VERSION "dbc-export 1 2026.26.6.5"

NS_ :

BS_:

BU_: ADSP APB APP APS APSB BB BMS CC CMP CMPD CP DAS DI DIF DIR DPB EPAS3P EPAS3S EPASTP EPASTS EPBL EPBR ESP EVSE FC GTW HCML HCMR HVP IBST ICR IDB LS OCS1P PARK PCS PCS2 PM PMF PMR PNCD PTC RADC RCM RCM2 RCM3 RCU SCCM SCM SCS SDCR TAS TCU TCU2 TPMS TRCM UI UIS UMC USM V2G VC VCBATT VCBATT0 VCBATT1 VCBATT2 VCCC VCFRONT VCFRONT1 VCFRONT2 VCLEFT VCRIGHT VCSEAT2L VCSEAT2R VCSEC VEH

BO_ 659 UI_chassisControl: 8 UI
 SG_ UI_steeringTuneRequest : 0|2@1+ (1,0) [0|3] "" Vector__XXX
 SG_ UI_tractionControlMode : 2|3@1+ (1,0) [0|7] "" Vector__XXX
 SG_ UI_parkBrakeRequest : 5|2@1+ (1,0) [0|3] "" Vector__XXX
 SG_ UI_narrowGarages : 7|1@1+ (1,0) [0|1] "" Vector__XXX
 SG_ UI_winchModeRequest : 8|2@1+ (1,0) [0|3] "" Vector__XXX
 SG_ UI_zeroSpeedConfirmed : 10|2@1+ (1,0) [0|3] "" Vector__XXX
 SG_ UI_trailerMode : 12|1@1+ (1,0) [0|1] "" Vector__XXX
 SG_ UI_distanceUnits : 13|1@1+ (1,0) [0|1] "" Vector__XXX
 SG_ UI_dasDebugEnable : 14|1@1+ (1,0) [0|1] "" Vector__XXX
 SG_ UI_accOvertakeEnable : 16|2@1+ (1,0) [0|3] "" Vector__XXX
 SG_ UI_aebEnable : 18|2@1+ (1,0) [0|3] "" Vector__XXX
 SG_ UI_aesEnable : 20|2@1+ (1,0) [0|3] "" Vector__XXX
 SG_ UI_ahlbEnable : 22|2@1+ (1,0) [0|3] "" Vector__XXX
 SG_ UI_autoLaneChangeEnable : 24|2@1+ (1,0) [0|3] "" Vector__XXX
 SG_ UI_winchProxUserOverride : 26|1@1+ (1,0) [0|1] "" Vector__XXX
 SG_ UI_rebootAutopilot : 27|1@1+ (1,0) [0|1] "" Vector__XXX
 SG_ UI_autoParkRequest : 28|4@1+ (1,0) [0|15] "" Vector__XXX
 SG_ UI_bsdEnable : 32|2@1+ (1,0) [0|3] "" Vector__XXX
 SG_ UI_fcwEnable : 34|2@1+ (1,0) [0|3] "" Vector__XXX
 SG_ UI_fcwSensitivity : 36|2@1+ (1,0) [0|3] "" Vector__XXX
 SG_ UI_latControlEnable : 38|2@1+ (1,0) [0|3] "" Vector__XXX
 SG_ UI_ldwEnable : 40|2@1+ (1,0) [0|3] "" Vector__XXX
 SG_ UI_pedalSafetyEnable : 42|2@1+ (1,0) [0|3] "" Vector__XXX
 SG_ UI_pedalMap_epas : 44|2@1+ (1,0) [0|3] "" Vector__XXX
 SG_ UI_redLightStopSignEnable : 46|2@1+ (1,0) [0|3] "" Vector__XXX
 SG_ UI_selfParkTune : 48|4@1+ (1,0) [0|15] "" Vector__XXX
 SG_ UI_chassisControlCounter : 52|4@1+ (1,0) [0|15] "" Vector__XXX
 SG_ UI_chassisControlChecksum : 56|8@1+ (1,0) [0|255] "" Vector__XXX

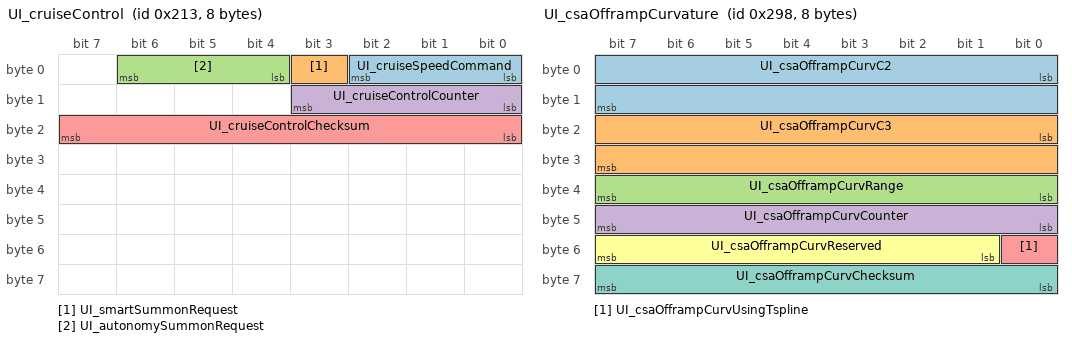
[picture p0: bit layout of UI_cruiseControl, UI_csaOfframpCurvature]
BO_ 531 UI_cruiseControl: 8 UI
 SG_ UI_cruiseSpeedCommand : 0|3@1+ (1,0) [0|7] "" Vector__XXX
 SG_ UI_smartSummonRequest : 3|1@1+ (1,0) [0|1] "" Vector__XXX
 SG_ UI_autonomySummonRequest : 4|3@1+ (1,0) [0|7] "" Vector__XXX
 SG_ UI_cruiseControlCounter : 8|4@1+ (1,0) [0|15] "" Vector__XXX
 SG_ UI_cruiseControlChecksum : 16|8@1+ (1,0) [0|255] "" Vector__XXX

BO_ 664 UI_csaOfframpCurvature: 8 UI
 SG_ UI_csaOfframpCurvC2 : 0|16@1- (1.0e-06,0) [-0.032768|0.032767] "" Vector__XXX
 SG_ UI_csaOfframpCurvC3 : 16|16@1- (4.0e-09,0) [-0.000131072|0.000131068] "" Vector__XXX
 SG_ UI_csaOfframpCurvRange : 32|8@1+ (2,0) [0|510] "" Vector__XXX
 SG_ UI_csaOfframpCurvCounter : 40|8@1+ (1,0) [0|255] "" Vector__XXX
 SG_ UI_csaOfframpCurvUsingTspline : 48|1@1+ (1,0) [0|1] "" Vector__XXX
 SG_ UI_csaOfframpCurvReserved : 49|7@1+ (1,0) [0|127] "" Vector__XXX
 SG_ UI_csaOfframpCurvChecksum : 56|8@1+ (1,0) [0|255] "" Vector__XXX

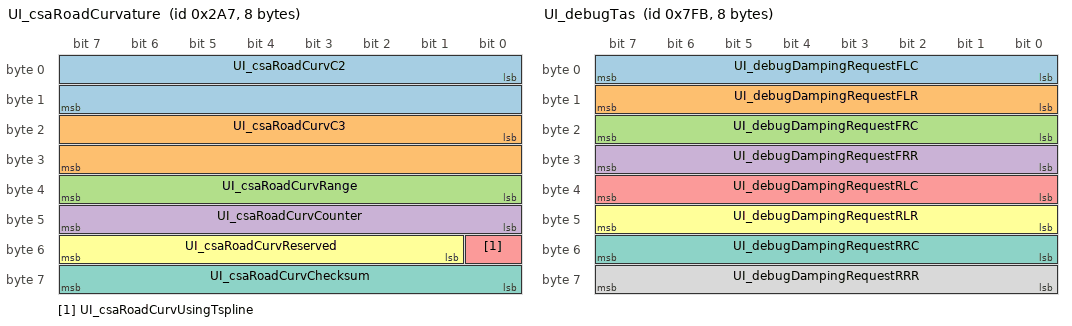
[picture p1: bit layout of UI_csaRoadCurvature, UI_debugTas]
BO_ 679 UI_csaRoadCurvature: 8 UI
 SG_ UI_csaRoadCurvC2 : 0|16@1- (1.0e-06,0) [-0.032768|0.032767] "" Vector__XXX
 SG_ UI_csaRoadCurvC3 : 16|16@1- (4.0e-09,0) [-0.000131072|0.000131068] "" Vector__XXX
 SG_ UI_csaRoadCurvRange : 32|8@1+ (2,0) [0|510] "" Vector__XXX
 SG_ UI_csaRoadCurvCounter : 40|8@1+ (1,0) [0|255] "" Vector__XXX
 SG_ UI_csaRoadCurvUsingTspline : 48|1@1+ (1,0) [0|1] "" Vector__XXX
 SG_ UI_csaRoadCurvReserved : 49|7@1+ (1,0) [0|127] "" Vector__XXX
 SG_ UI_csaRoadCurvChecksum : 56|8@1+ (1,0) [0|255] "" Vector__XXX

BO_ 1280 UI_debugECU: 8 UI
 SG_ UI_debugEcuTarget M : 0|5@1+ (1,0) [0|31] "" Vector__XXX
 SG_ UI_DI_debugEnable m1 : 8|1@1+ (1,0) [0|1] "" Vector__XXX
 SG_ UI_DIS_debugEnable m2 : 8|1@1+ (1,0) [0|1] "" Vector__XXX
 SG_ UI_PM_debugEnable m3 : 8|1@1+ (1,0) [0|1] "" Vector__XXX
 SG_ UI_PM_debugAt100Hz m3 : 9|1@1+ (1,0) [0|1] "" Vector__XXX
 SG_ UI_PMS_debugEnable m4 : 8|1@1+ (1,0) [0|1] "" Vector__XXX
 SG_ UI_PMS_debugAt100Hz m4 : 9|1@1+ (1,0) [0|1] "" Vector__XXX
 SG_ UI_BMS_debugAllEnable m5 : 8|1@1+ (1,0) [0|1] "" Vector__XXX
 SG_ UI_BMS_debugDisable m5 : 9|1@1+ (1,0) [0|1] "" Vector__XXX
 SG_ UI_VCRIGHT_debugEnable m6 : 8|1@1+ (1,0) [0|1] "" Vector__XXX
 SG_ UI_VCFRONT_debugEnable m7 : 5|1@1+ (1,0) [0|1] "" Vector__XXX
 SG_ UI_DIF_debugEnable m8 : 8|1@1+ (1,0) [0|1] "" Vector__XXX
 SG_ UI_DIR_debugEnable m9 : 8|1@1+ (1,0) [0|1] "" Vector__XXX
 SG_ UI_PMF_debugEnable m10 : 8|1@1+ (1,0) [0|1] "" Vector__XXX
 SG_ UI_PMR_debugEnable m11 : 8|1@1+ (1,0) [0|1] "" Vector__XXX

BO_ 2043 UI_debugTas: 8 UI
 SG_ UI_debugDampingRequestFLC : 0|8@1+ (0.01,0) [0|2.55] "" Vector__XXX
 SG_ UI_debugDampingRequestFLR : 8|8@1+ (0.01,0) [0|2.55] "" Vector__XXX
 SG_ UI_debugDampingRequestFRC : 16|8@1+ (0.01,0) [0|2.55] "" Vector__XXX
 SG_ UI_debugDampingRequestFRR : 24|8@1+ (0.01,0) [0|2.55] "" Vector__XXX
 SG_ UI_debugDampingRequestRLC : 32|8@1+ (0.01,0) [0|2.55] "" Vector__XXX
 SG_ UI_debugDampingRequestRLR : 40|8@1+ (0.01,0) [0|2.55] "" Vector__XXX
 SG_ UI_debugDampingRequestRRC : 48|8@1+ (0.01,0) [0|2.55] "" Vector__XXX
 SG_ UI_debugDampingRequestRRR : 56|8@1+ (0.01,0) [0|2.55] "" Vector__XXX

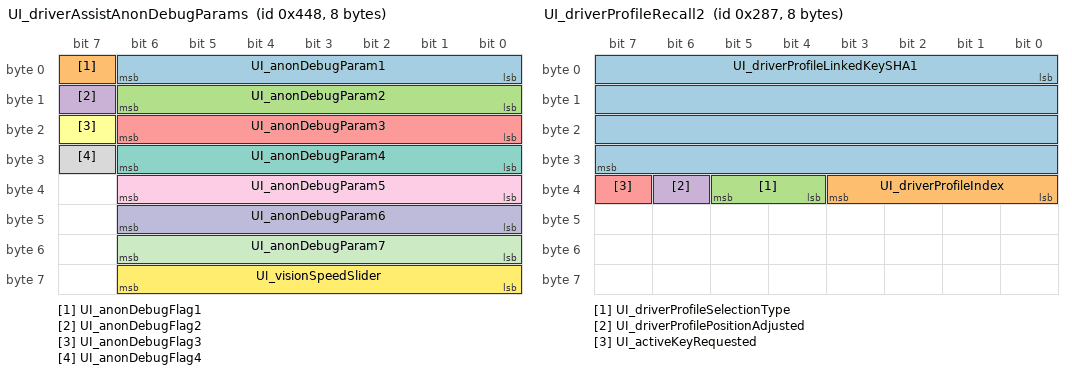
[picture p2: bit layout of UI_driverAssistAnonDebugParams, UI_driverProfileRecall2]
BO_ 1096 UI_driverAssistAnonDebugParams: 8 UI
 SG_ UI_anonDebugParam1 : 0|7@1+ (1,0) [0|127] "" Vector__XXX
 SG_ UI_anonDebugFlag1 : 7|1@1+ (1,0) [0|1] "" Vector__XXX
 SG_ UI_anonDebugParam2 : 8|7@1+ (1,0) [0|127] "" Vector__XXX
 SG_ UI_anonDebugFlag2 : 15|1@1+ (1,0) [0|1] "" Vector__XXX
 SG_ UI_anonDebugParam3 : 16|7@1+ (1,0) [0|127] "" Vector__XXX
 SG_ UI_anonDebugFlag3 : 23|1@1+ (1,0) [0|1] "" Vector__XXX
 SG_ UI_anonDebugParam4 : 24|7@1+ (1,0) [0|127] "" Vector__XXX
 SG_ UI_anonDebugFlag4 : 31|1@1+ (1,0) [0|1] "" Vector__XXX
 SG_ UI_anonDebugParam5 : 32|7@1+ (1,0) [0|127] "" Vector__XXX
 SG_ UI_anonDebugParam6 : 40|7@1+ (1,0) [0|127] "" Vector__XXX
 SG_ UI_anonDebugParam7 : 48|7@1+ (1,0) [0|127] "" Vector__XXX
 SG_ UI_visionSpeedSlider : 56|7@1+ (1,0) [0|127] "" Vector__XXX

BO_ 1016 UI_driverAssistControl: 8 UI
 SG_ UI_autopilotControlRequest : 0|1@1+ (1,0) [0|1] "" Vector__XXX
 SG_ UI_ulcStalkConfirm : 1|1@1+ (1,0) [0|1] "" Vector__XXX
 SG_ UI_summonHeartbeat : 2|2@1+ (1,0) [0|3] "" Vector__XXX
 SG_ UI_curvSpeedAdaptDisable : 4|1@1+ (1,0) [0|1] "" Vector__XXX
 SG_ UI_dasDeveloper : 5|1@1+ (1,0) [0|1] "" Vector__XXX
 SG_ UI_enableVinAssociation : 6|1@1+ (1,0) [0|1] "" Vector__XXX
 SG_ UI_lssLkaEnabled : 7|1@1+ (1,0) [0|1] "" Vector__XXX
 SG_ UI_lssLdwEnabled : 8|1@1+ (1,0) [0|1] "" Vector__XXX
 SG_ UI_coastToCoast : 9|1@1+ (1,0) [0|1] "" Vector__XXX
 SG_ UI_autoSummonEnable : 10|1@1+ (1,0) [0|1] "" Vector__XXX
 SG_ UI_exceptionListEnable : 11|1@1+ (1,0) [0|1] "" Vector__XXX
 SG_ UI_roadCheckDisable : 12|1@1+ (1,0) [0|1] "" Vector__XXX
 SG_ UI_driveOnMapsEnable : 13|1@1+ (1,0) [0|1] "" Vector__XXX
 SG_ UI_handsOnRequirementDisable : 14|1@1+ (1,0) [0|1] "" Vector__XXX
 SG_ UI_ulcOffHighway : 15|1@1+ (1,0) [0|1] "" Vector__XXX
 SG_ UI_fuseLanesDisable : 16|1@1+ (1,0) [0|1] "" Vector__XXX
 SG_ UI_fuseHPPDisable : 17|1@1+ (1,0) [0|1] "" Vector__XXX
 SG_ UI_fuseVehiclesDisable : 18|1@1+ (1,0) [0|1] "" Vector__XXX
 SG_ UI_enableClipParkedTelemetry : 19|1@1+ (1,0) [0|1] "" Vector__XXX
 SG_ UI_visionSpeedType : 20|2@1+ (1,0) [0|3] "" Vector__XXX
 SG_ UI_curvatureDatabaseOnly : 22|1@1+ (1,0) [0|1] "" Vector__XXX
 SG_ UI_lssElkEnabled : 23|1@1+ (1,0) [0|1] "" Vector__XXX
 SG_ UI_summonExitType : 24|2@1+ (1,0) [0|3] "" Vector__XXX
 SG_ UI_summonEntryType : 26|2@1+ (1,0) [0|3] "" Vector__XXX
 SG_ UI_selfParkRequest : 28|4@1+ (1,0) [0|15] "" Vector__XXX
 SG_ UI_summonReverseDist : 32|6@1+ (1,0) [0|63] "" Vector__XXX
 SG_ UI_undertakeAssistEnable : 38|1@1+ (1,0) [0|1] "" Vector__XXX
 SG_ UI_adaptiveSetSpeedEnable : 39|1@1+ (1,0) [0|1] "" Vector__XXX
 SG_ UI_drivingSide : 40|2@1+ (1,0) [0|3] "" Vector__XXX
 SG_ UI_enableClipTelemetry : 42|1@1+ (1,0) [0|1] "" Vector__XXX
 SG_ UI_enableTripTelemetry : 43|1@1+ (1,0) [0|1] "" Vector__XXX
 SG_ UI_enableRoadSegmentTelemetry : 44|1@1+ (1,0) [0|1] "" Vector__XXX
 SG_ UI_accFollowDistanceSetting : 45|3@1+ (1,0) [0|7] "" Vector__XXX
 SG_ UI_hasDriveOnNav : 48|1@1+ (1,0) [0|1] "" Vector__XXX
 SG_ UI_followNavRouteEnable : 49|1@1+ (1,0) [0|1] "" Vector__XXX
 SG_ UI_ulcSpeedConfig : 50|2@1+ (1,0) [0|3] "" Vector__XXX
 SG_ UI_ulcBlindSpotConfig : 52|2@1+ (1,0) [0|3] "" Vector__XXX
 SG_ UI_suppressExitPassingLane : 54|1@1+ (1,0) [0|1] "" Vector__XXX
 SG_ UI_enableClipStartStopTelemetry : 55|1@1+ (1,0) [0|1] "" Vector__XXX
 SG_ UI_alcOffHighwayEnable : 56|1@1+ (1,0) [0|1] "" Vector__XXX
 SG_ UI_validationLoop : 57|1@1+ (1,0) [0|1] "" Vector__XXX
 SG_ UI_smartSummonType : 58|2@1+ (1,0) [0|3] "" Vector__XXX
 SG_ UI_enableVisionOnlyStops : 60|1@1+ (1,0) [0|1] "" Vector__XXX
 SG_ UI_source3D : 61|2@1+ (1,0) [0|3] "" Vector__XXX
 SG_ UI_isaSpeedingChimeMuted : 63|1@1+ (1,0) [0|1] "" Vector__XXX

BO_ 568 UI_driverAssistMapData: 8 UI
 SG_ UI_mapSpeedLimitDependency : 0|3@1+ (1,0) [0|7] "" Vector__XXX
 SG_ UI_roadClass : 3|3@1+ (1,0) [0|7] "" Vector__XXX
 SG_ UI_inSuperchargerGeofence : 6|1@1+ (1,0) [0|1] "" Vector__XXX
 SG_ UI_mapSpeedUnits : 7|1@1+ (1,0) [0|1] "" Vector__XXX
 SG_ UI_mapSpeedLimit : 8|5@1+ (1,0) [0|31] "" Vector__XXX
 SG_ UI_mapSpeedLimitType : 13|3@1+ (1,0) [0|7] "" Vector__XXX
 SG_ UI_countryCode : 16|10@1+ (1,0) [0|1023] "" Vector__XXX
 SG_ UI_streetCount : 26|2@1+ (1,0) [0|3] "" Vector__XXX
 SG_ UI_gpsRoadMatch : 28|1@1+ (1,0) [0|1] "" Vector__XXX
 SG_ UI_navRouteActive : 29|1@1+ (1,0) [0|1] "" Vector__XXX
 SG_ UI_parallelAutoparkEnabled : 30|1@1+ (1,0) [0|1] "" Vector__XXX
 SG_ UI_perpendicularAutoparkEnabled : 31|1@1+ (1,0) [0|1] "" Vector__XXX
 SG_ UI_nextBranchDist : 32|5@1+ (10,0) [0|310] "" Vector__XXX
 SG_ UI_controlledAccess : 37|1@1+ (1,0) [0|1] "" Vector__XXX
 SG_ UI_nextBranchLeftOffRamp : 38|1@1+ (1,0) [0|1] "" Vector__XXX
 SG_ UI_nextBranchRightOffRamp : 39|1@1+ (1,0) [0|1] "" Vector__XXX
 SG_ UI_rejectLeftLane : 40|1@1+ (1,0) [0|1] "" Vector__XXX
 SG_ UI_rejectRightLane : 41|1@1+ (1,0) [0|1] "" Vector__XXX
 SG_ UI_rejectHPP : 42|1@1+ (1,0) [0|1] "" Vector__XXX
 SG_ UI_rejectNav : 43|1@1+ (1,0) [0|1] "" Vector__XXX
 SG_ UI_rejectLeftFreeSpace : 44|1@1+ (1,0) [0|1] "" Vector__XXX
 SG_ UI_rejectRightFreeSpace : 45|1@1+ (1,0) [0|1] "" Vector__XXX
 SG_ UI_rejectAutosteer : 46|1@1+ (1,0) [0|1] "" Vector__XXX
 SG_ UI_rejectHandsOn : 47|1@1+ (1,0) [0|1] "" Vector__XXX
 SG_ UI_acceptBottsDots : 48|1@1+ (1,0) [0|1] "" Vector__XXX
 SG_ UI_autosteerRestricted : 49|1@1+ (1,0) [0|1] "" Vector__XXX
 SG_ UI_pmmEnabled : 50|1@1+ (1,0) [0|1] "" Vector__XXX
 SG_ UI_scaEnabled : 51|1@1+ (1,0) [0|1] "" Vector__XXX
 SG_ UI_mapDataCounter : 52|4@1+ (1,0) [0|15] "" Vector__XXX
 SG_ UI_mapDataChecksum : 56|8@1+ (1,0) [0|255] "" Vector__XXX

BO_ 536 UI_driverAssistRoadSign: 8 UI
 SG_ UI_roadSign M : 0|8@1+ (1,0) [0|255] "" Vector__XXX
 SG_ UI_splineLocConfidence : 40|7@1+ (1,0) [0|127] "" Vector__XXX
 SG_ UI_splineID : 48|4@1+ (1,0) [0|15] "" Vector__XXX
 SG_ UI_roadSignCounter : 52|4@1+ (1,0) [0|15] "" Vector__XXX
 SG_ UI_roadSignChecksum : 56|8@1+ (1,0) [0|255] "" Vector__XXX
 SG_ UI_dummyData m0 : 8|1@1+ (1,0) [0|1] "" Vector__XXX
 SG_ UI_stopSignStopLineDist m1 : 8|10@1+ (0.25,-8) [-8|247.75] "" Vector__XXX
 SG_ UI_stopSignStopLineConf m1 : 18|7@1+ (1,0) [0|127] "" Vector__XXX
 SG_ UI_trafficLightStopLineDist m2 : 8|10@1+ (0.25,-8) [-8|247.75] "" Vector__XXX
 SG_ UI_trafficLightStopLineConf m2 : 18|7@1+ (1,0) [0|127] "" Vector__XXX
 SG_ UI_baseMapSpeedLimitMPS m3 : 8|8@1+ (0.25,0) [0|63.75] "" Vector__XXX
 SG_ UI_bottomQrtlFleetSpeedMPS m3 : 16|8@1+ (0.25,0) [0|63.75] "" Vector__XXX
 SG_ UI_topQrtlFleetSpeedMPS m3 : 24|8@1+ (0.25,0) [0|63.75] "" Vector__XXX
 SG_ UI_meanFleetSplineSpeedMPS m4 : 8|8@1+ (0.25,0) [0|63.75] "" Vector__XXX
 SG_ UI_medianFleetSpeedMPS m4 : 16|8@1+ (0.25,0) [0|63.75] "" Vector__XXX
 SG_ UI_meanFleetSplineAccelMPS2 m4 : 24|8@1+ (0.05,-6.35) [-6.35|6.4] "" Vector__XXX
 SG_ UI_rampType m4 : 32|3@1+ (1,0) [0|7] "" Vector__XXX
 SG_ UI_valhallaRamp m4 : 35|2@1+ (1,0) [0|3] "" Vector__XXX
 SG_ UI_overrideACMFleetSpeed m4 : 38|1@1+ (1,0) [0|1] "" Vector__XXX
 SG_ UI_currSplineIdFull m5 : 8|32@1+ (1,0) [0|4294967295] "" Vector__XXX

BO_ 645 UI_driverProfileRecall: 8 UI
 SG_ UI_driverProfileRecallIndex M : 0|3@1+ (1,0) [0|7] "" Vector__XXX
 SG_ UI_driverProfileRecallStop : 3|1@1+ (1,0) [0|1] "" Vector__XXX
 SG_ UI_frontSeatRecallActive m1 : 4|1@1+ (1,0) [0|1] "" Vector__XXX
 SG_ UI_frontSeatTrackPos m1 : 5|10@1- (4,0) [-2048|2044] "" Vector__XXX
 SG_ UI_frontSeatBackPos m1 : 16|12@1- (0.1,0) [-204.8|204.7] "" Vector__XXX
 SG_ UI_frontSeatLiftPos m1 : 32|10@1- (4,0) [-2048|2044] "" Vector__XXX
 SG_ UI_frontSeatTiltPos m1 : 48|12@1- (0.1,0) [-204.8|204.7] "" Vector__XXX
 SG_ UI_columnAndLumbarRecallActive m2 : 4|1@1+ (1,0) [0|1] "" Vector__XXX
 SG_ UI_steeringColumnUpDownPos m2 : 8|8@1- (1,103) [-25|230] "" Vector__XXX
 SG_ UI_lumbarAPressurePercentage m2 : 16|7@1+ (1,0) [0|127] "" Vector__XXX
 SG_ UI_lumbarBPressurePercentage m2 : 32|7@1+ (1,0) [0|127] "" Vector__XXX
 SG_ UI_steeringColumnInOutPos m2 : 48|8@1- (1,103) [-25|230] "" Vector__XXX
 SG_ UI_leftMirrorTiltXPosition m3 : 8|8@1+ (0.02,0) [0|5] "V" Vector__XXX
 SG_ UI_leftMirrorTiltYPosition m3 : 16|8@1+ (0.02,0) [0|5] "V" Vector__XXX
 SG_ UI_rightMirrorTiltXPosition m3 : 24|8@1+ (0.02,0) [0|5.1] "" Vector__XXX
 SG_ UI_rightMirrorTiltYPosition m3 : 32|8@1+ (0.02,0) [0|5.1] "" Vector__XXX
 SG_ UI_frontSeatThighSupportPos m3 : 40|8@1- (1,0) [-128|127] "" Vector__XXX
 SG_ UI_mirrorRecallActive m4 : 4|1@1+ (1,0) [0|1] "" Vector__XXX
 SG_ UI_customMirrorDipPositionsSet m4 : 5|1@1+ (1,0) [0|1] "" Vector__XXX
 SG_ UI_leftMirrorDipXPosition m4 : 8|8@1+ (0.02,0) [0|5] "V" Vector__XXX
 SG_ UI_leftMirrorDipYPosition m4 : 16|8@1+ (0.02,0) [0|5] "V" Vector__XXX
 SG_ UI_rightMirrorDipXPosition m4 : 24|8@1+ (0.02,0) [0|5.1] "" Vector__XXX
 SG_ UI_rightMirrorDipYPosition m4 : 32|8@1+ (0.02,0) [0|5.1] "" Vector__XXX
 SG_ UI_modifyMirrorDipRequest m4 : 40|2@1+ (1,0) [0|3] "" Vector__XXX

BO_ 647 UI_driverProfileRecall2: 8 UI
 SG_ UI_driverProfileLinkedKeySHA1 : 0|32@1+ (1,0) [0|4294967295] "" Vector__XXX
 SG_ UI_driverProfileIndex : 32|4@1+ (1,0) [0|15] "" Vector__XXX
 SG_ UI_driverProfileSelectionType : 36|2@1+ (1,0) [0|3] "" Vector__XXX
 SG_ UI_driverProfilePositionAdjusted : 38|1@1+ (1,0) [0|1] "" Vector__XXX
 SG_ UI_activeKeyRequested : 39|1@1+ (1,0) [0|1] "" Vector__XXX

BO_ 1971 UI_dynamicTriggersCampaignFired: 8 UI
 SG_ UI_campaignFired : 0|64@1+ (1,0) [0|1.84467440737e+19] "" Vector__XXX

BO_ 984 UI_elevationStatus: 8 UI
 SG_ UI_elevation : 0|14@1- (1,0) [-8192|8191] "" Vector__XXX
 SG_ UI_navElevation : 16|14@1- (1,0) [-8192|8191] "" Vector__XXX

BO_ 1279 UI_energyConsumptionInfo: 8 UI
 SG_ UI_energyConsumptionInfoIndex M : 0|5@1+ (1,0) [0|31] "" Vector__XXX
 SG_ UI_energyLossTotal_epa m0 : 16|16@1- (1,0) [-32768|32767] "Wh" Vector__XXX
 SG_ UI_energyLossDriving_epa m0 : 32|16@1- (1,0) [-32768|32767] "Wh" Vector__XXX
 SG_ UI_energyLossClimate_epa m0 : 48|16@1- (1,0) [-32768|32767] "Wh" Vector__XXX
 SG_ UI_energyLossBattCond_epa m1 : 16|16@1- (1,0) [-32768|32767] "Wh" Vector__XXX
 SG_ UI_energyLossElevation_epa m1 : 32|16@1- (1,0) [-32768|32767] "Wh" Vector__XXX
 SG_ UI_energyLossAcc_epa m1 : 48|16@1- (1,0) [-32768|32767] "Wh" Vector__XXX
 SG_ UI_energyLossTotalSinceCharge_ep m2 : 16|16@1- (1,0) [-32768|32767] "Wh" Vector__XXX
 SG_ UI_energyLossDrivingSinceCharge_ m2 : 32|16@1- (1,0) [-32768|32767] "Wh" Vector__XXX
 SG_ UI_energyLossClimateSinceCharge_ m2 : 48|16@1- (1,0) [-32768|32767] "Wh" Vector__XXX
 SG_ UI_energyLossBattCondSinceCharge m3 : 16|16@1- (1,0) [-32768|32767] "Wh" Vector__XXX
 SG_ UI_energyLossElevationSinceCharg m3 : 32|16@1- (1,0) [-32768|32767] "Wh" Vector__XXX
 SG_ UI_energyLossAccSinceCharge_epa m3 : 48|16@1- (1,0) [-32768|32767] "Wh" Vector__XXX
 SG_ UI_energyLossTotalSinceTripStart m4 : 16|16@1- (1,0) [-32768|32767] "Wh" Vector__XXX
 SG_ UI_energyLossDrivingSinceTripSta m4 : 32|16@1- (1,0) [-32768|32767] "Wh" Vector__XXX
 SG_ UI_energyLossClimateSinceTripSta m4 : 48|16@1- (1,0) [-32768|32767] "Wh" Vector__XXX
 SG_ UI_energyLossBattCondSinceTripSt m5 : 16|16@1- (1,0) [-32768|32767] "Wh" Vector__XXX
 SG_ UI_energyLossElevationSinceTripS m5 : 32|16@1- (1,0) [-32768|32767] "Wh" Vector__XXX
 SG_ UI_energyLossAccSinceTripStart m5 : 48|16@1- (1,0) [-32768|32767] "Wh" Vector__XXX
 SG_ UI_energyDeltaTotal_epa m6 : 16|16@1- (1,0) [-32768|32767] "Wh" Vector__XXX
 SG_ UI_energyDeltaDriving_epa m6 : 32|16@1- (1,0) [-32768|32767] "Wh" Vector__XXX
 SG_ UI_energyDeltaClimate_epa m6 : 48|16@1- (1,0) [-32768|32767] "Wh" Vector__XXX
 SG_ UI_energyDeltaBattCond_epa m7 : 16|16@1- (1,0) [-32768|32767] "Wh" Vector__XXX
 SG_ UI_energyDeltaElevation_epa m7 : 32|16@1- (1,0) [-32768|32767] "Wh" Vector__XXX
 SG_ UI_energyDeltaAcc_epa m7 : 48|16@1- (1,0) [-32768|32767] "Wh" Vector__XXX
 SG_ UI_uiDeltaOffsetTotal_epa m8 : 16|16@1- (1,0) [-32768|32767] "Wh" Vector__XXX
 SG_ UI_uiDeltaOffsetDriving_epa m8 : 32|16@1- (1,0) [-32768|32767] "Wh" Vector__XXX
 SG_ UI_uiDeltaOffsetClimate_epa m8 : 48|16@1- (1,0) [-32768|32767] "Wh" Vector__XXX
 SG_ UI_uiDeltaOffsetBattCond_epa m9 : 16|16@1- (1,0) [-32768|32767] "Wh" Vector__XXX
 SG_ UI_uiDeltaOffsetElevation_epa m9 : 32|16@1- (1,0) [-32768|32767] "Wh" Vector__XXX
 SG_ UI_uiDeltaOffsetAcc_epa m9 : 48|16@1- (1,0) [-32768|32767] "Wh" Vector__XXX
 SG_ UI_rawToUiEnergyRatio_epa m10 : 8|8@1+ (0.01,0) [0|2.55] "-" Vector__XXX
 SG_ UI_driveDistance_epa m10 : 16|16@1+ (0.01,0) [0|655.35] "miles" Vector__XXX
 SG_ UI_energyDeltaTotalSinceCharge_e m11 : 16|16@1- (1,0) [-32768|32767] "Wh" Vector__XXX
 SG_ UI_energyDeltaDrivingSinceCharge m11 : 32|16@1- (1,0) [-32768|32767] "Wh" Vector__XXX
 SG_ UI_energyDeltaClimateSinceCharge m11 : 48|16@1- (1,0) [-32768|32767] "Wh" Vector__XXX
 SG_ UI_energyDeltaBattCondSinceCharg m12 : 16|16@1- (1,0) [-32768|32767] "Wh" Vector__XXX
 SG_ UI_energyDeltaElevationSinceChar m12 : 32|16@1- (1,0) [-32768|32767] "Wh" Vector__XXX
 SG_ UI_energyDeltaAccSinceCharge_epa m12 : 48|16@1- (1,0) [-32768|32767] "Wh" Vector__XXX
 SG_ UI_uiDeltaOffsetTotalSinceCharge m13 : 16|16@1- (1,0) [-32768|32767] "Wh" Vector__XXX
 SG_ UI_uiDeltaOffsetDrivingSinceChar m13 : 32|16@1- (1,0) [-32768|32767] "Wh" Vector__XXX
 SG_ UI_uiDeltaOffsetClimateSinceChar m13 : 48|16@1- (1,0) [-32768|32767] "Wh" Vector__XXX
 SG_ UI_uiDeltaOffsetBattCondSinceCha m14 : 16|16@1- (1,0) [-32768|32767] "Wh" Vector__XXX
 SG_ UI_uiDeltaOffsetElevationSinceCh m14 : 32|16@1- (1,0) [-32768|32767] "Wh" Vector__XXX
 SG_ UI_uiDeltaOffsetAccSinceCharge_e m14 : 48|16@1- (1,0) [-32768|32767] "Wh" Vector__XXX
 SG_ UI_rawToUiEnergyRatioSinceCharge m15 : 8|8@1+ (0.01,0) [0|2.55] "-" Vector__XXX
 SG_ UI_driveDistanceSinceCharge_epa m15 : 16|16@1+ (0.01,0) [0|655.35] "miles" Vector__XXX
 SG_ UI_energyDeltaTotalSinceTripStar m16 : 16|16@1- (1,0) [-32768|32767] "Wh" Vector__XXX
 SG_ UI_energyDeltaDrivingSinceTripSt m16 : 32|16@1- (1,0) [-32768|32767] "Wh" Vector__XXX
 SG_ UI_energyDeltaClimateSinceTripSt m16 : 48|16@1- (1,0) [-32768|32767] "Wh" Vector__XXX
 SG_ UI_energyDeltaBattCondSinceTripS m17 : 16|16@1- (1,0) [-32768|32767] "Wh" Vector__XXX
 SG_ UI_energyDeltaElevationSinceTrip m17 : 32|16@1- (1,0) [-32768|32767] "Wh" Vector__XXX
 SG_ UI_energyDeltaAccSinceTripStart m17 : 48|16@1- (1,0) [-32768|32767] "Wh" Vector__XXX
 SG_ UI_uiDeltaOffsetTotalSinceTripSt m18 : 16|16@1- (1,0) [-32768|32767] "Wh" Vector__XXX
 SG_ UI_uiDeltaOffsetDrivingSinceTrip m18 : 32|16@1- (1,0) [-32768|32767] "Wh" Vector__XXX
 SG_ UI_uiDeltaOffsetClimateSinceTrip m18 : 48|16@1- (1,0) [-32768|32767] "Wh" Vector__XXX
 SG_ UI_uiDeltaOffsetBattCondSinceTri m19 : 16|16@1- (1,0) [-32768|32767] "Wh" Vector__XXX
 SG_ UI_uiDeltaOffsetElevationSinceTr m19 : 32|16@1- (1,0) [-32768|32767] "Wh" Vector__XXX
 SG_ UI_uiDeltaOffsetAccSinceTripStar m19 : 48|16@1- (1,0) [-32768|32767] "Wh" Vector__XXX
 SG_ UI_rawToUiEnergyRatioSinceTripSt m20 : 8|8@1+ (0.01,0) [0|2.55] "-" Vector__XXX
 SG_ UI_driveDistanceSinceTripStart m20 : 16|16@1+ (0.01,0) [0|655.35] "miles" Vector__XXX
 SG_ UI_voyagerEnabled m21 : 5|1@1+ (1,0) [0|1] "" Vector__XXX
 SG_ UI_trailerMass m21 : 16|16@1+ (1,0) [0|65535] "kg" Vector__XXX

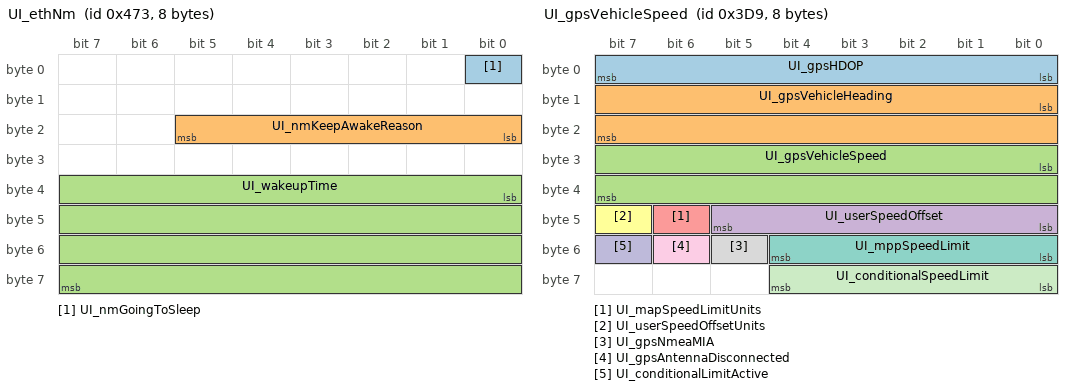
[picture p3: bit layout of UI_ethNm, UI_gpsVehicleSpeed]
BO_ 1139 UI_ethNm: 8 UI
 SG_ UI_nmGoingToSleep : 0|1@1+ (1,0) [0|1] "" Vector__XXX
 SG_ UI_nmKeepAwakeReason : 16|6@1+ (1,0) [0|63] "" Vector__XXX
 SG_ UI_wakeupTime : 32|32@1+ (1,0) [0|4294967295] "" Vector__XXX

BO_ 1267 UI_frontSeatRequests: 8 UI
 SG_ UI_frontRightSeatTrackForward : 0|1@1+ (1,0) [0|1] "" Vector__XXX
 SG_ UI_frontRightSeatTrackBack : 1|1@1+ (1,0) [0|1] "" Vector__XXX
 SG_ UI_frontLeftSeatTrackForward : 2|1@1+ (1,0) [0|1] "" Vector__XXX
 SG_ UI_frontLeftSeatTrackBack : 3|1@1+ (1,0) [0|1] "" Vector__XXX
 SG_ UI_frontRightSeatBackrestBack : 4|1@1+ (1,0) [0|1] "" Vector__XXX
 SG_ UI_frontRightSeatBackrestForward : 5|1@1+ (1,0) [0|1] "" Vector__XXX
 SG_ UI_frontLeftSeatBackrestBack : 6|1@1+ (1,0) [0|1] "" Vector__XXX
 SG_ UI_frontLeftSeatBackrestForward : 7|1@1+ (1,0) [0|1] "" Vector__XXX
 SG_ UI_frontRightSeatTiltUp : 8|1@1+ (1,0) [0|1] "" Vector__XXX
 SG_ UI_frontRightSeatTiltDown : 9|1@1+ (1,0) [0|1] "" Vector__XXX
 SG_ UI_frontLeftSeatTiltUp : 10|1@1+ (1,0) [0|1] "" Vector__XXX
 SG_ UI_frontLeftSeatTiltDown : 11|1@1+ (1,0) [0|1] "" Vector__XXX
 SG_ UI_frontRightSeatLiftUp : 12|1@1+ (1,0) [0|1] "" Vector__XXX
 SG_ UI_frontRightSeatLiftDown : 13|1@1+ (1,0) [0|1] "" Vector__XXX
 SG_ UI_frontLeftSeatLiftUp : 14|1@1+ (1,0) [0|1] "" Vector__XXX
 SG_ UI_frontLeftSeatLiftDown : 15|1@1+ (1,0) [0|1] "" Vector__XXX
 SG_ UI_frontLeftSeatLumbarUp : 16|1@1+ (1,0) [0|1] "" Vector__XXX
 SG_ UI_frontLeftSeatLumbarDown : 17|1@1+ (1,0) [0|1] "" Vector__XXX
 SG_ UI_frontRightSeatLumbarUp : 18|1@1+ (1,0) [0|1] "" Vector__XXX
 SG_ UI_frontRightSeatLumbarDown : 19|1@1+ (1,0) [0|1] "" Vector__XXX
 SG_ UI_frontLeftSeatLumbarIn : 20|1@1+ (1,0) [0|1] "" Vector__XXX
 SG_ UI_frontLeftSeatLumbarOut : 21|1@1+ (1,0) [0|1] "" Vector__XXX
 SG_ UI_frontRightSeatLumbarIn : 22|1@1+ (1,0) [0|1] "" Vector__XXX
 SG_ UI_frontRightSeatLumbarOut : 23|1@1+ (1,0) [0|1] "" Vector__XXX
 SG_ UI_seatAdjustmentSource : 24|3@1+ (1,0) [0|7] "" Vector__XXX

BO_ 993 UI_gearSliderInfo: 8 UI
 SG_ UI_gearSliderInfoIndex M : 0|2@1+ (1,0) [0|3] "" Vector__XXX
 SG_ UI_gearSliderW m0 : 2|14@1+ (1,0) [0|16383] "" Vector__XXX
 SG_ UI_gearSliderH m0 : 16|16@1+ (1,0) [0|65535] "" Vector__XXX
 SG_ UI_gearSliderX m0 : 32|16@1+ (1,0) [0|65535] "" Vector__XXX
 SG_ UI_gearSliderY m0 : 48|16@1+ (1,0) [0|65535] "" Vector__XXX
 SG_ UI_gearParkW m1 : 2|14@1+ (1,0) [0|16383] "" Vector__XXX
 SG_ UI_gearParkH m1 : 16|16@1+ (1,0) [0|65535] "" Vector__XXX
 SG_ UI_gearParkX m1 : 32|16@1+ (1,0) [0|65535] "" Vector__XXX
 SG_ UI_gearParkY m1 : 48|16@1+ (1,0) [0|65535] "" Vector__XXX
 SG_ UI_gearNeutralW m2 : 2|14@1+ (1,0) [0|16383] "" Vector__XXX
 SG_ UI_gearNeutralH m2 : 16|16@1+ (1,0) [0|65535] "" Vector__XXX
 SG_ UI_gearNeutralX m2 : 32|16@1+ (1,0) [0|65535] "" Vector__XXX
 SG_ UI_gearNeutralY m2 : 48|16@1+ (1,0) [0|65535] "" Vector__XXX

BO_ 804 UI_gpsTime: 8 UI
 SG_ UI_gpsTime : 0|64@1+ (1,0) [0|1.84467440737e+19] "" Vector__XXX

BO_ 985 UI_gpsVehicleSpeed: 8 UI
 SG_ UI_gpsHDOP : 0|8@1+ (0.1,0) [0|25.5] "" Vector__XXX
 SG_ UI_gpsVehicleHeading : 8|16@1+ (0.0078125,0) [0|511.9921875] "" Vector__XXX
 SG_ UI_gpsVehicleSpeed : 24|16@1+ (0.00390625,0) [0|255.99609375] "" Vector__XXX
 SG_ UI_userSpeedOffset : 40|6@1+ (1,-30) [-30|33] "" Vector__XXX
 SG_ UI_mapSpeedLimitUnits : 46|1@1+ (1,0) [0|1] "" Vector__XXX
 SG_ UI_userSpeedOffsetUnits : 47|1@1+ (1,0) [0|1] "" Vector__XXX
 SG_ UI_mppSpeedLimit : 48|5@1+ (5,0) [0|155] "kph/mph" Vector__XXX
 SG_ UI_gpsNmeaMIA : 53|1@1+ (1,0) [0|1] "" Vector__XXX
 SG_ UI_gpsAntennaDisconnected : 54|1@1+ (1,0) [0|1] "" Vector__XXX
 SG_ UI_conditionalLimitActive : 55|1@1+ (1,0) [0|1] "" Vector__XXX
 SG_ UI_conditionalSpeedLimit : 56|5@1+ (5,0) [0|155] "kph/mph" Vector__XXX

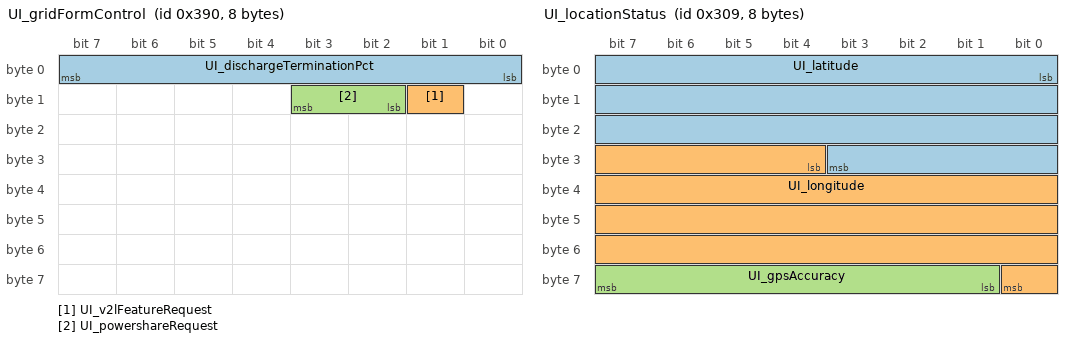
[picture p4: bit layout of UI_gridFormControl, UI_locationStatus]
BO_ 912 UI_gridFormControl: 8 UI
 SG_ UI_dischargeTerminationPct : 0|8@1+ (1,0) [0|255] "%" Vector__XXX
 SG_ UI_v2lFeatureRequest : 9|1@1+ (1,0) [0|1] "" Vector__XXX
 SG_ UI_powershareRequest : 10|2@1+ (1,0) [0|3] "" Vector__XXX

BO_ 755 UI_hvacRequest: 8 UI
 SG_ UI_hvacReqTempSetpointLeft : 0|5@1+ (0.5,15) [15|28] "degC" Vector__XXX
 SG_ UI_hvacReqAutoBlowerLevel : 5|3@1+ (1,0) [0|7] "" Vector__XXX
 SG_ UI_hvacReqTempSetpointRight : 8|5@1+ (0.5,15) [15|28] "degC" Vector__XXX
 SG_ UI_hvacReqAirDistributionMode : 13|3@1+ (1,0) [0|7] "" Vector__XXX
 SG_ UI_hvacReqBlowerSegment : 16|4@1+ (1,0) [0|15] "" Vector__XXX
 SG_ UI_hvacReqRecirc : 20|2@1+ (1,0) [0|3] "" Vector__XXX
 SG_ UI_hvacReqACDisable : 22|2@1+ (1,0) [0|3] "" Vector__XXX
 SG_ UI_hvacDefogState : 24|2@1+ (1,0) [0|3] "" Vector__XXX
 SG_ UI_hvacReqUserPowerState : 26|3@1+ (1,0) [0|7] "" Vector__XXX
 SG_ UI_hvacReqSecondRowState : 29|3@1+ (1,0) [0|7] "" Vector__XXX
 SG_ UI_hvacUseModeledDuctTemp : 32|1@1+ (1,0) [0|1] "" Vector__XXX
 SG_ UI_hvacReqKeepClimateOn : 33|2@1+ (1,0) [0|3] "" Vector__XXX
 SG_ UI_hvacReqBioWeaponDefMode : 35|1@1+ (1,0) [0|1] "" Vector__XXX
 SG_ UI_hvacLatchPassengerPresent : 39|1@1+ (1,0) [0|1] "" Vector__XXX
 SG_ UI_enableHvacControlsFeatures1 : 44|1@1+ (1,0) [0|1] "" Vector__XXX
 SG_ UI_enableHvacNotifications : 45|1@1+ (1,0) [0|1] "" Vector__XXX
 SG_ UI_hvacPhoneCallAirFlowAdjustEna : 46|1@1+ (1,0) [0|1] "" Vector__XXX
 SG_ UI_enableHvacVOCPurgeRoutine : 47|1@1+ (1,0) [0|1] "" Vector__XXX
 SG_ UI_enableCustomerTHSAlerts : 53|1@1+ (1,0) [0|1] "" Vector__XXX
 SG_ UI_evapDryingSelectiveEnable : 54|1@1+ (1,0) [0|1] "" Vector__XXX
 SG_ UI_enableHvacWeatherDataBasedHum : 55|1@1+ (1,0) [0|1] "" Vector__XXX
 SG_ UI_hvacReqTempSetpointCOP : 56|2@1+ (1,0) [0|3] "" Vector__XXX
 SG_ UI_hvacClimateNudgeStatus : 58|3@1+ (1,0) [0|7] "" Vector__XXX
 SG_ UI_enableHvacControlsFeatures2 : 61|1@1+ (1,0) [0|1] "" Vector__XXX
 SG_ UI_enableHvacAPFoggingMonitor : 62|1@1+ (1,0) [0|1] "" Vector__XXX
 SG_ UI_enableHvacLimpMode : 63|1@1+ (1,0) [0|1] "" Vector__XXX

BO_ 989 UI_locationOffset: 8 UI
 SG_ UI_latitudeOffset : 0|28@1- (1.0e-06,0) [-134.217728|134.217727] "" Vector__XXX
 SG_ UI_longitudeOffset : 28|29@1- (1.0e-06,0) [-268.435456|268.435455] "" Vector__XXX

BO_ 777 UI_locationStatus: 8 UI
 SG_ UI_latitude : 0|28@1- (1.0e-06,0) [-134.217728|134.217727] "" Vector__XXX
 SG_ UI_longitude : 28|29@1- (1.0e-06,0) [-268.435456|268.435455] "" Vector__XXX
 SG_ UI_gpsAccuracy : 57|7@1+ (0.2,0) [0|25.4] "" Vector__XXX

BO_ 1011 UI_odo: 8 UI
 SG_ UI_odometer : 0|24@1+ (0.1,0) [0|1677721.5] "km" Vector__XXX

BO_ 948 UI_peripheralPowerRequests: 8 UI
 SG_ UI_usbFrontHubPowerStateRequest : 0|2@1+ (1,0) [0|3] "" Vector__XXX

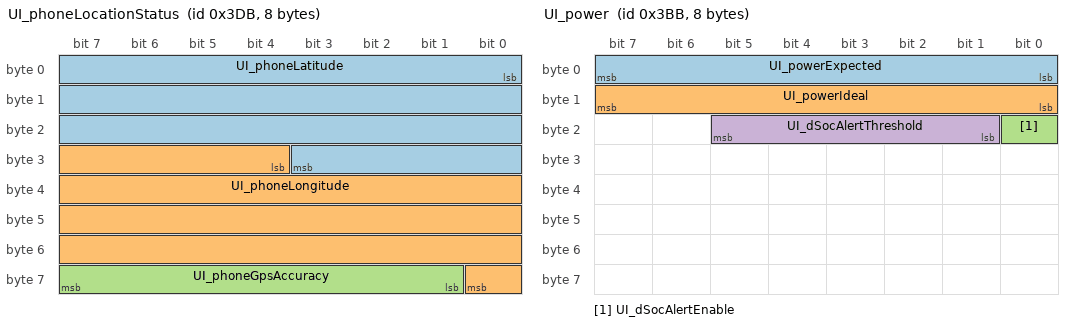
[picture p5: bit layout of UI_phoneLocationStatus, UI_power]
BO_ 987 UI_phoneLocationStatus: 8 UI
 SG_ UI_phoneLatitude : 0|28@1- (1.0e-06,0) [-134.217728|134.217727] "" Vector__XXX
 SG_ UI_phoneLongitude : 28|29@1- (1.0e-06,0) [-268.435456|268.435455] "" Vector__XXX
 SG_ UI_phoneGpsAccuracy : 57|7@1+ (0.5,0) [0|63.5] "" Vector__XXX

BO_ 955 UI_power: 8 UI
 SG_ UI_powerExpected : 0|8@1+ (1,0) [0|255] "" Vector__XXX
 SG_ UI_powerIdeal : 8|8@1+ (1,0) [0|255] "" Vector__XXX
 SG_ UI_dSocAlertEnable : 16|1@1+ (1,0) [0|1] "" Vector__XXX
 SG_ UI_dSocAlertThreshold : 17|5@1+ (0.1,-3) [-3|0.1] "" Vector__XXX

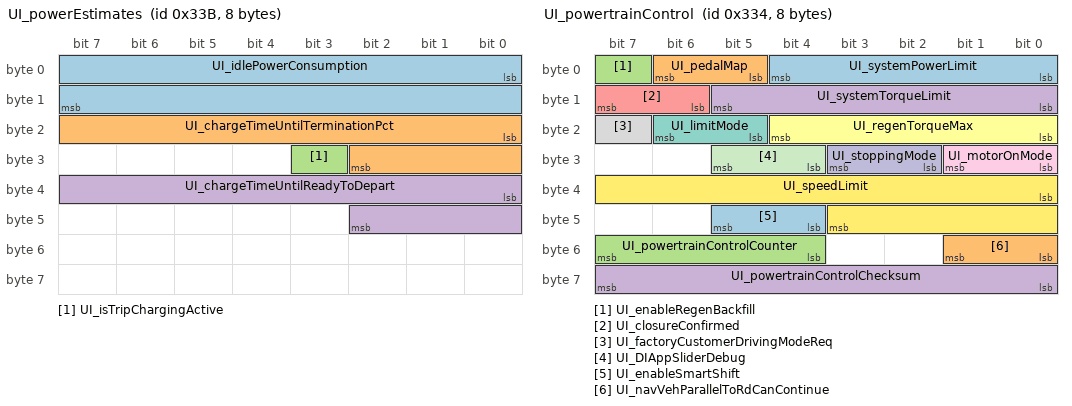
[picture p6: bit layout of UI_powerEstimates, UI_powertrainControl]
BO_ 827 UI_powerEstimates: 8 UI
 SG_ UI_idlePowerConsumption : 0|16@1+ (0.001,0) [0|50] "kW" Vector__XXX
 SG_ UI_chargeTimeUntilTerminationPct : 16|11@1+ (1,0) [0|2046] "min" Vector__XXX
 SG_ UI_isTripChargingActive : 27|1@1+ (1,0) [0|1] "" Vector__XXX
 SG_ UI_chargeTimeUntilReadyToDepart : 32|11@1+ (1,0) [0|2046] "min" Vector__XXX

BO_ 629 UI_powerRationalityConfig: 8 UI
 SG_ UI_powerRationalityConfigIndex M : 56|8@1+ (1,0) [0|255] "" Vector__XXX
 SG_ UI_vcleftCfgRationalityThreshold m0 : 0|4@1+ (1,0) [0|15] "" Vector__XXX
 SG_ UI_vcleftCfgRationalityTime0 m0 : 4|4@1+ (1,0) [0|15] "" Vector__XXX
 SG_ UI_vcleftCfgRationalityThre_0001 m0 : 8|4@1+ (1,0) [0|15] "" Vector__XXX
 SG_ UI_vcleftCfgRationalityTime1 m0 : 12|4@1+ (1,0) [0|15] "" Vector__XXX
 SG_ UI_vcleftCfgRationalityStaticA m1 : 0|16@1+ (50,0) [0|3276750] "" Vector__XXX
 SG_ UI_vcleftCfgRationalityStaticB m1 : 16|16@1- (1,0) [-32768|32767] "" Vector__XXX
 SG_ UI_vcleftCfgRationalityStaticC m1 : 32|16@1- (50,0) [-1638400|1638350] "" Vector__XXX
 SG_ UI_vcleftCfgRationalityDynamicA m2 : 0|16@1+ (50,0) [0|3276750] "" Vector__XXX
 SG_ UI_vcleftCfgRationalityDynamicB m2 : 16|16@1- (1,0) [-32768|32767] "" Vector__XXX
 SG_ UI_vcleftCfgRationalityDynamicC m2 : 32|16@1- (50,0) [-1638400|1638350] "" Vector__XXX
 SG_ UI_vcrightCfgRationalityThreshol m3 : 0|4@1+ (1,0) [0|15] "" Vector__XXX
 SG_ UI_vcrightCfgRationalityTime0 m3 : 4|4@1+ (1,0) [0|15] "" Vector__XXX
 SG_ UI_vcrightCfgRationalityThr_0001 m3 : 8|4@1+ (1,0) [0|15] "" Vector__XXX
 SG_ UI_vcrightCfgRationalityTime1 m3 : 12|4@1+ (1,0) [0|15] "" Vector__XXX
 SG_ UI_vcrightCfgRationalityStaticA m4 : 0|16@1+ (50,0) [0|3276750] "" Vector__XXX
 SG_ UI_vcrightCfgRationalityStaticB m4 : 16|16@1- (1,0) [-32768|32767] "" Vector__XXX
 SG_ UI_vcrightCfgRationalityStaticC m4 : 32|16@1- (50,0) [-1638400|1638350] "" Vector__XXX
 SG_ UI_vcrightCfgRationalityDynamicA m5 : 0|16@1+ (50,0) [0|3276750] "" Vector__XXX
 SG_ UI_vcrightCfgRationalityDynamicB m5 : 16|16@1- (1,0) [-32768|32767] "" Vector__XXX
 SG_ UI_vcrightCfgRationalityDynamicC m5 : 32|16@1- (50,0) [-1638400|1638350] "" Vector__XXX
 SG_ UI_vcleftCfgCutoffThreshold0 m6 : 0|4@1+ (1,0) [0|15] "" Vector__XXX
 SG_ UI_vcleftCfgCutoffTime0 m6 : 4|4@1+ (1,0) [0|15] "" Vector__XXX
 SG_ UI_vcleftCfgCutoffThreshold1 m6 : 8|4@1+ (1,0) [0|15] "" Vector__XXX
 SG_ UI_vcleftCfgCutoffTime1 m6 : 12|4@1+ (1,0) [0|15] "" Vector__XXX
 SG_ UI_vcleftCfgCutoffStaticA m7 : 0|16@1+ (50,0) [0|3276750] "" Vector__XXX
 SG_ UI_vcleftCfgCutoffStaticB m7 : 16|16@1- (1,0) [-32768|32767] "" Vector__XXX
 SG_ UI_vcleftCfgCutoffStaticC m7 : 32|16@1- (50,0) [-1638400|1638350] "" Vector__XXX
 SG_ UI_vcleftCfgCutoffDynamicA m8 : 0|16@1+ (50,0) [0|3276750] "" Vector__XXX
 SG_ UI_vcleftCfgCutoffDynamicB m8 : 16|16@1- (1,0) [-32768|32767] "" Vector__XXX
 SG_ UI_vcleftCfgCutoffDynamicC m8 : 32|16@1- (50,0) [-1638400|1638350] "" Vector__XXX
 SG_ UI_vcrightCfgCutoffThreshold0 m9 : 0|4@1+ (1,0) [0|15] "" Vector__XXX
 SG_ UI_vcrightCfgCutoffTime0 m9 : 4|4@1+ (1,0) [0|15] "" Vector__XXX
 SG_ UI_vcrightCfgCutoffThreshold1 m9 : 8|4@1+ (1,0) [0|15] "" Vector__XXX
 SG_ UI_vcrightCfgCutoffTime1 m9 : 12|4@1+ (1,0) [0|15] "" Vector__XXX
 SG_ UI_vcrightCfgCutoffStaticA m10 : 0|16@1+ (50,0) [0|3276750] "" Vector__XXX
 SG_ UI_vcrightCfgCutoffStaticB m10 : 16|16@1- (1,0) [-32768|32767] "" Vector__XXX
 SG_ UI_vcrightCfgCutoffStaticC m10 : 32|16@1- (50,0) [-1638400|1638350] "" Vector__XXX
 SG_ UI_vcrightCfgCutoffDynamicA m11 : 0|16@1+ (50,0) [0|3276750] "" Vector__XXX
 SG_ UI_vcrightCfgCutoffDynamicB m11 : 16|16@1- (1,0) [-32768|32767] "" Vector__XXX
 SG_ UI_vcrightCfgCutoffDynamicC m11 : 32|16@1- (50,0) [-1638400|1638350] "" Vector__XXX

BO_ 820 UI_powertrainControl: 8 UI
 SG_ UI_systemPowerLimit : 0|5@1+ (20,20) [20|640] "" Vector__XXX
 SG_ UI_pedalMap : 5|2@1+ (1,0) [0|3] "" Vector__XXX
 SG_ UI_enableRegenBackfill : 7|1@1+ (1,0) [0|1] "" Vector__XXX
 SG_ UI_systemTorqueLimit : 8|6@1+ (150,1000) [1000|10450] "" Vector__XXX
 SG_ UI_closureConfirmed : 14|2@1+ (1,0) [0|3] "" Vector__XXX
 SG_ UI_regenTorqueMax : 16|5@1+ (5,0) [0|100] "%" Vector__XXX
 SG_ UI_limitMode : 21|2@1+ (1,0) [0|3] "" Vector__XXX
 SG_ UI_factoryCustomerDrivingModeReq : 23|1@1+ (1,0) [0|1] "" Vector__XXX
 SG_ UI_motorOnMode : 24|2@1+ (1,0) [0|3] "" Vector__XXX
 SG_ UI_stoppingMode : 26|2@1+ (1,0) [0|3] "" Vector__XXX
 SG_ UI_DIAppSliderDebug : 28|2@1+ (1,0) [0|3] "" Vector__XXX
 SG_ UI_speedLimit : 32|12@1+ (0.1,0) [0|335] "kph" Vector__XXX
 SG_ UI_enableSmartShift : 44|2@1+ (1,0) [0|3] "" Vector__XXX
 SG_ UI_navVehParallelToRdCanContinue : 48|2@1+ (1,0) [0|3] "" Vector__XXX
 SG_ UI_powertrainControlCounter : 52|4@1+ (1,0) [0|15] "" Vector__XXX
 SG_ UI_powertrainControlChecksum : 56|8@1+ (1,0) [0|255] "" Vector__XXX

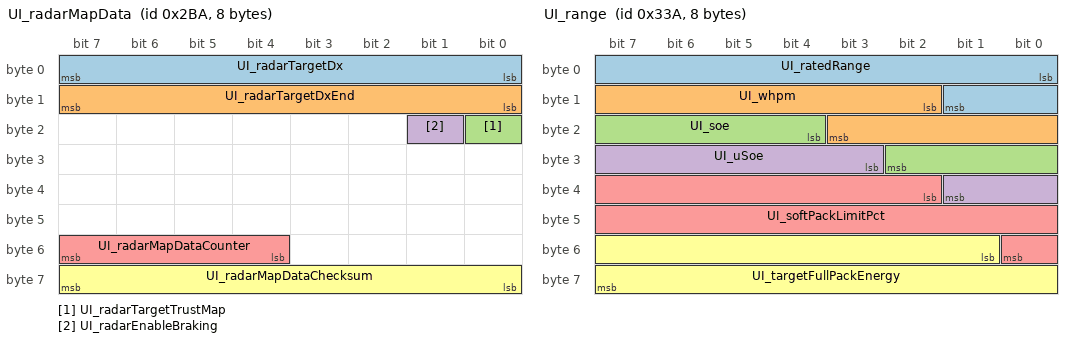
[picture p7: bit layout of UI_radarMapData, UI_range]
BO_ 698 UI_radarMapData: 8 UI
 SG_ UI_radarTargetDx : 0|8@1+ (1,-95) [-95|160] "" Vector__XXX
 SG_ UI_radarTargetDxEnd : 8|8@1+ (1,0) [0|255] "" Vector__XXX
 SG_ UI_radarTargetTrustMap : 16|1@1+ (1,0) [0|1] "" Vector__XXX
 SG_ UI_radarEnableBraking : 17|1@1+ (1,0) [0|1] "" Vector__XXX
 SG_ UI_radarMapDataCounter : 52|4@1+ (1,0) [0|15] "" Vector__XXX
 SG_ UI_radarMapDataChecksum : 56|8@1+ (1,0) [0|255] "" Vector__XXX

BO_ 826 UI_range: 8 UI
 SG_ UI_ratedRange : 0|10@1+ (1,0) [0|1023] "mi" Vector__XXX
 SG_ UI_whpm : 10|10@1+ (1,0) [0|1023] "" Vector__XXX
 SG_ UI_soe : 20|7@1+ (1,0) [0|127] "%" Vector__XXX
 SG_ UI_uSoe : 27|7@1+ (1,0) [0|127] "%" Vector__XXX
 SG_ UI_softPackLimitPct : 34|15@1+ (0.003051851,0) [0|100.000001717] "" Vector__XXX
 SG_ UI_targetFullPackEnergy : 49|15@1+ (0.006103702,0) [0|200.000003434] "" Vector__XXX

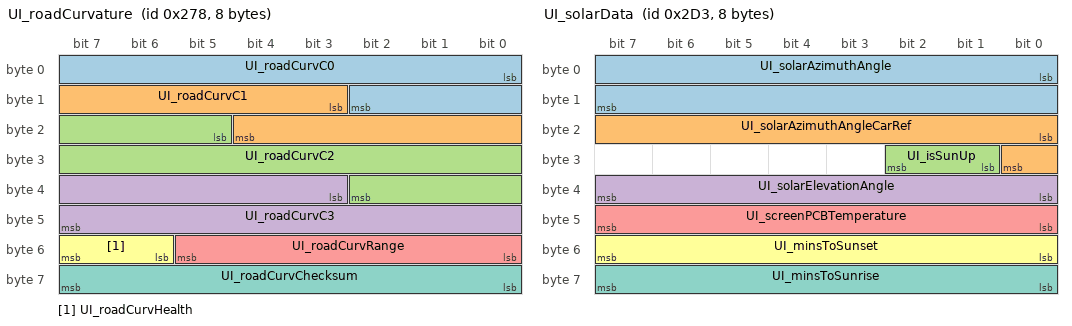
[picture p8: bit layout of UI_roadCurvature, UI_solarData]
BO_ 632 UI_roadCurvature: 8 UI
 SG_ UI_roadCurvC0 : 0|11@1- (0.02,0) [-20.48|20.46] "" Vector__XXX
 SG_ UI_roadCurvC1 : 11|10@1- (0.00075,0) [-0.384|0.38325] "" Vector__XXX
 SG_ UI_roadCurvC2 : 21|14@1- (7.5e-06,0) [-0.06144|0.0614325] "" Vector__XXX
 SG_ UI_roadCurvC3 : 35|13@1- (3.0e-08,0) [-0.00012288|0.00012285] "" Vector__XXX
 SG_ UI_roadCurvRange : 48|6@1+ (4,0) [0|252] "" Vector__XXX
 SG_ UI_roadCurvHealth : 54|2@1+ (1,0) [0|3] "" Vector__XXX
 SG_ UI_roadCurvChecksum : 56|8@1+ (1,0) [0|255] "" Vector__XXX

BO_ 666 UI_seatControl: 8 UI
 SG_ UI_seatControlIndex M : 0|2@1+ (1,0) [0|3] "" Vector__XXX
 SG_ UI_3RSeatChildLock m0 : 2|2@1+ (1,0) [0|3] "" Vector__XXX
 SG_ UI_2RowLeftSeatTrackBack m0 : 4|1@1+ (1,0) [0|1] "" Vector__XXX
 SG_ UI_2RowLeftSeatTrackForward m0 : 5|1@1+ (1,0) [0|1] "" Vector__XXX
 SG_ UI_2RowRightSeatTrackBack m0 : 6|1@1+ (1,0) [0|1] "" Vector__XXX
 SG_ UI_2RowRightSeatTrackForward m0 : 7|1@1+ (1,0) [0|1] "" Vector__XXX
 SG_ UI_left3RowSeatAdjustmentRequest m0 : 8|3@1+ (1,0) [0|7] "" Vector__XXX
 SG_ UI_right3RowSeatAdjustmentReques m0 : 11|3@1+ (1,0) [0|7] "" Vector__XXX
 SG_ UI_2RLeftSeatFanReq m0 : 14|2@1+ (1,0) [0|3] "" Vector__XXX
 SG_ UI_2RRightSeatFanReq m0 : 16|2@1+ (1,0) [0|3] "" Vector__XXX
 SG_ UI_leftThirdRowSeatRequestFromRe m0 : 18|1@1+ (1,0) [0|1] "" Vector__XXX
 SG_ UI_rightThirdRowSeatRequestFromR m0 : 19|1@1+ (1,0) [0|1] "" Vector__XXX
 SG_ UI_seatChoreographyStopRequest m0 : 20|1@1+ (1,0) [0|1] "" Vector__XXX

BO_ 723 UI_solarData: 8 UI
 SG_ UI_solarAzimuthAngle : 0|16@1- (1,0) [-32768|32767] "" Vector__XXX
 SG_ UI_solarAzimuthAngleCarRef : 16|9@1- (1,0) [-256|255] "" Vector__XXX
 SG_ UI_isSunUp : 25|2@1+ (1,0) [0|3] "" Vector__XXX
 SG_ UI_solarElevationAngle : 32|8@1- (1,0) [-128|126] "degrees" Vector__XXX
 SG_ UI_screenPCBTemperature : 40|8@1- (0.5,40) [-20|100] "degC" Vector__XXX
 SG_ UI_minsToSunset : 48|8@1+ (10,0) [0|2550] "min" Vector__XXX
 SG_ UI_minsToSunrise : 56|8@1+ (10,0) [0|2550] "min" Vector__XXX

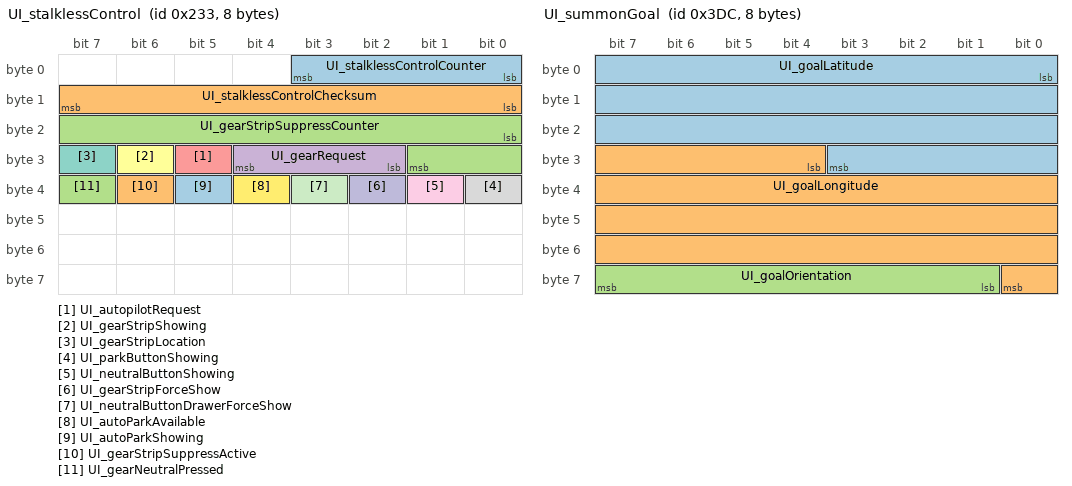
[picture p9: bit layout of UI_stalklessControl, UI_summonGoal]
BO_ 563 UI_stalklessControl: 8 UI
 SG_ UI_stalklessControlCounter : 0|4@1+ (1,0) [0|15] "" Vector__XXX
 SG_ UI_stalklessControlChecksum : 8|8@1+ (1,0) [0|255] "" Vector__XXX
 SG_ UI_gearStripSuppressCounter : 16|10@1+ (1,0) [0|1023] "" Vector__XXX
 SG_ UI_gearRequest : 26|3@1+ (1,0) [0|7] "" Vector__XXX
 SG_ UI_autopilotRequest : 29|1@1+ (1,0) [0|1] "" Vector__XXX
 SG_ UI_gearStripShowing : 30|1@1+ (1,0) [0|1] "" Vector__XXX
 SG_ UI_gearStripLocation : 31|1@1+ (1,0) [0|1] "" Vector__XXX
 SG_ UI_parkButtonShowing : 32|1@1+ (1,0) [0|1] "" Vector__XXX
 SG_ UI_neutralButtonShowing : 33|1@1+ (1,0) [0|1] "" Vector__XXX
 SG_ UI_gearStripForceShow : 34|1@1+ (1,0) [0|1] "" Vector__XXX
 SG_ UI_neutralButtonDrawerForceShow : 35|1@1+ (1,0) [0|1] "" Vector__XXX
 SG_ UI_autoParkAvailable : 36|1@1+ (1,0) [0|1] "" Vector__XXX
 SG_ UI_autoParkShowing : 37|1@1+ (1,0) [0|1] "" Vector__XXX
 SG_ UI_gearStripSuppressActive : 38|1@1+ (1,0) [0|1] "" Vector__XXX
 SG_ UI_gearNeutralPressed : 39|1@1+ (1,0) [0|1] "" Vector__XXX

BO_ 851 UI_status: 8 UI
 SG_ UI_touchActive : 0|1@1+ (1,0) [0|1] "" Vector__XXX
 SG_ UI_audioActive : 1|1@1+ (1,0) [0|1] "" Vector__XXX
 SG_ UI_bluetoothActive : 2|1@1+ (1,0) [0|1] "" Vector__XXX
 SG_ UI_cellActive : 3|1@1+ (1,0) [0|1] "" Vector__XXX
 SG_ UI_displayReady : 4|1@1+ (1,0) [0|1] "" Vector__XXX
 SG_ UI_displayOn : 5|1@1+ (1,0) [0|1] "" Vector__XXX
 SG_ UI_wifiActive : 6|1@1+ (1,0) [0|1] "" Vector__XXX
 SG_ UI_wifiConnected : 7|1@1+ (1,0) [0|1] "" Vector__XXX
 SG_ UI_systemActive : 8|1@1+ (1,0) [0|1] "" Vector__XXX
 SG_ UI_readyForDrive : 9|1@1+ (1,0) [0|1] "" Vector__XXX
 SG_ UI_cellConnected : 10|1@1+ (1,0) [0|1] "" Vector__XXX
 SG_ UI_vpnActive : 11|1@1+ (1,0) [0|1] "" Vector__XXX
 SG_ UI_autopilotTrial : 12|2@1+ (1,0) [0|3] "" Vector__XXX
 SG_ UI_factoryReset : 14|2@1+ (1,0) [0|3] "" Vector__XXX
 SG_ UI_gpsActive : 16|1@1+ (1,0) [0|1] "" Vector__XXX
 SG_ UI_screenshotActive : 17|1@1+ (1,0) [0|1] "" Vector__XXX
 SG_ UI_radioActive : 18|1@1+ (1,0) [0|1] "" Vector__XXX
 SG_ UI_cellNetworkTechnology : 19|4@1+ (1,0) [0|15] "" Vector__XXX
 SG_ UI_cellReceiverPower : 24|8@1+ (1,-128) [-128|127] "" Vector__XXX
 SG_ UI_falseTouchCounter : 32|8@1+ (1,0) [0|255] "1" Vector__XXX
 SG_ UI_developmentCar : 40|1@1+ (1,0) [0|1] "" Vector__XXX
 SG_ UI_cameraActive : 41|1@1+ (1,0) [0|1] "" Vector__XXX
 SG_ UI_cellSignalBars : 42|3@1+ (1,0) [0|7] "" Vector__XXX
 SG_ UI_trailerModeTelltale : 45|2@1+ (1,0) [0|3] "" Vector__XXX
 SG_ UI_pcbTemperature : 48|8@1- (1,40) [-20|100] "degC" Vector__XXX
 SG_ UI_cpuTemperature : 56|8@1- (1,40) [-20|100] "degC" Vector__XXX

BO_ 991 UI_status2: 8 UI
 SG_ UI_mobileAppStepCount : 0|16@1+ (1,0) [0|65535] "" Vector__XXX
 SG_ UI_userRequestSnapshot : 16|1@1+ (1,0) [0|1] "" Vector__XXX
 SG_ UI_touchDetected : 17|1@1+ (1,0) [0|1] "" Vector__XXX
 SG_ UI_validDeviceForEUSummon : 18|1@1+ (1,0) [0|1] "" Vector__XXX
 SG_ UI_locatedAtHome : 19|1@1+ (1,0) [0|1] "" Vector__XXX
 SG_ UI_locatedAtWork : 20|1@1+ (1,0) [0|1] "" Vector__XXX
 SG_ UI_locatedAtFavorite : 21|1@1+ (1,0) [0|1] "" Vector__XXX
 SG_ UI_displayInDarkMode : 22|1@1+ (1,0) [0|1] "" Vector__XXX
 SG_ UI_userActivity : 23|1@1+ (1,0) [0|1] "" Vector__XXX
 SG_ UI_activeTouchPoints : 24|8@1+ (1,0) [0|255] "1" Vector__XXX
 SG_ UI_linkState : 32|2@1+ (1,0) [0|3] "" Vector__XXX
 SG_ UI_sentryModeState : 34|3@1+ (1,0) [0|7] "" Vector__XXX
 SG_ UI_autopilotSentryRequest : 37|1@1+ (1,0) [0|1] "" Vector__XXX
 SG_ UI_mobileAppConnected : 38|1@1+ (1,0) [0|1] "" Vector__XXX
 SG_ UI_phoneLeftInCabin : 39|1@1+ (1,0) [0|1] "" Vector__XXX
 SG_ UI_autoshiftDRState : 40|3@1+ (1,0) [0|7] "" Vector__XXX
 SG_ UI_wifiBtModuleType : 43|3@1+ (1,0) [0|7] "" Vector__XXX
 SG_ UI_sohHealthStatus : 46|2@1+ (1,0) [0|3] "" Vector__XXX
 SG_ UI_selfParkState : 48|8@1+ (1,0) [0|255] "" Vector__XXX
 SG_ UI_summonDeviceIndex : 56|2@1+ (1,0) [0|3] "" Vector__XXX
 SG_ UI_fullScreenMode : 58|1@1+ (1,0) [0|1] "" Vector__XXX
 SG_ UI_sentryModeCameraDetection : 59|1@1+ (1,0) [0|1] "" Vector__XXX
 SG_ UI_wakeOnIPActive : 60|1@1+ (1,0) [0|1] "" Vector__XXX
 SG_ UI_sapActive : 61|1@1+ (1,0) [0|1] "" Vector__XXX
 SG_ UI_sapClients : 62|1@1+ (1,0) [0|1] "" Vector__XXX
 SG_ UI_connectivityStandbyActive : 63|1@1+ (1,0) [0|1] "" Vector__XXX

BO_ 986 UI_status3: 8 UI
 SG_ UI_wifiRegDomain : 0|7@1+ (1,0) [0|127] "" Vector__XXX
 SG_ UI_wifiTethered : 7|1@1+ (1,0) [0|1] "" Vector__XXX

BO_ 988 UI_summonGoal: 8 UI
 SG_ UI_goalLatitude : 0|28@1- (1.0e-06,0) [-134.217728|134.217727] "" Vector__XXX
 SG_ UI_goalLongitude : 28|29@1- (1.0e-06,0) [-268.435456|268.435455] "" Vector__XXX
 SG_ UI_goalOrientation : 57|7@1+ (2.8125,0) [0|357.1875] "" Vector__XXX

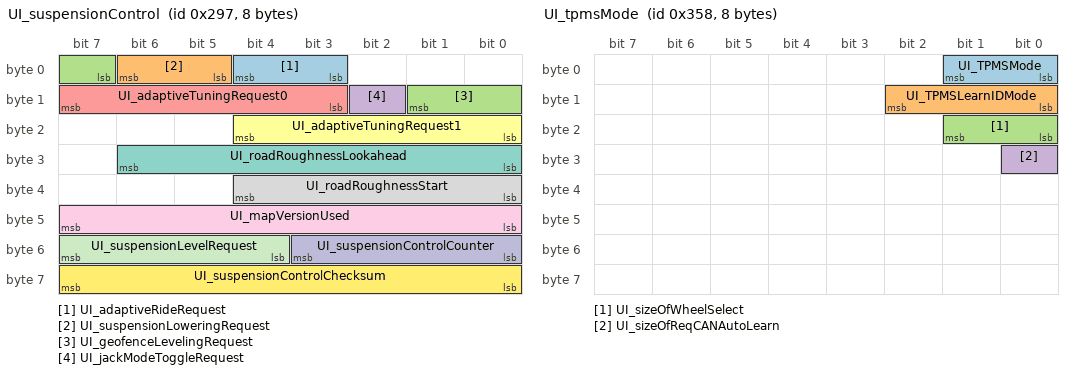
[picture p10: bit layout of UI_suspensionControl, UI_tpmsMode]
BO_ 663 UI_suspensionControl: 8 UI
 SG_ UI_adaptiveRideRequest : 3|2@1+ (1,0) [0|3] "" Vector__XXX
 SG_ UI_suspensionLoweringRequest : 5|2@1+ (1,0) [0|3] "" Vector__XXX
 SG_ UI_geofenceLevelingRequest : 7|3@1+ (1,0) [0|7] "" Vector__XXX
 SG_ UI_jackModeToggleRequest : 10|1@1+ (1,0) [0|1] "" Vector__XXX
 SG_ UI_adaptiveTuningRequest0 : 11|5@1- (0.1,0) [-1.6|1.5] "" Vector__XXX
 SG_ UI_adaptiveTuningRequest1 : 16|5@1- (0.1,0) [-1.6|1.5] "" Vector__XXX
 SG_ UI_roadRoughnessLookahead : 24|7@1+ (0.01,0) [0|1.27] "" Vector__XXX
 SG_ UI_roadRoughnessStart : 32|5@1+ (10,0) [0|310] "" Vector__XXX
 SG_ UI_mapVersionUsed : 40|8@1+ (1,0) [0|255] "" Vector__XXX
 SG_ UI_suspensionControlCounter : 48|4@1+ (1,0) [0|15] "" Vector__XXX
 SG_ UI_suspensionLevelRequest : 52|4@1+ (1,0) [0|15] "" Vector__XXX
 SG_ UI_suspensionControlChecksum : 56|8@1+ (1,0) [0|255] "" Vector__XXX

BO_ 661 UI_systemMonitor: 8 UI
 SG_ UI_systemMonitorIndex M : 0|1@1+ (1,0) [0|1] "" Vector__XXX
 SG_ UI_SystemMemUsage m0 : 8|16@1+ (1,0) [0|65535] "MB" Vector__XXX
 SG_ UI_QtCarMemUsage m0 : 24|16@1+ (1,0) [0|65535] "MB" Vector__XXX
 SG_ UI_QtCarCPUUsage m0 : 40|7@1+ (1,0) [0|127] "%" Vector__XXX
 SG_ UI_emmcStatus m0 : 47|1@1+ (1,0) [0|1] "" Vector__XXX
 SG_ UI_SystemCPUUsage m0 : 48|7@1+ (1,0) [0|127] "%" Vector__XXX
 SG_ UI_HomeHealth m0 : 55|1@1+ (1,0) [0|1] "" Vector__XXX
 SG_ UI_VarHealth m0 : 56|1@1+ (1,0) [0|1] "" Vector__XXX
 SG_ UI_LogHealth m0 : 57|1@1+ (1,0) [0|1] "" Vector__XXX
 SG_ UI_TmpfsHealth m0 : 58|1@1+ (1,0) [0|1] "" Vector__XXX
 SG_ UI_emmcDataWritten m1 : 8|24@1+ (1,0) [0|16777215] "" Vector__XXX
 SG_ UI_emmcTotalErases m1 : 32|16@1+ (1,0) [0|65535] "" Vector__XXX

BO_ 1064 UI_telemetryControl: 8 UI
 SG_ UI_TCR_enable : 0|1@1+ (1,0) [0|1] "" Vector__XXX
 SG_ UI_TCR_moveStateStanding : 1|1@1+ (1,0) [0|1] "" Vector__XXX
 SG_ UI_TCR_moveStateStopped : 2|1@1+ (1,0) [0|1] "" Vector__XXX
 SG_ UI_TCR_moveStateMoving : 3|1@1+ (1,0) [0|1] "" Vector__XXX
 SG_ UI_TCR_moveStateIndeterm : 4|1@1+ (1,0) [0|1] "" Vector__XXX
 SG_ UI_TCR_classConstElem : 5|1@1+ (1,0) [0|1] "" Vector__XXX
 SG_ UI_TCR_classMovingPed : 6|1@1+ (1,0) [0|1] "" Vector__XXX
 SG_ UI_TCR_classMovingTwoWheel : 7|1@1+ (1,0) [0|1] "" Vector__XXX
 SG_ UI_TCR_classMovingFourWheel : 8|1@1+ (1,0) [0|1] "" Vector__XXX
 SG_ UI_TCR_classUnknown : 9|1@1+ (1,0) [0|1] "" Vector__XXX
 SG_ UI_TCR_downSampleFactor : 10|4@1+ (1,0) [0|15] "" Vector__XXX
 SG_ UI_TCR_wExist : 24|5@1+ (1,0) [0|31] "" Vector__XXX
 SG_ UI_TCR_vehSpeed : 32|8@1+ (1,0) [0|255] "" Vector__XXX
 SG_ UI_TCR_minRCS : 40|8@1+ (0.25,-14) [-14|49.75] "" Vector__XXX
 SG_ UI_TCR_maxDy : 48|5@1+ (0.5,0) [0|15.5] "" Vector__XXX
 SG_ UI_TCR_maxObjects : 56|5@1+ (1,0) [0|31] "" Vector__XXX
 SG_ UI_TCR_maxRoadClass : 61|3@1+ (1,0) [0|7] "" Vector__XXX

BO_ 856 UI_tpmsMode: 8 UI
 SG_ UI_TPMSMode : 0|2@1+ (1,0) [0|3] "" Vector__XXX
 SG_ UI_TPMSLearnIDMode : 8|3@1+ (1,0) [0|7] "" Vector__XXX
 SG_ UI_sizeOfWheelSelect : 16|2@1+ (1,0) [0|3] "" Vector__XXX
 SG_ UI_sizeOfReqCANAutoLearn : 24|1@1+ (1,0) [0|1] "" Vector__XXX

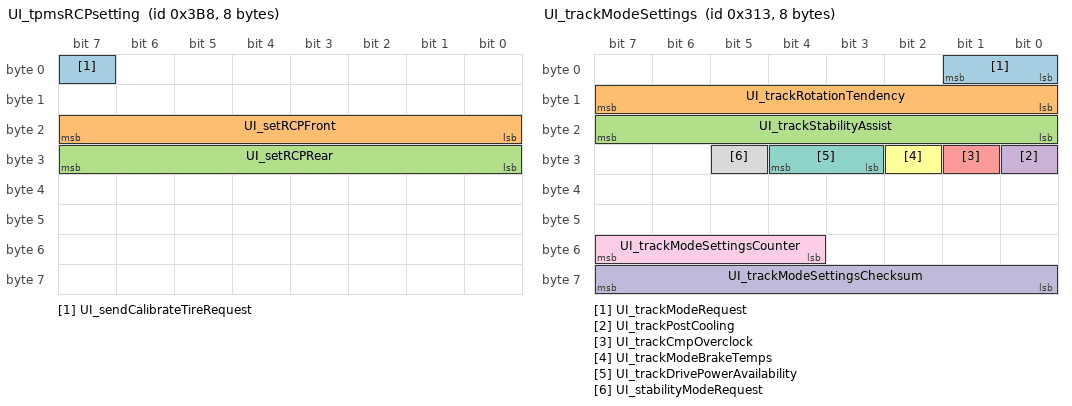
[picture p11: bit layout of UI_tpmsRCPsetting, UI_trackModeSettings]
BO_ 952 UI_tpmsRCPsetting: 8 UI
 SG_ UI_sendCalibrateTireRequest : 7|1@1+ (1,0) [0|1] "" Vector__XXX
 SG_ UI_setRCPFront : 16|8@1+ (0.025,0) [0|6.375] "" Vector__XXX
 SG_ UI_setRCPRear : 24|8@1+ (0.025,0) [0|6.375] "" Vector__XXX

BO_ 787 UI_trackModeSettings: 8 UI
 SG_ UI_trackModeRequest : 0|2@1+ (1,0) [0|3] "" Vector__XXX
 SG_ UI_trackRotationTendency : 8|8@1+ (0.5,0) [0|127.5] "" Vector__XXX
 SG_ UI_trackStabilityAssist : 16|8@1+ (0.5,0) [0|127.5] "" Vector__XXX
 SG_ UI_trackPostCooling : 24|1@1+ (1,0) [0|1] "" Vector__XXX
 SG_ UI_trackCmpOverclock : 25|1@1+ (1,0) [0|1] "" Vector__XXX
 SG_ UI_trackModeBrakeTemps : 26|1@1+ (1,0) [0|1] "" Vector__XXX
 SG_ UI_trackDrivePowerAvailability : 27|2@1+ (1,0) [0|3] "" Vector__XXX
 SG_ UI_stabilityModeRequest : 29|1@1+ (1,0) [0|1] "" Vector__XXX
 SG_ UI_trackModeSettingsCounter : 52|4@1+ (1,0) [0|15] "" Vector__XXX
 SG_ UI_trackModeSettingsChecksum : 56|8@1+ (1,0) [0|255] "" Vector__XXX

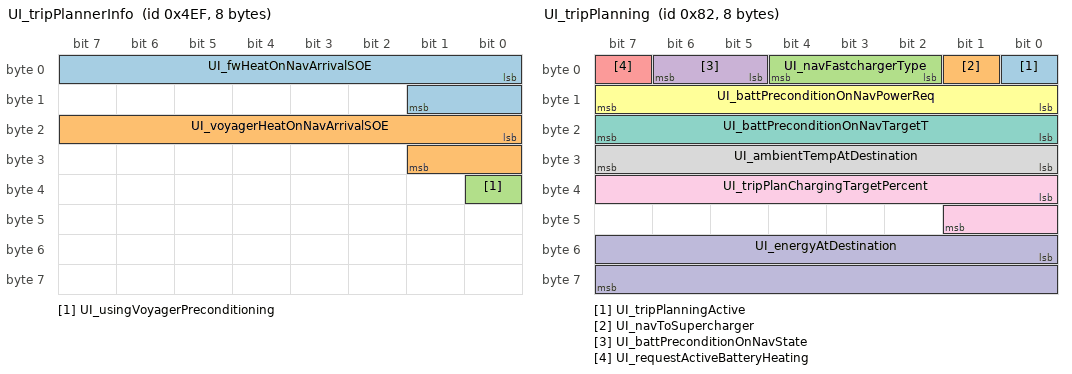
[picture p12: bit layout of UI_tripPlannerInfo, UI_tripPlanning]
BO_ 1263 UI_tripPlannerInfo: 8 UI
 SG_ UI_fwHeatOnNavArrivalSOE : 0|10@1+ (0.1,0) [0|100] "%" Vector__XXX
 SG_ UI_voyagerHeatOnNavArrivalSOE : 16|10@1+ (0.1,0) [0|100] "%" Vector__XXX
 SG_ UI_usingVoyagerPreconditioning : 32|1@1+ (1,0) [0|1] "" Vector__XXX

BO_ 130 UI_tripPlanning: 8 UI
 SG_ UI_tripPlanningActive : 0|1@1+ (1,0) [0|1] "" Vector__XXX
 SG_ UI_navToSupercharger : 1|1@1+ (1,0) [0|1] "" Vector__XXX
 SG_ UI_navFastchargerType : 2|3@1+ (1,0) [0|7] "" Vector__XXX
 SG_ UI_battPreconditionOnNavState : 5|2@1+ (1,0) [0|3] "" Vector__XXX
 SG_ UI_requestActiveBatteryHeating : 7|1@1+ (1,0) [0|1] "" Vector__XXX
 SG_ UI_battPreconditionOnNavPowerReq : 8|8@1- (125,0) [-16000|15750] "W" Vector__XXX
 SG_ UI_battPreconditionOnNavTargetT : 16|8@1+ (0.25,0) [0|63.5] "degC" Vector__XXX
 SG_ UI_ambientTempAtDestination : 24|8@1- (0.5,0) [-64|63.5] "" Vector__XXX
 SG_ UI_tripPlanChargingTargetPercent : 32|10@1+ (0.1,0) [0|102.3] "" Vector__XXX
 SG_ UI_energyAtDestination : 48|16@1- (0.01,0) [-327.67|327.67] "kWh" Vector__XXX

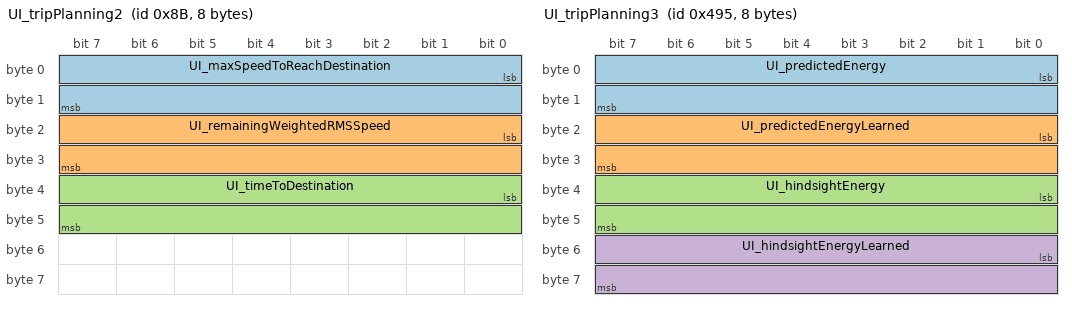
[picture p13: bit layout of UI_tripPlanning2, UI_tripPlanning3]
BO_ 139 UI_tripPlanning2: 8 UI
 SG_ UI_maxSpeedToReachDestination : 0|16@1+ (0.01,0) [0|655.34] "m/s" Vector__XXX
 SG_ UI_remainingWeightedRMSSpeed : 16|16@1+ (0.01,0) [0|655.35] "" Vector__XXX
 SG_ UI_timeToDestination : 32|16@1+ (1,0) [0|65534] "s" Vector__XXX

BO_ 1173 UI_tripPlanning3: 8 UI
 SG_ UI_predictedEnergy : 0|16@1- (0.01,0) [-327.67|327.67] "kWh" Vector__XXX
 SG_ UI_predictedEnergyLearned : 16|16@1- (0.01,0) [-327.68|327.67] "" Vector__XXX
 SG_ UI_hindsightEnergy : 32|16@1- (0.01,0) [-327.67|327.67] "kWh" Vector__XXX
 SG_ UI_hindsightEnergyLearned : 48|16@1- (0.01,0) [-327.68|327.67] "" Vector__XXX

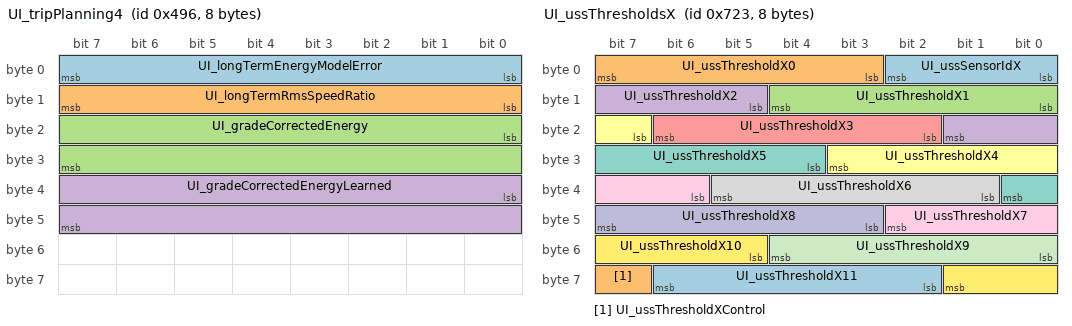
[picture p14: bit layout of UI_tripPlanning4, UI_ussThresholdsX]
BO_ 1174 UI_tripPlanning4: 8 UI
 SG_ UI_longTermEnergyModelError : 0|8@1- (0.5,0) [-64|63.5] "" Vector__XXX
 SG_ UI_longTermRmsSpeedRatio : 8|8@1+ (0.01,0) [0|2.55] "" Vector__XXX
 SG_ UI_gradeCorrectedEnergy : 16|16@1- (0.01,0) [-327.68|327.67] "" Vector__XXX
 SG_ UI_gradeCorrectedEnergyLearned : 32|16@1- (0.01,0) [-327.68|327.67] "" Vector__XXX

BO_ 1175 UI_tripPlanning5: 8 UI
 SG_ UI_battPreconditionOnNavTime : 0|16@1+ (1,0) [0|65535] "" Vector__XXX
 SG_ UI_maxBattPreconditionOnNavTime : 16|16@1+ (1,0) [0|65535] "" Vector__XXX

BO_ 850 UI_uiHealthStatus: 8 UI
 SG_ UI_centerDisplayRunning : 0|1@1+ (1,0) [0|1] "" Vector__XXX
 SG_ UI_centerDisplaySM : 1|3@1+ (1,0) [0|7] "" Vector__XXX
 SG_ UI_centerDisplayPowerOn : 4|1@1+ (1,0) [0|1] "" Vector__XXX
 SG_ UI_centerDisplayCrtcOk : 5|1@1+ (1,0) [0|1] "" Vector__XXX
 SG_ UI_centerDisplayHardwareOk : 6|1@1+ (1,0) [0|1] "" Vector__XXX
 SG_ UI_centerDisplayWindowManagerOk : 7|1@1+ (1,0) [0|1] "" Vector__XXX
 SG_ UI_centerDisplayCompositorOk : 8|1@1+ (1,0) [0|1] "" Vector__XXX
 SG_ UI_apVisualizationOk : 9|1@1+ (1,0) [0|1] "" Vector__XXX
 SG_ UI_autonomyCenterDispStatus : 10|2@1+ (1,0) [0|3] "" Vector__XXX
 SG_ UI_autonomyRearDispStatus : 12|2@1+ (1,0) [0|3] "" Vector__XXX
 SG_ UI_autonomyConnectivityStatus : 14|2@1+ (1,0) [0|3] "" Vector__XXX
 SG_ UI_autonomyConnectivtyHWOk : 16|1@1+ (1,0) [0|1] "" Vector__XXX
 SG_ UI_autonomyQtCarStatus : 17|2@1+ (1,0) [0|3] "" Vector__XXX
 SG_ UI_autonomyQtCarRearStatus : 19|2@1+ (1,0) [0|3] "" Vector__XXX
 SG_ UI_autonomyDASServerStatus : 21|2@1+ (1,0) [0|3] "" Vector__XXX
 SG_ UI_rearDisplayRunning : 23|1@1+ (1,0) [0|1] "" Vector__XXX
 SG_ UI_rearDisplayPowerOn : 24|1@1+ (1,0) [0|1] "" Vector__XXX
 SG_ UI_rearDisplaySM : 25|3@1+ (1,0) [0|7] "" Vector__XXX
 SG_ UI_rearDisplayCrtcOk : 28|1@1+ (1,0) [0|1] "" Vector__XXX
 SG_ UI_rearDisplayHardwareOk : 29|1@1+ (1,0) [0|1] "" Vector__XXX
 SG_ UI_rearDisplayWindowManagerOk : 30|1@1+ (1,0) [0|1] "" Vector__XXX
 SG_ UI_rearDisplayCompositorOk : 31|1@1+ (1,0) [0|1] "" Vector__XXX

BO_ 1827 UI_ussThresholdsX: 8 UI
 SG_ UI_ussSensorIdX : 0|3@1+ (1,0) [0|7] "" Vector__XXX
 SG_ UI_ussThresholdX0 : 3|5@1+ (1,0) [0|31] "" Vector__XXX
 SG_ UI_ussThresholdX1 : 8|5@1+ (1,0) [0|31] "" Vector__XXX
 SG_ UI_ussThresholdX2 : 13|5@1+ (1,0) [0|31] "" Vector__XXX
 SG_ UI_ussThresholdX3 : 18|5@1+ (1,0) [0|31] "" Vector__XXX
 SG_ UI_ussThresholdX4 : 23|5@1+ (1,0) [0|31] "" Vector__XXX
 SG_ UI_ussThresholdX5 : 28|5@1+ (1,0) [0|31] "" Vector__XXX
 SG_ UI_ussThresholdX6 : 33|5@1+ (1,0) [0|31] "" Vector__XXX
 SG_ UI_ussThresholdX7 : 38|5@1+ (1,0) [0|31] "" Vector__XXX
 SG_ UI_ussThresholdX8 : 43|5@1+ (1,0) [0|31] "" Vector__XXX
 SG_ UI_ussThresholdX9 : 48|5@1+ (1,0) [0|31] "" Vector__XXX
 SG_ UI_ussThresholdX10 : 53|5@1+ (1,0) [0|31] "" Vector__XXX
 SG_ UI_ussThresholdX11 : 58|5@1+ (1,0) [0|31] "" Vector__XXX
 SG_ UI_ussThresholdXControl : 63|1@1+ (1,0) [0|1] "" Vector__XXX

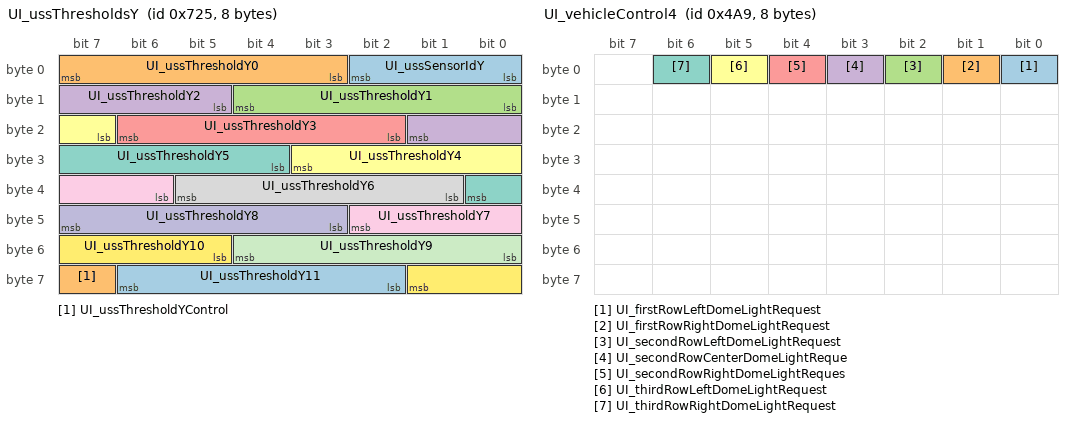
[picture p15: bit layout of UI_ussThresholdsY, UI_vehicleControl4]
BO_ 1829 UI_ussThresholdsY: 8 UI
 SG_ UI_ussSensorIdY : 0|3@1+ (1,0) [0|7] "" Vector__XXX
 SG_ UI_ussThresholdY0 : 3|5@1+ (1,0) [0|31] "" Vector__XXX
 SG_ UI_ussThresholdY1 : 8|5@1+ (1,0) [0|31] "" Vector__XXX
 SG_ UI_ussThresholdY2 : 13|5@1+ (1,0) [0|31] "" Vector__XXX
 SG_ UI_ussThresholdY3 : 18|5@1+ (1,0) [0|31] "" Vector__XXX
 SG_ UI_ussThresholdY4 : 23|5@1+ (1,0) [0|31] "" Vector__XXX
 SG_ UI_ussThresholdY5 : 28|5@1+ (1,0) [0|31] "" Vector__XXX
 SG_ UI_ussThresholdY6 : 33|5@1+ (1,0) [0|31] "" Vector__XXX
 SG_ UI_ussThresholdY7 : 38|5@1+ (1,0) [0|31] "" Vector__XXX
 SG_ UI_ussThresholdY8 : 43|5@1+ (1,0) [0|31] "" Vector__XXX
 SG_ UI_ussThresholdY9 : 48|5@1+ (1,0) [0|31] "" Vector__XXX
 SG_ UI_ussThresholdY10 : 53|5@1+ (1,0) [0|31] "" Vector__XXX
 SG_ UI_ussThresholdY11 : 58|5@1+ (1,0) [0|31] "" Vector__XXX
 SG_ UI_ussThresholdYControl : 63|1@1+ (1,0) [0|1] "" Vector__XXX

BO_ 627 UI_vehicleControl: 8 UI
 SG_ UI_powerStateRequest : 0|2@1+ (1,0) [0|3] "" Vector__XXX
 SG_ UI_childDoorLockOnRight : 2|1@1+ (1,0) [0|1] "" Vector__XXX
 SG_ UI_frontFogSwitch : 3|1@1+ (1,0) [0|1] "" Vector__XXX
 SG_ UI_summonActive : 4|1@1+ (1,0) [0|1] "" Vector__XXX
 SG_ UI_frunkRequest : 5|1@1+ (1,0) [0|1] "" Vector__XXX
 SG_ UI_wiperMode : 6|2@1+ (1,0) [0|3] "" Vector__XXX
 SG_ UI_steeringBacklightEnabled : 8|1@1+ (1,0) [0|1] "" Vector__XXX
 SG_ UI_steeringButtonMode : 9|3@1+ (1,0) [0|7] "" Vector__XXX
 SG_ UI_walkUpUnlock : 12|1@1+ (1,0) [0|1] "" Vector__XXX
 SG_ UI_walkAwayLock : 13|1@1+ (1,0) [0|1] "" Vector__XXX
 SG_ UI_unlockOnPark : 14|1@1+ (1,0) [0|1] "" Vector__XXX
 SG_ UI_globalUnlockOn : 15|1@1+ (1,0) [0|1] "" Vector__XXX
 SG_ UI_childDoorLockOnLeft : 16|1@1+ (1,0) [0|1] "" Vector__XXX
 SG_ UI_lockRequest : 17|3@1+ (1,0) [0|7] "" Vector__XXX
 SG_ UI_alarmEnabled : 20|1@1+ (1,0) [0|1] "" Vector__XXX
 SG_ UI_intrusionSensorOn : 21|1@1+ (1,0) [0|1] "" Vector__XXX
 SG_ UI_stop12vSupport : 22|1@1+ (1,0) [0|1] "" Vector__XXX
 SG_ UI_rearFogSwitch : 23|1@1+ (1,0) [0|1] "" Vector__XXX
 SG_ UI_mirrorFoldRequest : 24|2@1+ (1,0) [0|3] "" Vector__XXX
 SG_ UI_mirrorHeatRequest : 26|1@1+ (1,0) [0|1] "" Vector__XXX
 SG_ UI_remoteStartRequest : 27|3@1+ (1,0) [0|7] "" Vector__XXX
 SG_ UI_seeYouHomeLightingOn : 30|1@1+ (1,0) [0|1] "" Vector__XXX
 SG_ UI_powerOff : 31|1@1+ (1,0) [0|1] "" Vector__XXX
 SG_ UI_displayBrightnessLevel : 32|8@1+ (0.5,0) [0|127] "%" Vector__XXX
 SG_ UI_ambientLightingEnabled : 40|1@1+ (1,0) [0|1] "" Vector__XXX
 SG_ UI_autoHighBeamEnabled : 41|1@1+ (1,0) [0|1] "" Vector__XXX
 SG_ UI_frontLeftSeatHeatReq : 42|2@1+ (1,0) [0|3] "" Vector__XXX
 SG_ UI_frontRightSeatHeatReq : 44|2@1+ (1,0) [0|3] "" Vector__XXX
 SG_ UI_rearLeftSeatHeatReq : 46|2@1+ (1,0) [0|3] "" Vector__XXX
 SG_ UI_rearCenterSeatHeatReq : 48|2@1+ (1,0) [0|3] "" Vector__XXX
 SG_ UI_rearRightSeatHeatReq : 50|2@1+ (1,0) [0|3] "" Vector__XXX
 SG_ UI_autoFoldMirrorsOn : 52|1@1+ (1,0) [0|1] "" Vector__XXX
 SG_ UI_mirrorDipOnReverse : 53|1@1+ (1,0) [0|1] "" Vector__XXX
 SG_ UI_remoteClosureRequest : 54|2@1+ (1,0) [0|3] "" Vector__XXX
 SG_ UI_wiperRequest : 56|3@1+ (1,0) [0|7] "" Vector__XXX
 SG_ UI_domeLightSwitch : 59|2@1+ (1,0) [0|3] "" Vector__XXX
 SG_ UI_honkHorn : 61|1@1+ (1,0) [0|1] "" Vector__XXX
 SG_ UI_driveStateRequest : 62|1@1+ (1,0) [0|1] "" Vector__XXX
 SG_ UI_rearWindowLockout : 63|1@1+ (1,0) [0|1] "" Vector__XXX

BO_ 947 UI_vehicleControl2: 8 UI
 SG_ UI_gloveboxRequest : 0|1@1+ (1,0) [0|1] "" Vector__XXX
 SG_ UI_trunkRequest : 1|1@1+ (1,0) [0|1] "" Vector__XXX
 SG_ UI_UMCUpdateInhibit : 2|1@1+ (1,0) [0|1] "" Vector__XXX
 SG_ UI_WCUpdateInhibit : 3|1@1+ (1,0) [0|1] "" Vector__XXX
 SG_ UI_soundHornOnLock : 4|1@1+ (1,0) [0|1] "" Vector__XXX
 SG_ UI_locksPanelActive : 5|1@1+ (1,0) [0|1] "" Vector__XXX
 SG_ UI_PINToDriveEnabled : 6|1@1+ (1,0) [0|1] "" Vector__XXX
 SG_ UI_PINToDrivePassed : 7|1@1+ (1,0) [0|1] "" Vector__XXX
 SG_ UI_disableMirrorAutoDim : 8|1@1+ (1,0) [0|1] "" Vector__XXX
 SG_ UI_lightSwitch : 9|3@1+ (1,0) [0|7] "" Vector__XXX
 SG_ UI_readyToAddKey : 12|1@1+ (1,0) [0|1] "" Vector__XXX
 SG_ UI_alarmTriggerRequest : 13|1@1+ (1,0) [0|1] "" Vector__XXX
 SG_ UI_VCSECFeature1 : 14|1@1+ (1,0) [0|1] "" Vector__XXX
 SG_ UI_VCLEFTFeature1 : 15|1@1+ (1,0) [0|1] "" Vector__XXX
 SG_ UI_summonState : 16|2@1+ (1,0) [0|3] "" Vector__XXX
 SG_ UI_displayOnForUser : 18|1@1+ (1,0) [0|1] "" Vector__XXX
 SG_ UI_freeRollModeRequest : 19|1@1+ (1,0) [0|1] "" Vector__XXX
 SG_ UI_BLEPushNotificationRequest : 20|1@1+ (1,0) [0|1] "" Vector__XXX
 SG_ UI_pairKeyQRCodeDisplaying : 21|1@1+ (1,0) [0|1] "" Vector__XXX
 SG_ UI_keepAutopilotAwake : 22|1@1+ (1,0) [0|1] "" Vector__XXX
 SG_ UI_batteryPreconditioningRequest : 23|1@1+ (1,0) [0|1] "" Vector__XXX
 SG_ UI_coastDownMode : 24|1@1+ (1,0) [0|1] "" Vector__XXX
 SG_ UI_autopilotPowerStateRequest : 25|2@1+ (1,0) [0|3] "" Vector__XXX
 SG_ UI_shorted12VCellTestMode : 27|2@1+ (1,0) [0|3] "" Vector__XXX
 SG_ UI_autoRollWindowsOnLockEnable : 29|1@1+ (1,0) [0|1] "" Vector__XXX
 SG_ UI_virtualPitchSensorOverrideOKF : 30|1@1+ (1,0) [0|1] "" Vector__XXX
 SG_ UI_conditionalLoggingEnabledVCSE : 31|1@1+ (1,0) [0|1] "" Vector__XXX
 SG_ UI_WC3UpdateInhibit : 32|1@1+ (1,0) [0|1] "" Vector__XXX
 SG_ UI_steeringWheelHeatReq : 33|1@1+ (1,0) [0|1] "" Vector__XXX
 SG_ UI_disableHorn : 34|1@1+ (1,0) [0|1] "" Vector__XXX
 SG_ UI_frontLeftSeatFanReq : 37|2@1+ (1,0) [0|3] "" Vector__XXX
 SG_ UI_frontRightSeatAutoClimateReq : 39|1@1+ (1,0) [0|1] "" Vector__XXX
 SG_ UI_frontRightSeatFanReq : 40|2@1+ (1,0) [0|3] "" Vector__XXX
 SG_ UI_3RLeftSeatHeatReq : 44|2@1+ (1,0) [0|3] "" Vector__XXX
 SG_ UI_3RRightSeatHeatReq : 46|2@1+ (1,0) [0|3] "" Vector__XXX
 SG_ UI_sleepFeature1 : 51|1@1+ (1,0) [0|1] "" Vector__XXX
 SG_ UI_dcr12VThreshold : 52|4@1+ (1,0) [0|15] "" Vector__XXX
 SG_ UI_frontLeftSeatAutoClimateReq : 56|1@1+ (1,0) [0|1] "" Vector__XXX
 SG_ UI_wiperHeaterReq : 57|1@1+ (1,0) [0|1] "" Vector__XXX
 SG_ UI_tireSeason : 59|1@1+ (1,0) [0|1] "" Vector__XXX
 SG_ UI_saveTireConfigReq : 60|1@1+ (1,0) [0|1] "" Vector__XXX
 SG_ UI_silentAlarm : 61|1@1+ (1,0) [0|1] "" Vector__XXX
 SG_ UI_sleepFeature2 : 63|1@1+ (1,0) [0|1] "" Vector__XXX

BO_ 628 UI_vehicleControl3: 8 UI
 SG_ UI_lightFlashRequest : 0|2@1+ (1,0) [0|3] "" Vector__XXX
 SG_ UI_keylessDrivingEnabled : 2|1@1+ (1,0) [0|1] "" Vector__XXX
 SG_ UI_phoneCallActive : 3|1@1+ (1,0) [0|1] "" Vector__XXX
 SG_ UI_drivingSideVEH : 4|2@1+ (1,0) [0|3] "" Vector__XXX
 SG_ UI_keyPairResponse : 6|2@1+ (1,0) [0|3] "" Vector__XXX
 SG_ UI_lightShowClosuresEnabled : 8|1@1+ (1,0) [0|1] "" Vector__XXX
 SG_ UI_steeringWheelHeatAutoReq : 9|1@1+ (1,0) [0|1] "" Vector__XXX
 SG_ UI_steeringWheelHeatLevelReq : 10|2@1+ (1,0) [0|3] "" Vector__XXX
 SG_ UI_headlightPulseRequest : 12|1@1+ (1,0) [0|1] "" Vector__XXX
 SG_ UI_VCSECFeature2 : 13|1@1+ (1,0) [0|1] "" Vector__XXX
 SG_ UI_VCSECFeature3 : 14|1@1+ (1,0) [0|1] "" Vector__XXX
 SG_ UI_VCSECFeature4 : 15|1@1+ (1,0) [0|1] "" Vector__XXX
 SG_ UI_VCSECFeature5 : 16|1@1+ (1,0) [0|1] "" Vector__XXX
 SG_ UI_shortHornRequest : 17|1@1+ (1,0) [0|1] "" Vector__XXX
 SG_ UI_packTempLoggingRequest : 18|1@1+ (1,0) [0|1] "" Vector__XXX
 SG_ UI_UMC3UpdateInhibit : 22|1@1+ (1,0) [0|1] "" Vector__XXX
 SG_ UI_handsFreeTrunk : 23|1@1+ (1,0) [0|1] "" Vector__XXX
 SG_ UI_displayRedShiftActive : 24|1@1+ (1,0) [0|1] "" Vector__XXX
 SG_ UI_handsFreeFrunk : 25|1@1+ (1,0) [0|1] "" Vector__XXX
 SG_ UI_fasciaCameraWashRequest : 26|1@1+ (1,0) [0|1] "" Vector__XXX
 SG_ UI_autoClosuresExcludeHome : 27|1@1+ (1,0) [0|1] "" Vector__XXX
 SG_ UI_leftRearSeatAdjustmentRequest : 28|3@1+ (1,0) [0|7] "" Vector__XXX
 SG_ UI_rightRearSeatAdjustmentReques : 32|3@1+ (1,0) [0|7] "" Vector__XXX
 SG_ UI_blindSpotIndicatorLightReques : 35|1@1+ (1,0) [0|1] "" Vector__XXX
 SG_ UI_etcBluetoothControl : 36|2@1+ (1,0) [0|3] "" Vector__XXX
 SG_ UI_keepOnAccessoryPortsReq : 38|1@1+ (1,0) [0|1] "" Vector__XXX
 SG_ UI_fasciaCameraShown : 39|1@1+ (1,0) [0|1] "" Vector__XXX
 SG_ UI_rearSeatChildLock : 40|2@1+ (1,0) [0|3] "" Vector__XXX
 SG_ UI_windowPercentageRequest : 42|6@1- (5,0) [-100|100] "%" Vector__XXX
 SG_ UI_windowRequestedFL : 48|1@1+ (1,0) [0|1] "" Vector__XXX
 SG_ UI_windowRequestedFR : 49|1@1+ (1,0) [0|1] "" Vector__XXX
 SG_ UI_windowRequestedRL : 50|1@1+ (1,0) [0|1] "" Vector__XXX
 SG_ UI_windowRequestedRR : 51|1@1+ (1,0) [0|1] "" Vector__XXX
 SG_ UI_windowRequest : 52|3@1+ (1,0) [0|7] "" Vector__XXX
 SG_ UI_closeTrunkRequest : 55|1@1+ (1,0) [0|1] "" Vector__XXX
 SG_ UI_childPresenceDetectionDisable : 56|1@1+ (1,0) [0|1] "" Vector__XXX
 SG_ UI_V2LAUpdateInhibit : 57|1@1+ (1,0) [0|1] "" Vector__XXX
 SG_ UI_userPresenceDetectionEnabled : 58|1@1+ (1,0) [0|1] "" Vector__XXX
 SG_ UI_derivedLoadshedFeature : 59|1@1+ (1,0) [0|1] "" Vector__XXX
 SG_ UI_rearSeatFoldConfirmed : 60|1@1+ (1,0) [0|1] "" Vector__XXX
 SG_ UI_leftRearSeatRequestFromRearDi : 61|1@1+ (1,0) [0|1] "" Vector__XXX
 SG_ UI_selfParkStandingBy : 62|1@1+ (1,0) [0|1] "" Vector__XXX
 SG_ UI_rightRearSeatRequestFromRearD : 63|1@1+ (1,0) [0|1] "" Vector__XXX

BO_ 1193 UI_vehicleControl4: 8 UI
 SG_ UI_firstRowLeftDomeLightRequest : 0|1@1+ (1,0) [0|1] "" Vector__XXX
 SG_ UI_firstRowRightDomeLightRequest : 1|1@1+ (1,0) [0|1] "" Vector__XXX
 SG_ UI_secondRowLeftDomeLightRequest : 2|1@1+ (1,0) [0|1] "" Vector__XXX
 SG_ UI_secondRowCenterDomeLightReque : 3|1@1+ (1,0) [0|1] "" Vector__XXX
 SG_ UI_secondRowRightDomeLightReques : 4|1@1+ (1,0) [0|1] "" Vector__XXX
 SG_ UI_thirdRowLeftDomeLightRequest : 5|1@1+ (1,0) [0|1] "" Vector__XXX
 SG_ UI_thirdRowRightDomeLightRequest : 6|1@1+ (1,0) [0|1] "" Vector__XXX

BO_ 853 UI_vehicleControlThermal: 8 UI
 SG_ UI_coolantFlowRequest : 0|5@1+ (1,0) [0|25] "LPM" Vector__XXX
 SG_ UI_inletActiveCoolTarget : 5|7@1+ (1,0) [0|127] "degC" Vector__XXX
 SG_ UI_disableHVPTThermalLoads : 12|1@1+ (1,0) [0|1] "" Vector__XXX
 SG_ UI_enableCompLiquidPumpOut : 13|1@1+ (1,0) [0|1] "" Vector__XXX
 SG_ UI_enableCOP1HighSHOperation : 14|1@1+ (1,0) [0|1] "" Vector__XXX
 SG_ UI_enableIncreasedEvapRampRate : 15|1@1+ (1,0) [0|1] "" Vector__XXX
 SG_ UI_enableCOP1BatteryHeating : 16|1@1+ (1,0) [0|1] "" Vector__XXX
 SG_ UI_enableCOP1CabinHeatingBattery : 17|1@1+ (1,0) [0|1] "" Vector__XXX
 SG_ UI_enableLouverAutoDetection : 18|1@1+ (1,0) [0|1] "" Vector__XXX
 SG_ UI_enableUserFacingLowFlowDelive : 19|1@1+ (1,0) [0|1] "" Vector__XXX
 SG_ UI_disableHvacCameraOnlyDefog : 20|1@1+ (1,0) [0|1] "" Vector__XXX
 SG_ UI_enableEXVFastCalibration : 21|1@1+ (1,0) [0|1] "" Vector__XXX
 SG_ UI_enableThermalDriverlessSelfTe : 22|1@1+ (1,0) [0|1] "" Vector__XXX
 SG_ UI_enableCoolantDasTarget : 23|1@1+ (1,0) [0|1] "" Vector__XXX
 SG_ UI_geofencedLiftgateHeight : 24|8@1+ (1,0) [0|255] "" Vector__XXX
 SG_ UI_convenienceFeatureLimit : 32|7@1+ (1,0) [0|127] "%" Vector__XXX
 SG_ UI_allowConvenienceFeatures : 39|1@1+ (1,0) [0|1] "" Vector__XXX
 SG_ UI_enableConservativeBatteryHeat : 40|1@1+ (1,0) [0|1] "" Vector__XXX
 SG_ UI_enableDefaultApTempTarget : 41|1@1+ (1,0) [0|1] "" Vector__XXX
 SG_ UI_enableHVACCompressorWasteHeat : 42|1@1+ (1,0) [0|1] "" Vector__XXX
 SG_ UI_disablePhoneChargingPads : 43|1@1+ (1,0) [0|1] "" Vector__XXX
 SG_ UI_isAtTeslaFacility : 45|1@1+ (1,0) [0|1] "" Vector__XXX
 SG_ UI_enableThermalPowerBudget : 46|1@1+ (1,0) [0|1] "" Vector__XXX
 SG_ UI_enableHVACAPFanHeaterControl : 48|1@1+ (1,0) [0|1] "" Vector__XXX
 SG_ UI_enableAutopilotAirPurge : 49|1@1+ (1,0) [0|1] "" Vector__XXX
 SG_ UI_enableForcedAirCameraHeater : 50|1@1+ (1,0) [0|1] "" Vector__XXX
 SG_ UI_enableHvacCOPOnUndeliveredVeh : 51|1@1+ (1,0) [0|1] "" Vector__XXX

BO_ 644 UI_vehicleModes: 8 UI
 SG_ UI_factoryMode : 0|1@1+ (1,0) [0|1] "" Vector__XXX
 SG_ UI_transportMode : 1|1@1+ (1,0) [0|1] "" Vector__XXX
 SG_ UI_showroomMode : 2|1@1+ (1,0) [0|1] "" Vector__XXX
 SG_ UI_serviceMode : 3|1@1+ (1,0) [0|1] "" Vector__XXX
 SG_ UI_isDelivered : 4|1@1+ (1,0) [0|1] "" Vector__XXX
 SG_ UI_hasEverBeenDelivered : 5|1@1+ (1,0) [0|1] "" Vector__XXX
 SG_ UI_homelinkV2Command0 : 8|8@1+ (1,0) [0|255] "" Vector__XXX
 SG_ UI_homelinkV2Command1 : 16|8@1+ (1,0) [0|255] "" Vector__XXX
 SG_ UI_homelinkV2Command2 : 24|8@1+ (1,0) [0|255] "" Vector__XXX
 SG_ UI_carWashMode : 32|1@1+ (1,0) [0|1] "" Vector__XXX
 SG_ UI_valetMode : 33|1@1+ (1,0) [0|1] "" Vector__XXX
 SG_ UI_gameMode : 34|1@1+ (1,0) [0|1] "" Vector__XXX
 SG_ UI_diagnosticsAllowed : 35|1@1+ (1,0) [0|1] "" Vector__XXX
 SG_ UI_serviceModePlus : 36|1@1+ (1,0) [0|1] "" Vector__XXX
 SG_ UI_premiumAmpPowerOff : 37|1@1+ (1,0) [0|1] "" Vector__XXX
 SG_ UI_signedCmdHardLocked : 38|1@1+ (1,0) [0|1] "" Vector__XXX
 SG_ UI_signedCmdServiceMode : 39|1@1+ (1,0) [0|1] "" Vector__XXX
 SG_ UI_closureEasterEggStatus : 40|2@1+ (1,0) [0|3] "" Vector__XXX
 SG_ UI_lightShowType : 42|3@1+ (1,0) [0|7] "" Vector__XXX
 SG_ UI_sohTestRequest : 45|1@1+ (1,0) [0|1] "" Vector__XXX
 SG_ UI_upkeepMode : 46|1@1+ (1,0) [0|1] "" Vector__XXX
 SG_ UI_vehicleModesCounter : 52|4@1+ (1,0) [0|15] "" Vector__XXX
 SG_ UI_vehicleModesChecksum : 56|8@1+ (1,0) [0|255] "" Vector__XXX

BO_ 595 UI_ventPanelControlRequest: 8 UI
 SG_ UI_ventPanelControlRequestIndex M : 0|1@1+ (1,0) [0|1] "" Vector__XXX
 SG_ UI_ventPanelLeftPositionX m0 : 8|8@1+ (0.5,0) [0|100] "%" Vector__XXX
 SG_ UI_ventPanelLeftPositionY m0 : 16|8@1+ (0.5,0) [0|100] "%" Vector__XXX
 SG_ UI_ventPanelLeftLateralSplit m0 : 24|8@1+ (0.5,0) [0|100] "%" Vector__XXX
 SG_ UI_ventPanelRightPositionX m0 : 32|8@1+ (0.5,0) [0|100] "%" Vector__XXX
 SG_ UI_ventPanelRightPositionY m0 : 40|8@1+ (0.5,0) [0|100] "%" Vector__XXX
 SG_ UI_ventPanelRightLateralSplit m0 : 48|8@1+ (0.5,0) [0|100] "%" Vector__XXX
 SG_ UI_ventPanelLeftLateralMode m0 : 56|2@1+ (1,0) [0|3] "" Vector__XXX
 SG_ UI_ventPanelRightLateralMode m0 : 58|2@1+ (1,0) [0|3] "" Vector__XXX
 SG_ UI_hvacReqActiveVents m0 : 60|2@1+ (1,0) [0|3] "" Vector__XXX
 SG_ UI_vent2RLeftPositionX m1 : 8|8@1+ (0.5,0) [0|100] "%" Vector__XXX
 SG_ UI_vent2RLeftPositionY m1 : 16|8@1+ (0.5,0) [0|100] "%" Vector__XXX
 SG_ UI_vent2RRightPositionX m1 : 24|8@1+ (0.5,0) [0|100] "%" Vector__XXX
 SG_ UI_vent2RRightPositionY m1 : 32|8@1+ (0.5,0) [0|100] "%" Vector__XXX
 SG_ UI_hvacReqThirdRowState m1 : 40|2@1+ (1,0) [0|3] "" Vector__XXX

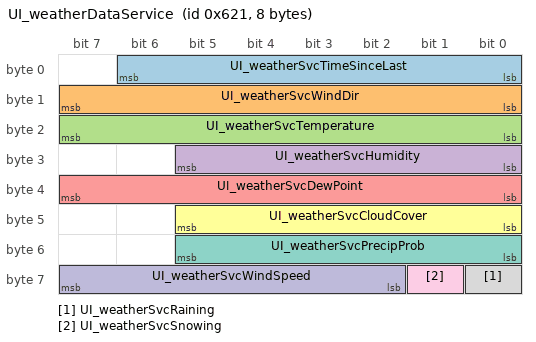
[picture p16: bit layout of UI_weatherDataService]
BO_ 1569 UI_weatherDataService: 8 UI
 SG_ UI_weatherSvcTimeSinceLast : 0|7@1+ (1,0) [0|127] "" Vector__XXX
 SG_ UI_weatherSvcWindDir : 8|8@1+ (1.5,0) [0|382.5] "" Vector__XXX
 SG_ UI_weatherSvcTemperature : 16|8@1+ (0.5,-40) [-40|87.5] "" Vector__XXX
 SG_ UI_weatherSvcHumidity : 24|6@1+ (1.62,0) [0|102.06] "" Vector__XXX
 SG_ UI_weatherSvcDewPoint : 32|8@1+ (0.5,-60) [-60|67.5] "" Vector__XXX
 SG_ UI_weatherSvcCloudCover : 40|6@1+ (1.62,0) [0|102.06] "" Vector__XXX
 SG_ UI_weatherSvcPrecipProb : 48|6@1+ (1.62,0) [0|102.06] "" Vector__XXX
 SG_ UI_weatherSvcRaining : 56|1@1+ (1,0) [0|1] "" Vector__XXX
 SG_ UI_weatherSvcSnowing : 57|1@1+ (1,0) [0|1] "" Vector__XXX
 SG_ UI_weatherSvcWindSpeed : 58|6@1+ (2,0) [0|126] "" Vector__XXX

CM_ BO_ 659 "Touchscreen user interface computer message: chassis control";
CM_ SG_ 659 UI_steeringTuneRequest "UI customer level request for steering feel. MS had comfort, normal, sport. M3 intent is Normal, sport see SW-95934";
CM_ SG_ 659 UI_tractionControlMode "Transport user selected traction control modes";
CM_ SG_ 659 UI_parkBrakeRequest "User selection for Park brake";
CM_ SG_ 659 UI_narrowGarages "Touchscreen user interface computer: narrow garages";
CM_ SG_ 659 UI_winchModeRequest "Winch mode (towing) request";
CM_ SG_ 659 UI_zeroSpeedConfirmed "Touchscreen user interface computer: zero speed confirmed";
CM_ SG_ 659 UI_trailerMode "Indicates whether trailer mode is selected. To be used when towing a trailer.";
CM_ SG_ 659 UI_distanceUnits "Touchscreen user interface computer: distance units";
CM_ SG_ 659 UI_dasDebugEnable "Touchscreen user interface computer: das debug enable";
CM_ SG_ 659 UI_accOvertakeEnable "Enable ACC Overtake assistance (reduce follow distance when the turn signal is on), UI firmware only sets datavalue to True";
CM_ SG_ 659 UI_aebEnable "Enable Autonomous Emergency Brakes";
CM_ SG_ 659 UI_aesEnable "Enable Automatic Emergency Steering (associated datavalue set to true and never changed by UI firmware)";
CM_ SG_ 659 UI_ahlbEnable "Enable Automatic High/Low Beams";
CM_ SG_ 659 UI_autoLaneChangeEnable "Enable Automatic Lane Change";
CM_ SG_ 659 UI_winchProxUserOverride "User feedback from tow mode panel confirming that charge cable is disconnected when vehicle is unable to determine cable status";
CM_ SG_ 659 UI_rebootAutopilot "Touchscreen user interface computer: reboot autopilot";
CM_ SG_ 659 UI_autoParkRequest "Request Automatic Parking";
CM_ SG_ 659 UI_bsdEnable "Enable Blind Spot Detection (datavalue defaults to true and not changed by UI firmware)";
CM_ SG_ 659 UI_fcwEnable "Enable Forward Collision Warning";
CM_ SG_ 659 UI_fcwSensitivity "Forward Collision Warning Level";
CM_ SG_ 659 UI_latControlEnable "Enable Lateral Control (lane centering, lane keeping, lane changing)";
CM_ SG_ 659 UI_ldwEnable "Enable Lane Departure Warning";
CM_ SG_ 659 UI_pedalSafetyEnable "Touchscreen user interface computer: pedal safety enable";
CM_ SG_ 659 UI_pedalMap_epas "Touchscreen user interface computer: pedal map epas";
CM_ SG_ 659 UI_redLightStopSignEnable "Touchscreen user interface computer: red light stop sign enable";
CM_ SG_ 659 UI_selfParkTune "Touchscreen user interface computer: self park tune";
CM_ SG_ 659 UI_chassisControlCounter "Touchscreen user interface computer: chassis control counter";
CM_ SG_ 659 UI_chassisControlChecksum "Touchscreen user interface computer: chassis control checksum";
CM_ BO_ 531 "Touchscreen user interface computer message: cruise control";
CM_ SG_ 531 UI_cruiseSpeedCommand "User command to change the cruise set speed.";
CM_ SG_ 531 UI_smartSummonRequest "Touchscreen user interface computer: smart summon request";
CM_ SG_ 531 UI_autonomySummonRequest "Autonomy summon request from mobile app";
CM_ SG_ 531 UI_cruiseControlCounter "Touchscreen user interface computer: cruise control counter";
CM_ SG_ 531 UI_cruiseControlChecksum "Touchscreen user interface computer: cruise control checksum";
CM_ BO_ 664 "Touchscreen user interface computer message: csa offramp curvature";
CM_ SG_ 664 UI_csaOfframpCurvC2 "Touchscreen user interface computer: csa offramp curv C2";
CM_ SG_ 664 UI_csaOfframpCurvC3 "Touchscreen user interface computer: csa offramp curv C3";
CM_ SG_ 664 UI_csaOfframpCurvRange "Touchscreen user interface computer: csa offramp curv range";
CM_ SG_ 664 UI_csaOfframpCurvCounter "Touchscreen user interface computer: csa offramp curv counter";
CM_ SG_ 664 UI_csaOfframpCurvUsingTspline "Touchscreen user interface computer: csa offramp curv using tspline";
CM_ SG_ 664 UI_csaOfframpCurvReserved "Touchscreen user interface computer: csa offramp curv reserved";
CM_ SG_ 664 UI_csaOfframpCurvChecksum "Touchscreen user interface computer: csa offramp curv checksum";
CM_ BO_ 679 "Touchscreen user interface computer message: csa road curvature";
CM_ SG_ 679 UI_csaRoadCurvC2 "Touchscreen user interface computer: csa road curv C2";
CM_ SG_ 679 UI_csaRoadCurvC3 "Touchscreen user interface computer: csa road curv C3";
CM_ SG_ 679 UI_csaRoadCurvRange "Touchscreen user interface computer: csa road curv range";
CM_ SG_ 679 UI_csaRoadCurvCounter "Touchscreen user interface computer: csa road curv counter";
CM_ SG_ 679 UI_csaRoadCurvUsingTspline "Touchscreen user interface computer: csa road curv using tspline";
CM_ SG_ 679 UI_csaRoadCurvReserved "Touchscreen user interface computer: csa road curv reserved";
CM_ SG_ 679 UI_csaRoadCurvChecksum "Touchscreen user interface computer: csa road curv checksum";
CM_ BO_ 1280 "Touchscreen user interface computer message: debug ECU";
CM_ SG_ 1280 UI_debugEcuTarget "Touchscreen user interface computer: debug ecu target";
CM_ SG_ 1280 UI_DI_debugEnable "Touchscreen user interface computer: DI debug enable";
CM_ SG_ 1280 UI_DIS_debugEnable "Touchscreen user interface computer: DIS debug enable";
CM_ SG_ 1280 UI_PM_debugEnable "Touchscreen user interface computer: PM debug enable";
CM_ SG_ 1280 UI_PM_debugAt100Hz "Touchscreen user interface computer: PM debug at100 hz";
CM_ SG_ 1280 UI_PMS_debugEnable "Touchscreen user interface computer: PMS debug enable";
CM_ SG_ 1280 UI_PMS_debugAt100Hz "Touchscreen user interface computer: PMS debug at100 hz";
CM_ SG_ 1280 UI_BMS_debugAllEnable "Touchscreen user interface computer: BMS debug all enable";
CM_ SG_ 1280 UI_BMS_debugDisable "Touchscreen user interface computer: BMS debug disable";
CM_ SG_ 1280 UI_VCRIGHT_debugEnable "Touchscreen user interface computer: VCRIGHT debug enable";
CM_ SG_ 1280 UI_VCFRONT_debugEnable "Touchscreen user interface computer: VCFRONT debug enable";
CM_ SG_ 1280 UI_DIF_debugEnable "Touchscreen user interface computer: DIF debug enable";
CM_ SG_ 1280 UI_DIR_debugEnable "Touchscreen user interface computer: DIR debug enable";
CM_ SG_ 1280 UI_PMF_debugEnable "Touchscreen user interface computer: PMF debug enable";
CM_ SG_ 1280 UI_PMR_debugEnable "Touchscreen user interface computer: PMR debug enable";
CM_ BO_ 2043 "Touchscreen user interface computer message: debug tas";
CM_ SG_ 2043 UI_debugDampingRequestFLC "Touchscreen user interface computer: debug damping request FLC";
CM_ SG_ 2043 UI_debugDampingRequestFLR "Touchscreen user interface computer: debug damping request FLR";
CM_ SG_ 2043 UI_debugDampingRequestFRC "Touchscreen user interface computer: debug damping request FRC";
CM_ SG_ 2043 UI_debugDampingRequestFRR "Touchscreen user interface computer: debug damping request FRR";
CM_ SG_ 2043 UI_debugDampingRequestRLC "Touchscreen user interface computer: debug damping request RLC";
CM_ SG_ 2043 UI_debugDampingRequestRLR "Touchscreen user interface computer: debug damping request RLR";
CM_ SG_ 2043 UI_debugDampingRequestRRC "Touchscreen user interface computer: debug damping request RRC";
CM_ SG_ 2043 UI_debugDampingRequestRRR "Touchscreen user interface computer: debug damping request RRR";
CM_ BO_ 1096 "Touchscreen user interface computer message: driver assist anon debug params";
CM_ SG_ 1096 UI_anonDebugParam1 "Touchscreen user interface computer: anon debug param1";
CM_ SG_ 1096 UI_anonDebugFlag1 "Touchscreen user interface computer: anon debug flag1";
CM_ SG_ 1096 UI_anonDebugParam2 "Touchscreen user interface computer: anon debug param2";
CM_ SG_ 1096 UI_anonDebugFlag2 "Touchscreen user interface computer: anon debug flag2";
CM_ SG_ 1096 UI_anonDebugParam3 "Touchscreen user interface computer: anon debug param3";
CM_ SG_ 1096 UI_anonDebugFlag3 "Touchscreen user interface computer: anon debug flag3";
CM_ SG_ 1096 UI_anonDebugParam4 "Touchscreen user interface computer: anon debug param4";
CM_ SG_ 1096 UI_anonDebugFlag4 "Touchscreen user interface computer: anon debug flag4";
CM_ SG_ 1096 UI_anonDebugParam5 "Touchscreen user interface computer: anon debug param5";
CM_ SG_ 1096 UI_anonDebugParam6 "Touchscreen user interface computer: anon debug param6";
CM_ SG_ 1096 UI_anonDebugParam7 "Touchscreen user interface computer: anon debug param7";
CM_ SG_ 1096 UI_visionSpeedSlider "Touchscreen user interface computer: vision speed slider";
CM_ BO_ 1016 "Touchscreen user interface computer message: driver assist control";
CM_ SG_ 1016 UI_autopilotControlRequest "Touchscreen user interface computer: autopilot control request";
CM_ SG_ 1016 UI_ulcStalkConfirm "Drive on autopilot stalk confirmation mode (set by feature config).";
CM_ SG_ 1016 UI_summonHeartbeat "Touchscreen user interface computer: summon heartbeat";
CM_ SG_ 1016 UI_curvSpeedAdaptDisable "Touchscreen user interface computer: curv speed adapt disable";
CM_ SG_ 1016 UI_dasDeveloper "Touchscreen user interface computer: das developer";
CM_ SG_ 1016 UI_enableVinAssociation "Touchscreen user interface computer: enable vin association";
CM_ SG_ 1016 UI_lssLkaEnabled "User setting for lane keep assist";
CM_ SG_ 1016 UI_lssLdwEnabled "User setting for lane departure warning";
CM_ SG_ 1016 UI_coastToCoast "Touchscreen user interface computer: coast to coast";
CM_ SG_ 1016 UI_autoSummonEnable "Touchscreen user interface computer: auto summon enable";
CM_ SG_ 1016 UI_exceptionListEnable "Touchscreen user interface computer: exception list enable";
CM_ SG_ 1016 UI_roadCheckDisable "Touchscreen user interface computer: road check disable";
CM_ SG_ 1016 UI_driveOnMapsEnable "Drive on Autopilot enabled";
CM_ SG_ 1016 UI_handsOnRequirementDisable "Touchscreen user interface computer: hands on requirement disable";
CM_ SG_ 1016 UI_ulcOffHighway "Touchscreen user interface computer: ulc off highway";
CM_ SG_ 1016 UI_fuseLanesDisable "Touchscreen user interface computer: fuse lanes disable";
CM_ SG_ 1016 UI_fuseHPPDisable "Touchscreen user interface computer: fuse HPP disable";
CM_ SG_ 1016 UI_fuseVehiclesDisable "Touchscreen user interface computer: fuse vehicles disable";
CM_ SG_ 1016 UI_enableClipParkedTelemetry "Touchscreen user interface computer: enable clip parked telemetry";
CM_ SG_ 1016 UI_visionSpeedType "Touchscreen user interface computer: vision speed type";
CM_ SG_ 1016 UI_curvatureDatabaseOnly "Touchscreen user interface computer: curvature database only";
CM_ SG_ 1016 UI_lssElkEnabled "User setting for emergency lane keep";
CM_ SG_ 1016 UI_summonExitType "Touchscreen user interface computer: summon exit type";
CM_ SG_ 1016 UI_summonEntryType "Touchscreen user interface computer: summon entry type";
CM_ SG_ 1016 UI_selfParkRequest "Self park request";
CM_ SG_ 1016 UI_summonReverseDist "Touchscreen user interface computer: summon reverse dist";
CM_ SG_ 1016 UI_undertakeAssistEnable "Touchscreen user interface computer: undertake assist enable";
CM_ SG_ 1016 UI_adaptiveSetSpeedEnable "Touchscreen user interface computer: adaptive set speed enable";
CM_ SG_ 1016 UI_drivingSide "Touchscreen user interface computer: driving side";
CM_ SG_ 1016 UI_enableClipTelemetry "Touchscreen user interface computer: enable clip telemetry";
CM_ SG_ 1016 UI_enableTripTelemetry "Touchscreen user interface computer: enable trip telemetry";
CM_ SG_ 1016 UI_enableRoadSegmentTelemetry "Touchscreen user interface computer: enable road segment telemetry";
CM_ SG_ 1016 UI_accFollowDistanceSetting "Touchscreen user interface computer: acc follow distance setting";
CM_ SG_ 1016 UI_hasDriveOnNav "Touchscreen user interface computer: has drive on nav";
CM_ SG_ 1016 UI_followNavRouteEnable "Following route with Drive on Autopilot";
CM_ SG_ 1016 UI_ulcSpeedConfig "Drive on autopilot speed base lane changes mode.";
CM_ SG_ 1016 UI_ulcBlindSpotConfig "Touchscreen user interface computer: ulc blind spot config";
CM_ SG_ 1016 UI_suppressExitPassingLane "Navigate on Autopilot will not suggest lane changes out of the passing lane";
CM_ SG_ 1016 UI_enableClipStartStopTelemetry "Touchscreen user interface computer: enable clip start stop telemetry";
CM_ SG_ 1016 UI_alcOffHighwayEnable "Touchscreen user interface computer: alc off highway enable";
CM_ SG_ 1016 UI_validationLoop "Touchscreen user interface computer: validation loop";
CM_ SG_ 1016 UI_smartSummonType "Type of smart summon session (Find Me, Pin Drop, Smart Autopark)";
CM_ SG_ 1016 UI_enableVisionOnlyStops "Touchscreen user interface computer: enable vision only stops";
CM_ SG_ 1016 UI_source3D "Touchscreen user interface computer: source3 d";
CM_ SG_ 1016 UI_isaSpeedingChimeMuted "Reports the user input of Intelligent Speed Assist (ISA) speed chime alert option.";
CM_ BO_ 568 "Touchscreen user interface computer message: driver assist map data";
CM_ SG_ 568 UI_mapSpeedLimitDependency "Touchscreen user interface computer: map speed limit dependency";
CM_ SG_ 568 UI_roadClass "Autopilot map road class";
CM_ SG_ 568 UI_inSuperchargerGeofence "Touchscreen user interface computer: in supercharger geofence";
CM_ SG_ 568 UI_mapSpeedUnits "Touchscreen user interface computer: map speed units";
CM_ SG_ 568 UI_mapSpeedLimit "Touchscreen user interface computer: map speed limit";
CM_ SG_ 568 UI_mapSpeedLimitType "Touchscreen user interface computer: map speed limit type";
CM_ SG_ 568 UI_countryCode "Touchscreen user interface computer: country code";
CM_ SG_ 568 UI_streetCount "Touchscreen user interface computer: street count";
CM_ SG_ 568 UI_gpsRoadMatch "Touchscreen user interface computer: gps road match";
CM_ SG_ 568 UI_navRouteActive "Navigation route is active";
CM_ SG_ 568 UI_parallelAutoparkEnabled "Autopilot map parallel park enabled.";
CM_ SG_ 568 UI_perpendicularAutoparkEnabled "Autopilot map perpendicular park enabled.";
CM_ SG_ 568 UI_nextBranchDist "Touchscreen user interface computer: next branch dist";
CM_ SG_ 568 UI_controlledAccess "DAS map controlled access segment.";
CM_ SG_ 568 UI_nextBranchLeftOffRamp "Touchscreen user interface computer: next branch left off ramp";
CM_ SG_ 568 UI_nextBranchRightOffRamp "Touchscreen user interface computer: next branch right off ramp";
CM_ SG_ 568 UI_rejectLeftLane "Touchscreen user interface computer: reject left lane";
CM_ SG_ 568 UI_rejectRightLane "Touchscreen user interface computer: reject right lane";
CM_ SG_ 568 UI_rejectHPP "Touchscreen user interface computer: reject HPP";
CM_ SG_ 568 UI_rejectNav "Touchscreen user interface computer: reject nav";
CM_ SG_ 568 UI_rejectLeftFreeSpace "Touchscreen user interface computer: reject left free space";
CM_ SG_ 568 UI_rejectRightFreeSpace "Touchscreen user interface computer: reject right free space";
CM_ SG_ 568 UI_rejectAutosteer "Touchscreen user interface computer: reject autosteer";
CM_ SG_ 568 UI_rejectHandsOn "Touchscreen user interface computer: reject hands on";
CM_ SG_ 568 UI_acceptBottsDots "Touchscreen user interface computer: accept botts dots";
CM_ SG_ 568 UI_autosteerRestricted "Autopilot map is autostreer restricted.";
CM_ SG_ 568 UI_pmmEnabled "Touchscreen user interface computer: pmm enabled";
CM_ SG_ 568 UI_scaEnabled "Touchscreen user interface computer: sca enabled";
CM_ SG_ 568 UI_mapDataCounter "Touchscreen user interface computer: map data counter";
CM_ SG_ 568 UI_mapDataChecksum "Touchscreen user interface computer: map data checksum";
CM_ BO_ 536 "Touchscreen user interface computer message: driver assist road sign";
CM_ SG_ 536 UI_roadSign "Touchscreen user interface computer: road sign";
CM_ SG_ 536 UI_splineLocConfidence "Touchscreen user interface computer: spline loc confidence";
CM_ SG_ 536 UI_splineID "Touchscreen user interface computer: spline ID";
CM_ SG_ 536 UI_roadSignCounter "Touchscreen user interface computer: road sign counter";
CM_ SG_ 536 UI_roadSignChecksum "Touchscreen user interface computer: road sign checksum";
CM_ SG_ 536 UI_dummyData "Touchscreen user interface computer: dummy data";
CM_ SG_ 536 UI_stopSignStopLineDist "Touchscreen user interface computer: stop sign stop line dist";
CM_ SG_ 536 UI_stopSignStopLineConf "Touchscreen user interface computer: stop sign stop line conf";
CM_ SG_ 536 UI_trafficLightStopLineDist "Touchscreen user interface computer: traffic light stop line dist";
CM_ SG_ 536 UI_trafficLightStopLineConf "Touchscreen user interface computer: traffic light stop line conf";
CM_ SG_ 536 UI_baseMapSpeedLimitMPS "Touchscreen user interface computer: base map speed limit MPS";
CM_ SG_ 536 UI_bottomQrtlFleetSpeedMPS "Touchscreen user interface computer: bottom qrtl fleet speed MPS";
CM_ SG_ 536 UI_topQrtlFleetSpeedMPS "Touchscreen user interface computer: top qrtl fleet speed MPS";
CM_ SG_ 536 UI_meanFleetSplineSpeedMPS "Touchscreen user interface computer: mean fleet spline speed MPS";
CM_ SG_ 536 UI_medianFleetSpeedMPS "Touchscreen user interface computer: median fleet speed MPS";
CM_ SG_ 536 UI_meanFleetSplineAccelMPS2 "Touchscreen user interface computer: mean fleet spline accel MPS2";
CM_ SG_ 536 UI_rampType "Touchscreen user interface computer: ramp type";
CM_ SG_ 536 UI_valhallaRamp "Touchscreen user interface computer: valhalla ramp";
CM_ SG_ 536 UI_overrideACMFleetSpeed "Touchscreen user interface computer: override ACM fleet speed";
CM_ SG_ 536 UI_currSplineIdFull "Touchscreen user interface computer: curr spline id full";
CM_ BO_ 645 "Touchscreen user interface computer message: driver profile recall";
CM_ SG_ 645 UI_driverProfileRecallIndex "Touchscreen user interface computer: driver profile recall index";
CM_ SG_ 645 UI_driverProfileRecallStop "notifies controller to stop profile recall action";
CM_ SG_ 645 UI_frontSeatRecallActive "signals when driver seat presets are being recalled";
CM_ SG_ 645 UI_frontSeatTrackPos "Touchscreen user interface computer: front seat track pos";
CM_ SG_ 645 UI_frontSeatBackPos "Touchscreen user interface computer: front seat back pos";
CM_ SG_ 645 UI_frontSeatLiftPos "Touchscreen user interface computer: front seat lift pos";
CM_ SG_ 645 UI_frontSeatTiltPos "Touchscreen user interface computer: front seat tilt pos";
CM_ SG_ 645 UI_columnAndLumbarRecallActive "Touchscreen user interface computer: column and lumbar recall active";
CM_ SG_ 645 UI_steeringColumnUpDownPos "Touchscreen user interface computer: steering column up down pos";
CM_ SG_ 645 UI_lumbarAPressurePercentage "Touchscreen user interface computer: lumbar a pressure percentage";
CM_ SG_ 645 UI_lumbarBPressurePercentage "Touchscreen user interface computer: lumbar b pressure percentage";
CM_ SG_ 645 UI_steeringColumnInOutPos "Touchscreen user interface computer: steering column in out pos";
CM_ SG_ 645 UI_leftMirrorTiltXPosition "signal from ui to command mirror X tilt position";
CM_ SG_ 645 UI_leftMirrorTiltYPosition "signal from ui to command mirror Y tilt position";
CM_ SG_ 645 UI_rightMirrorTiltXPosition "Touchscreen user interface computer: right mirror tilt x position";
CM_ SG_ 645 UI_rightMirrorTiltYPosition "Touchscreen user interface computer: right mirror tilt y position";
CM_ SG_ 645 UI_frontSeatThighSupportPos "Touchscreen user interface computer: front seat thigh support pos";
CM_ SG_ 645 UI_mirrorRecallActive "Touchscreen user interface computer: mirror recall active";
CM_ SG_ 645 UI_customMirrorDipPositionsSet "Reports whether custom mirror dip positions are set.";
CM_ SG_ 645 UI_leftMirrorDipXPosition "signal from ui to command left mirror X dip position";
CM_ SG_ 645 UI_leftMirrorDipYPosition "signal from ui to command mirror Y dip position";
CM_ SG_ 645 UI_rightMirrorDipXPosition "Touchscreen user interface computer: right mirror dip x position";
CM_ SG_ 645 UI_rightMirrorDipYPosition "Touchscreen user interface computer: right mirror dip y position";
CM_ SG_ 645 UI_modifyMirrorDipRequest "Reports that a user is trying to modify the mirrors in the dipped position.";
CM_ BO_ 647 "Touchscreen user interface computer message: driver profile recall2";
CM_ SG_ 647 UI_driverProfileLinkedKeySHA1 "Touchscreen user interface computer: driver profile linked key SHA1";
CM_ SG_ 647 UI_driverProfileIndex "Tracks manual driver profile selection. Shows the linked phonekey / key card / key fob or profile index if not linked";
CM_ SG_ 647 UI_driverProfileSelectionType "Tracks manual driver profile selection. Shows the linked phonekey / key card / key fob or profile index if not linked";
CM_ SG_ 647 UI_driverProfilePositionAdjusted "Tracks adjustments to driver profile. Sets when a profile position has been adjusted from what was saved";
CM_ SG_ 647 UI_activeKeyRequested "Tracks manual driver profile selection. Shows the linked phonekey / key card / key fob or profile index if not linked";
CM_ BO_ 1971 "Touchscreen user interface computer message: dynamic triggers campaign fired";
CM_ SG_ 1971 UI_campaignFired "Touchscreen user interface computer: campaign fired";
CM_ BO_ 984 "Touchscreen user interface computer message: elevation status";
CM_ SG_ 984 UI_elevation "Touchscreen user interface computer: elevation";
CM_ SG_ 984 UI_navElevation "Touchscreen user interface computer: nav elevation";
CM_ BO_ 1279 "Touchscreen user interface computer message: energy consumption info";
CM_ SG_ 1279 UI_energyConsumptionInfoIndex "Touchscreen user interface computer: energy consumption info index";
CM_ SG_ 1279 UI_energyLossTotal_epa "Energy amount for a given bucket for an energy consumption baseline (raw/real energy consumed)";
CM_ SG_ 1279 UI_energyLossDriving_epa "Energy amount for a given bucket for an energy consumption baseline (raw/real energy consumed)";
CM_ SG_ 1279 UI_energyLossClimate_epa "Energy amount for a given bucket for an energy consumption baseline (raw/real energy consumed)";
CM_ SG_ 1279 UI_energyLossBattCond_epa "Energy amount for a given bucket for an energy consumption baseline (raw/real energy consumed)";
CM_ SG_ 1279 UI_energyLossElevation_epa "Energy amount for a given bucket for an energy consumption baseline (raw/real energy consumed)";
CM_ SG_ 1279 UI_energyLossAcc_epa "Energy amount for a given bucket for an energy consumption baseline (raw/real energy consumed)";
CM_ SG_ 1279 UI_energyLossTotalSinceCharge_ep "Energy amount for a given bucket for an energy consumption baseline (raw/real energy consumed)";
CM_ SG_ 1279 UI_energyLossDrivingSinceCharge_ "Energy amount for a given bucket for an energy consumption baseline (raw/real energy consumed)";
CM_ SG_ 1279 UI_energyLossClimateSinceCharge_ "Energy amount for a given bucket for an energy consumption baseline (raw/real energy consumed)";
CM_ SG_ 1279 UI_energyLossBattCondSinceCharge "Energy amount for a given bucket for an energy consumption baseline (raw/real energy consumed)";
CM_ SG_ 1279 UI_energyLossElevationSinceCharg "Energy amount for a given bucket for an energy consumption baseline (raw/real energy consumed)";
CM_ SG_ 1279 UI_energyLossAccSinceCharge_epa "Energy amount for a given bucket for an energy consumption baseline (raw/real energy consumed)";
CM_ SG_ 1279 UI_energyLossTotalSinceTripStart "Energy amount for a given bucket for an energy consumption baseline (raw/real energy consumed)";
CM_ SG_ 1279 UI_energyLossDrivingSinceTripSta "Energy amount for a given bucket for an energy consumption baseline (raw/real energy consumed)";
CM_ SG_ 1279 UI_energyLossClimateSinceTripSta "Energy amount for a given bucket for an energy consumption baseline (raw/real energy consumed)";
CM_ SG_ 1279 UI_energyLossBattCondSinceTripSt "Energy amount for a given bucket for an energy consumption baseline (raw/real energy consumed)";
CM_ SG_ 1279 UI_energyLossElevationSinceTripS "Energy amount for a given bucket for an energy consumption baseline (raw/real energy consumed)";
CM_ SG_ 1279 UI_energyLossAccSinceTripStart "Energy amount for a given bucket for an energy consumption baseline (raw/real energy consumed)";
CM_ SG_ 1279 UI_energyDeltaTotal_epa "Energy amount for a given bucket for an energy consumption baseline (raw/real energy consumed)";
CM_ SG_ 1279 UI_energyDeltaDriving_epa "Energy amount for a given bucket for an energy consumption baseline (raw/real energy consumed)";
CM_ SG_ 1279 UI_energyDeltaClimate_epa "Energy amount for a given bucket for an energy consumption baseline (raw/real energy consumed)";
CM_ SG_ 1279 UI_energyDeltaBattCond_epa "Energy amount for a given bucket for an energy consumption baseline (raw/real energy consumed)";
CM_ SG_ 1279 UI_energyDeltaElevation_epa "Energy amount for a given bucket for an energy consumption baseline (raw/real energy consumed)";
CM_ SG_ 1279 UI_energyDeltaAcc_epa "Energy amount for a given bucket for an energy consumption baseline (raw/real energy consumed)";
CM_ SG_ 1279 UI_uiDeltaOffsetTotal_epa "Energy amount for a given bucket for an energy consumption baseline (raw/real energy consumed)";
CM_ SG_ 1279 UI_uiDeltaOffsetDriving_epa "Energy amount for a given bucket for an energy consumption baseline (raw/real energy consumed)";
CM_ SG_ 1279 UI_uiDeltaOffsetClimate_epa "Energy amount for a given bucket for an energy consumption baseline (raw/real energy consumed)";
CM_ SG_ 1279 UI_uiDeltaOffsetBattCond_epa "Energy amount for a given bucket for an energy consumption baseline (raw/real energy consumed)";
CM_ SG_ 1279 UI_uiDeltaOffsetElevation_epa "Energy amount for a given bucket for an energy consumption baseline (raw/real energy consumed)";
CM_ SG_ 1279 UI_uiDeltaOffsetAcc_epa "Energy amount for a given bucket for an energy consumption baseline (raw/real energy consumed)";
CM_ SG_ 1279 UI_rawToUiEnergyRatio_epa "Ratio used for conversion between UI and raw energy domains";
CM_ SG_ 1279 UI_driveDistance_epa "Distance driven for an energy consumption baseline";
CM_ SG_ 1279 UI_energyDeltaTotalSinceCharge_e "Energy amount for a given bucket for an energy consumption baseline (raw/real energy consumed)";
CM_ SG_ 1279 UI_energyDeltaDrivingSinceCharge "Energy amount for a given bucket for an energy consumption baseline (raw/real energy consumed)";
CM_ SG_ 1279 UI_energyDeltaClimateSinceCharge "Energy amount for a given bucket for an energy consumption baseline (raw/real energy consumed)";
CM_ SG_ 1279 UI_energyDeltaBattCondSinceCharg "Energy amount for a given bucket for an energy consumption baseline (raw/real energy consumed)";
CM_ SG_ 1279 UI_energyDeltaElevationSinceChar "Energy amount for a given bucket for an energy consumption baseline (raw/real energy consumed)";
CM_ SG_ 1279 UI_energyDeltaAccSinceCharge_epa "Energy amount for a given bucket for an energy consumption baseline (raw/real energy consumed)";
CM_ SG_ 1279 UI_uiDeltaOffsetTotalSinceCharge "Energy amount for a given bucket for an energy consumption baseline (raw/real energy consumed)";
CM_ SG_ 1279 UI_uiDeltaOffsetDrivingSinceChar "Energy amount for a given bucket for an energy consumption baseline (raw/real energy consumed)";
CM_ SG_ 1279 UI_uiDeltaOffsetClimateSinceChar "Energy amount for a given bucket for an energy consumption baseline (raw/real energy consumed)";
CM_ SG_ 1279 UI_uiDeltaOffsetBattCondSinceCha "Energy amount for a given bucket for an energy consumption baseline (raw/real energy consumed)";
CM_ SG_ 1279 UI_uiDeltaOffsetElevationSinceCh "Energy amount for a given bucket for an energy consumption baseline (raw/real energy consumed)";
CM_ SG_ 1279 UI_uiDeltaOffsetAccSinceCharge_e "Energy amount for a given bucket for an energy consumption baseline (raw/real energy consumed)";
CM_ SG_ 1279 UI_rawToUiEnergyRatioSinceCharge "Ratio used for conversion between UI and raw energy domains";
CM_ SG_ 1279 UI_driveDistanceSinceCharge_epa "Distance driven for an energy consumption baseline";
CM_ SG_ 1279 UI_energyDeltaTotalSinceTripStar "Energy amount for a given bucket for an energy consumption baseline (raw/real energy consumed)";
CM_ SG_ 1279 UI_energyDeltaDrivingSinceTripSt "Energy amount for a given bucket for an energy consumption baseline (raw/real energy consumed)";
CM_ SG_ 1279 UI_energyDeltaClimateSinceTripSt "Energy amount for a given bucket for an energy consumption baseline (raw/real energy consumed)";
CM_ SG_ 1279 UI_energyDeltaBattCondSinceTripS "Energy amount for a given bucket for an energy consumption baseline (raw/real energy consumed)";
CM_ SG_ 1279 UI_energyDeltaElevationSinceTrip "Energy amount for a given bucket for an energy consumption baseline (raw/real energy consumed)";
CM_ SG_ 1279 UI_energyDeltaAccSinceTripStart "Energy amount for a given bucket for an energy consumption baseline (raw/real energy consumed)";
CM_ SG_ 1279 UI_uiDeltaOffsetTotalSinceTripSt "Energy amount for a given bucket for an energy consumption baseline (raw/real energy consumed)";
CM_ SG_ 1279 UI_uiDeltaOffsetDrivingSinceTrip "Energy amount for a given bucket for an energy consumption baseline (raw/real energy consumed)";
CM_ SG_ 1279 UI_uiDeltaOffsetClimateSinceTrip "Energy amount for a given bucket for an energy consumption baseline (raw/real energy consumed)";
CM_ SG_ 1279 UI_uiDeltaOffsetBattCondSinceTri "Energy amount for a given bucket for an energy consumption baseline (raw/real energy consumed)";
CM_ SG_ 1279 UI_uiDeltaOffsetElevationSinceTr "Energy amount for a given bucket for an energy consumption baseline (raw/real energy consumed)";
CM_ SG_ 1279 UI_uiDeltaOffsetAccSinceTripStar "Energy amount for a given bucket for an energy consumption baseline (raw/real energy consumed)";
CM_ SG_ 1279 UI_rawToUiEnergyRatioSinceTripSt "Ratio used for conversion between UI and raw energy domains";
CM_ SG_ 1279 UI_driveDistanceSinceTripStart "Distance driven for an energy consumption baseline";
CM_ SG_ 1279 UI_voyagerEnabled "Touchscreen user interface computer: voyager enabled";
CM_ SG_ 1279 UI_trailerMass "Trailer mass from user input";
CM_ BO_ 1139 "Touchscreen user interface computer message: eth nm";
CM_ SG_ 1139 UI_nmGoingToSleep "Touchscreen user interface computer: nm going to sleep";
CM_ SG_ 1139 UI_nmKeepAwakeReason "reason UI is being kept awake";
CM_ SG_ 1139 UI_wakeupTime "Unix epoch time at which vehicle should wake for scheduled charge or update.";
CM_ BO_ 1267 "Touchscreen user interface computer message: front seat requests";
CM_ SG_ 1267 UI_frontRightSeatTrackForward "Touchscreen user interface computer: front right seat track forward";
CM_ SG_ 1267 UI_frontRightSeatTrackBack "Touchscreen user interface computer: front right seat track back";
CM_ SG_ 1267 UI_frontLeftSeatTrackForward "Touchscreen user interface computer: front left seat track forward";
CM_ SG_ 1267 UI_frontLeftSeatTrackBack "Touchscreen user interface computer: front left seat track back";
CM_ SG_ 1267 UI_frontRightSeatBackrestBack "Touchscreen user interface computer: front right seat backrest back";
CM_ SG_ 1267 UI_frontRightSeatBackrestForward "Touchscreen user interface computer: front right seat backrest forward";
CM_ SG_ 1267 UI_frontLeftSeatBackrestBack "Touchscreen user interface computer: front left seat backrest back";
CM_ SG_ 1267 UI_frontLeftSeatBackrestForward "Touchscreen user interface computer: front left seat backrest forward";
CM_ SG_ 1267 UI_frontRightSeatTiltUp "Touchscreen user interface computer: front right seat tilt up";
CM_ SG_ 1267 UI_frontRightSeatTiltDown "Touchscreen user interface computer: front right seat tilt down";
CM_ SG_ 1267 UI_frontLeftSeatTiltUp "Touchscreen user interface computer: front left seat tilt up";
CM_ SG_ 1267 UI_frontLeftSeatTiltDown "Touchscreen user interface computer: front left seat tilt down";
CM_ SG_ 1267 UI_frontRightSeatLiftUp "Touchscreen user interface computer: front right seat lift up";
CM_ SG_ 1267 UI_frontRightSeatLiftDown "Touchscreen user interface computer: front right seat lift down";
CM_ SG_ 1267 UI_frontLeftSeatLiftUp "Touchscreen user interface computer: front left seat lift up";
CM_ SG_ 1267 UI_frontLeftSeatLiftDown "Touchscreen user interface computer: front left seat lift down";
CM_ SG_ 1267 UI_frontLeftSeatLumbarUp "Touchscreen user interface computer: front left seat lumbar up";
CM_ SG_ 1267 UI_frontLeftSeatLumbarDown "Touchscreen user interface computer: front left seat lumbar down";
CM_ SG_ 1267 UI_frontRightSeatLumbarUp "Touchscreen user interface computer: front right seat lumbar up";
CM_ SG_ 1267 UI_frontRightSeatLumbarDown "Touchscreen user interface computer: front right seat lumbar down";
CM_ SG_ 1267 UI_frontLeftSeatLumbarIn "Touchscreen user interface computer: front left seat lumbar in";
CM_ SG_ 1267 UI_frontLeftSeatLumbarOut "Touchscreen user interface computer: front left seat lumbar out";
CM_ SG_ 1267 UI_frontRightSeatLumbarIn "Touchscreen user interface computer: front right seat lumbar in";
CM_ SG_ 1267 UI_frontRightSeatLumbarOut "Touchscreen user interface computer: front right seat lumbar out";
CM_ SG_ 1267 UI_seatAdjustmentSource "Touchscreen user interface computer: seat adjustment source";
CM_ BO_ 993 "Touchscreen user interface computer message: gear slider info";
CM_ SG_ 993 UI_gearSliderInfoIndex "Touchscreen user interface computer: gear slider info index";
CM_ SG_ 993 UI_gearSliderW "Touchscreen user interface computer: gear slider w";
CM_ SG_ 993 UI_gearSliderH "Touchscreen user interface computer: gear slider h";
CM_ SG_ 993 UI_gearSliderX "Touchscreen user interface computer: gear slider x";
CM_ SG_ 993 UI_gearSliderY "Touchscreen user interface computer: gear slider y";
CM_ SG_ 993 UI_gearParkW "Touchscreen user interface computer: gear park w";
CM_ SG_ 993 UI_gearParkH "Touchscreen user interface computer: gear park h";
CM_ SG_ 993 UI_gearParkX "Touchscreen user interface computer: gear park x";
CM_ SG_ 993 UI_gearParkY "Touchscreen user interface computer: gear park y";
CM_ SG_ 993 UI_gearNeutralW "Touchscreen user interface computer: gear neutral w";
CM_ SG_ 993 UI_gearNeutralH "Touchscreen user interface computer: gear neutral h";
CM_ SG_ 993 UI_gearNeutralX "Touchscreen user interface computer: gear neutral x";
CM_ SG_ 993 UI_gearNeutralY "Touchscreen user interface computer: gear neutral y";
CM_ BO_ 804 "Touchscreen user interface computer message: gps time";
CM_ SG_ 804 UI_gpsTime "Touchscreen user interface computer: gps time";
CM_ BO_ 985 "Touchscreen user interface computer message: gps vehicle speed";
CM_ SG_ 985 UI_gpsHDOP "Touchscreen user interface computer: gps HDOP";
CM_ SG_ 985 UI_gpsVehicleHeading "Touchscreen user interface computer: gps vehicle heading";
CM_ SG_ 985 UI_gpsVehicleSpeed "Touchscreen user interface computer: gps vehicle speed";
CM_ SG_ 985 UI_userSpeedOffset "Touchscreen user interface computer: user speed offset";
CM_ SG_ 985 UI_mapSpeedLimitUnits "Autopilot map speed limit units.";
CM_ SG_ 985 UI_userSpeedOffsetUnits "Touchscreen user interface computer: user speed offset units";
CM_ SG_ 985 UI_mppSpeedLimit "Autopilot map speed limit";
CM_ SG_ 985 UI_gpsNmeaMIA "GPS NMEA data MIA";
CM_ SG_ 985 UI_gpsAntennaDisconnected "GPS antenna state";
CM_ SG_ 985 UI_conditionalLimitActive "Conditional speed limit condition is currently active";
CM_ SG_ 985 UI_conditionalSpeedLimit "Conditional speed limit value";
CM_ BO_ 912 "Touchscreen user interface computer message: grid form control";
CM_ SG_ 912 UI_dischargeTerminationPct "Reports the minimum State of Energy (SOE) to which the vehicle will discharge for powering outlets, Vehicle to Load (V2L), or Vehicle to Home (V2H).";
CM_ SG_ 912 UI_v2lFeatureRequest "Touchscreen user interface computer: v2l feature request";
CM_ SG_ 912 UI_powershareRequest "Controls the start and stop of powersharing.";
CM_ BO_ 755 "Touchscreen user interface computer message: hvac request";
CM_ SG_ 755 UI_hvacReqTempSetpointLeft "HVAC left set temperature.";
CM_ SG_ 755 UI_hvacReqAutoBlowerLevel "Reports the auto Heating, Ventilation, and Air Conditioning (HVAC) speed aggressiveness setting.";
CM_ SG_ 755 UI_hvacReqTempSetpointRight "HVAC right set temperature.";
CM_ SG_ 755 UI_hvacReqAirDistributionMode "Request for air distribution mode.";
CM_ SG_ 755 UI_hvacReqBlowerSegment "HVAC manual blower request (GUI_hvacManualBlowerRequest)";
CM_ SG_ 755 UI_hvacReqRecirc "HVAC recirculation mode";
CM_ SG_ 755 UI_hvacReqACDisable "Request to disable AC.";
CM_ SG_ 755 UI_hvacDefogState "HVAC defog state.";
CM_ SG_ 755 UI_hvacReqUserPowerState "Reports HVAC power state.";
CM_ SG_ 755 UI_hvacReqSecondRowState "HVAC rear fan request speed.";
CM_ SG_ 755 UI_hvacUseModeledDuctTemp "Touchscreen user interface computer: hvac use modeled duct temp";
CM_ SG_ 755 UI_hvacReqKeepClimateOn "Request accessory power";
CM_ SG_ 755 UI_hvacReqBioWeaponDefMode "Request for BioWeapon Defense Mode";
CM_ SG_ 755 UI_hvacLatchPassengerPresent "Touchscreen user interface computer: hvac latch passenger present";
CM_ SG_ 755 UI_enableHvacControlsFeatures1 "Touchscreen user interface computer: enable hvac controls features1";
CM_ SG_ 755 UI_enableHvacNotifications "Touchscreen user interface computer: enable hvac notifications";
CM_ SG_ 755 UI_hvacPhoneCallAirFlowAdjustEna "Touchscreen user interface computer: hvac phone call air flow adjust enabled";
CM_ SG_ 755 UI_enableHvacVOCPurgeRoutine "Touchscreen user interface computer: enable hvac VOC purge routine";
CM_ SG_ 755 UI_enableCustomerTHSAlerts "Touchscreen user interface computer: enable customer THS alerts";
CM_ SG_ 755 UI_evapDryingSelectiveEnable "Touchscreen user interface computer: evap drying selective enable";
CM_ SG_ 755 UI_enableHvacWeatherDataBasedHum "Touchscreen user interface computer: enable hvac weather data based humidity controls";
CM_ SG_ 755 UI_hvacReqTempSetpointCOP "HVAC cabin overheat protection set temperature.";
CM_ SG_ 755 UI_hvacClimateNudgeStatus "Touchscreen user interface computer: hvac climate nudge status";
CM_ SG_ 755 UI_enableHvacControlsFeatures2 "Touchscreen user interface computer: enable hvac controls features2";
CM_ SG_ 755 UI_enableHvacAPFoggingMonitor "Touchscreen user interface computer: enable hvac AP fogging monitor";
CM_ SG_ 755 UI_enableHvacLimpMode "Touchscreen user interface computer: enable hvac limp mode";
CM_ BO_ 989 "Touchscreen user interface computer message: location offset";
CM_ SG_ 989 UI_latitudeOffset "Touchscreen user interface computer: latitude offset";
CM_ SG_ 989 UI_longitudeOffset "Touchscreen user interface computer: longitude offset";
CM_ BO_ 777 "Touchscreen user interface computer message: location status";
CM_ SG_ 777 UI_latitude "Touchscreen user interface computer: latitude";
CM_ SG_ 777 UI_longitude "Touchscreen user interface computer: longitude";
CM_ SG_ 777 UI_gpsAccuracy "Touchscreen user interface computer: gps accuracy";
CM_ BO_ 1011 "Touchscreen user interface computer message: odo";
CM_ SG_ 1011 UI_odometer "Odometer";
CM_ BO_ 948 "Touchscreen user interface computer message: peripheral power requests";
CM_ SG_ 948 UI_usbFrontHubPowerStateRequest "Reports the Universal Serial Bus (USB) Hub power request.";
CM_ BO_ 987 "Touchscreen user interface computer message: phone location status";
CM_ SG_ 987 UI_phoneLatitude "Touchscreen user interface computer: phone latitude";
CM_ SG_ 987 UI_phoneLongitude "Touchscreen user interface computer: phone longitude";
CM_ SG_ 987 UI_phoneGpsAccuracy "Touchscreen user interface computer: phone gps accuracy";
CM_ BO_ 955 "Touchscreen user interface computer message: power";
CM_ SG_ 955 UI_powerExpected "Touchscreen user interface computer: power expected";
CM_ SG_ 955 UI_powerIdeal "Touchscreen user interface computer: power ideal";
CM_ SG_ 955 UI_dSocAlertEnable "Set when the BMS_a117_SW_Delta_SOC_Weak_Short alert for the BMS should have a functional response";
CM_ SG_ 955 UI_dSocAlertThreshold "Touchscreen user interface computer: d soc alert threshold";
CM_ BO_ 827 "Touchscreen user interface computer message: power estimates";
CM_ SG_ 827 UI_idlePowerConsumption "Power consumption when idle";
CM_ SG_ 827 UI_chargeTimeUntilTerminationPct "Charge time minutes until reached uSoe target";
CM_ SG_ 827 UI_isTripChargingActive "Touchscreen user interface computer: is trip charging active";
CM_ SG_ 827 UI_chargeTimeUntilReadyToDepart "Charge time minutes until enough energy to depart for rest of trip";
CM_ BO_ 629 "Touchscreen user interface computer message: power rationality config";
CM_ SG_ 629 UI_powerRationalityConfigIndex "Touchscreen user interface computer: power rationality config index";
CM_ SG_ 629 UI_vcleftCfgRationalityThreshold "Touchscreen user interface computer: vcleft cfg rationality threshold0";
CM_ SG_ 629 UI_vcleftCfgRationalityTime0 "Touchscreen user interface computer: vcleft cfg rationality time0";
CM_ SG_ 629 UI_vcleftCfgRationalityThre_0001 "Touchscreen user interface computer: vcleft cfg rationality threshold1";
CM_ SG_ 629 UI_vcleftCfgRationalityTime1 "Touchscreen user interface computer: vcleft cfg rationality time1";
CM_ SG_ 629 UI_vcleftCfgRationalityStaticA "Touchscreen user interface computer: vcleft cfg rationality static a";
CM_ SG_ 629 UI_vcleftCfgRationalityStaticB "Touchscreen user interface computer: vcleft cfg rationality static b";
CM_ SG_ 629 UI_vcleftCfgRationalityStaticC "Touchscreen user interface computer: vcleft cfg rationality static c";
CM_ SG_ 629 UI_vcleftCfgRationalityDynamicA "Touchscreen user interface computer: vcleft cfg rationality dynamic a";
CM_ SG_ 629 UI_vcleftCfgRationalityDynamicB "Touchscreen user interface computer: vcleft cfg rationality dynamic b";
CM_ SG_ 629 UI_vcleftCfgRationalityDynamicC "Touchscreen user interface computer: vcleft cfg rationality dynamic c";
CM_ SG_ 629 UI_vcrightCfgRationalityThreshol "Touchscreen user interface computer: vcright cfg rationality threshold0";
CM_ SG_ 629 UI_vcrightCfgRationalityTime0 "Touchscreen user interface computer: vcright cfg rationality time0";
CM_ SG_ 629 UI_vcrightCfgRationalityThr_0001 "Touchscreen user interface computer: vcright cfg rationality threshold1";
CM_ SG_ 629 UI_vcrightCfgRationalityTime1 "Touchscreen user interface computer: vcright cfg rationality time1";
CM_ SG_ 629 UI_vcrightCfgRationalityStaticA "Touchscreen user interface computer: vcright cfg rationality static a";
CM_ SG_ 629 UI_vcrightCfgRationalityStaticB "Touchscreen user interface computer: vcright cfg rationality static b";
CM_ SG_ 629 UI_vcrightCfgRationalityStaticC "Touchscreen user interface computer: vcright cfg rationality static c";
CM_ SG_ 629 UI_vcrightCfgRationalityDynamicA "Touchscreen user interface computer: vcright cfg rationality dynamic a";
CM_ SG_ 629 UI_vcrightCfgRationalityDynamicB "Touchscreen user interface computer: vcright cfg rationality dynamic b";
CM_ SG_ 629 UI_vcrightCfgRationalityDynamicC "Touchscreen user interface computer: vcright cfg rationality dynamic c";
CM_ SG_ 629 UI_vcleftCfgCutoffThreshold0 "Touchscreen user interface computer: vcleft cfg cutoff threshold0";
CM_ SG_ 629 UI_vcleftCfgCutoffTime0 "Touchscreen user interface computer: vcleft cfg cutoff time0";
CM_ SG_ 629 UI_vcleftCfgCutoffThreshold1 "Touchscreen user interface computer: vcleft cfg cutoff threshold1";
CM_ SG_ 629 UI_vcleftCfgCutoffTime1 "Touchscreen user interface computer: vcleft cfg cutoff time1";
CM_ SG_ 629 UI_vcleftCfgCutoffStaticA "Touchscreen user interface computer: vcleft cfg cutoff static a";
CM_ SG_ 629 UI_vcleftCfgCutoffStaticB "Touchscreen user interface computer: vcleft cfg cutoff static b";
CM_ SG_ 629 UI_vcleftCfgCutoffStaticC "Touchscreen user interface computer: vcleft cfg cutoff static c";
CM_ SG_ 629 UI_vcleftCfgCutoffDynamicA "Touchscreen user interface computer: vcleft cfg cutoff dynamic a";
CM_ SG_ 629 UI_vcleftCfgCutoffDynamicB "Touchscreen user interface computer: vcleft cfg cutoff dynamic b";
CM_ SG_ 629 UI_vcleftCfgCutoffDynamicC "Touchscreen user interface computer: vcleft cfg cutoff dynamic c";
CM_ SG_ 629 UI_vcrightCfgCutoffThreshold0 "Touchscreen user interface computer: vcright cfg cutoff threshold0";
CM_ SG_ 629 UI_vcrightCfgCutoffTime0 "Touchscreen user interface computer: vcright cfg cutoff time0";
CM_ SG_ 629 UI_vcrightCfgCutoffThreshold1 "Touchscreen user interface computer: vcright cfg cutoff threshold1";
CM_ SG_ 629 UI_vcrightCfgCutoffTime1 "Touchscreen user interface computer: vcright cfg cutoff time1";
CM_ SG_ 629 UI_vcrightCfgCutoffStaticA "Touchscreen user interface computer: vcright cfg cutoff static a";
CM_ SG_ 629 UI_vcrightCfgCutoffStaticB "Touchscreen user interface computer: vcright cfg cutoff static b";
CM_ SG_ 629 UI_vcrightCfgCutoffStaticC "Touchscreen user interface computer: vcright cfg cutoff static c";
CM_ SG_ 629 UI_vcrightCfgCutoffDynamicA "Touchscreen user interface computer: vcright cfg cutoff dynamic a";
CM_ SG_ 629 UI_vcrightCfgCutoffDynamicB "Touchscreen user interface computer: vcright cfg cutoff dynamic b";
CM_ SG_ 629 UI_vcrightCfgCutoffDynamicC "Touchscreen user interface computer: vcright cfg cutoff dynamic c";
CM_ BO_ 820 "Touchscreen user interface computer message: powertrain control";
CM_ SG_ 820 UI_systemPowerLimit "Touchscreen user interface computer: system power limit";
CM_ SG_ 820 UI_pedalMap "Switch between various platform specific pedal maps";
CM_ SG_ 820 UI_enableRegenBackfill "Indicates if regenerative braking backfill has been enabled by the driver";
CM_ SG_ 820 UI_systemTorqueLimit "Touchscreen user interface computer: system torque limit";
CM_ SG_ 820 UI_closureConfirmed "Touchscreen user interface computer: closure confirmed";
CM_ SG_ 820 UI_regenTorqueMax "Maximum regen torque from UI - reports different value when in track mode";
CM_ SG_ 820 UI_limitMode "Commands limited drive inverter capabilities based on special vehicle modes";
CM_ SG_ 820 UI_factoryCustomerDrivingModeReq "Touchscreen user interface computer: factory customer driving mode request";
CM_ SG_ 820 UI_motorOnMode "Request from the UI to selectively enable or disable a drive unit (dev-only)";
CM_ SG_ 820 UI_stoppingMode "Low-speed behavior when no pedal is pressed (stopping/rolling/creeping)";
CM_ SG_ 820 UI_DIAppSliderDebug "Touchscreen user interface computer: DI app slider debug";
CM_ SG_ 820 UI_speedLimit "Maximum allowed speed enforced at vehicle level.";
CM_ SG_ 820 UI_enableSmartShift "Stalkless convenience feature that allows unparking with only a firm press of brake pedal";
CM_ SG_ 820 UI_navVehParallelToRdCanContinue "Whether the vehicle is parallel parked on a public road";
CM_ SG_ 820 UI_powertrainControlCounter "Touchscreen user interface computer: powertrain control counter";
CM_ SG_ 820 UI_powertrainControlChecksum "Touchscreen user interface computer: powertrain control checksum";
CM_ BO_ 698 "Touchscreen user interface computer message: radar map data";
CM_ SG_ 698 UI_radarTargetDx "Touchscreen user interface computer: radar target dx";
CM_ SG_ 698 UI_radarTargetDxEnd "Touchscreen user interface computer: radar target dx end";
CM_ SG_ 698 UI_radarTargetTrustMap "Touchscreen user interface computer: radar target trust map";
CM_ SG_ 698 UI_radarEnableBraking "Touchscreen user interface computer: radar enable braking";
CM_ SG_ 698 UI_radarMapDataCounter "Touchscreen user interface computer: radar map data counter";
CM_ SG_ 698 UI_radarMapDataChecksum "Touchscreen user interface computer: radar map data checksum";
CM_ BO_ 826 "Touchscreen user interface computer message: range";
CM_ SG_ 826 UI_ratedRange "Rated range in miles";
CM_ SG_ 826 UI_whpm "Touchscreen user interface computer: whpm";
CM_ SG_ 826 UI_soe "State of energy";
CM_ SG_ 826 UI_uSoe "Usable state of energy";
CM_ SG_ 826 UI_softPackLimitPct "Touchscreen user interface computer: soft pack limit pct";
CM_ SG_ 826 UI_targetFullPackEnergy "Touchscreen user interface computer: target full pack energy";
CM_ BO_ 632 "Touchscreen user interface computer message: road curvature";
CM_ SG_ 632 UI_roadCurvC0 "Touchscreen user interface computer: road curv C0";
CM_ SG_ 632 UI_roadCurvC1 "Touchscreen user interface computer: road curv C1";
CM_ SG_ 632 UI_roadCurvC2 "Touchscreen user interface computer: road curv C2";
CM_ SG_ 632 UI_roadCurvC3 "Touchscreen user interface computer: road curv C3";
CM_ SG_ 632 UI_roadCurvRange "Touchscreen user interface computer: road curv range";
CM_ SG_ 632 UI_roadCurvHealth "Touchscreen user interface computer: road curv health";
CM_ SG_ 632 UI_roadCurvChecksum "Touchscreen user interface computer: road curv checksum";
CM_ BO_ 666 "Touchscreen user interface computer message: seat control";
CM_ SG_ 666 UI_seatControlIndex "Touchscreen user interface computer: seat control index";
CM_ SG_ 666 UI_3RSeatChildLock "Reports the state of 3rd row seat fold flat child lock from the UI";
CM_ SG_ 666 UI_2RowLeftSeatTrackBack "Touchscreen user interface computer: 2 row left seat track back";
CM_ SG_ 666 UI_2RowLeftSeatTrackForward "Touchscreen user interface computer: 2 row left seat track forward";
CM_ SG_ 666 UI_2RowRightSeatTrackBack "Touchscreen user interface computer: 2 row right seat track back";
CM_ SG_ 666 UI_2RowRightSeatTrackForward "Touchscreen user interface computer: 2 row right seat track forward";
CM_ SG_ 666 UI_left3RowSeatAdjustmentRequest "Reports request from the touchscreen User Interface (UI) to actuate the left third row seat.";
CM_ SG_ 666 UI_right3RowSeatAdjustmentReques "Reports request from the touchscreen User Interface (UI) to actuate the right third row seat.";
CM_ SG_ 666 UI_2RLeftSeatFanReq "Request for second row left seat ventilation";
CM_ SG_ 666 UI_2RRightSeatFanReq "Request for second row right seat ventilation";
CM_ SG_ 666 UI_leftThirdRowSeatRequestFromRe "Touchscreen user interface computer: left third row seat request from rear display";
CM_ SG_ 666 UI_rightThirdRowSeatRequestFromR "Touchscreen user interface computer: right third row seat request from rear display";
CM_ SG_ 666 UI_seatChoreographyStopRequest "Reports if the UI requests to stop the seat choreography";
CM_ BO_ 723 "Touchscreen user interface computer message: solar data";
CM_ SG_ 723 UI_solarAzimuthAngle "Touchscreen user interface computer: solar azimuth angle";
CM_ SG_ 723 UI_solarAzimuthAngleCarRef "Touchscreen user interface computer: solar azimuth angle car ref";
CM_ SG_ 723 UI_isSunUp "is sun up";
CM_ SG_ 723 UI_solarElevationAngle "Solar Elevation Angle";
CM_ SG_ 723 UI_screenPCBTemperature "Temperature of display PCB";
CM_ SG_ 723 UI_minsToSunset "time until to sunset";
CM_ SG_ 723 UI_minsToSunrise "time until to sunrise";
CM_ BO_ 563 "Touchscreen user interface computer message: stalkless control";
CM_ SG_ 563 UI_stalklessControlCounter "Touchscreen user interface computer: stalkless control counter";
CM_ SG_ 563 UI_stalklessControlChecksum "Touchscreen user interface computer: stalkless control checksum";
CM_ SG_ 563 UI_gearStripSuppressCounter "Touchscreen user interface computer: gear strip suppress counter";
CM_ SG_ 563 UI_gearRequest "UI gear request from UI";
CM_ SG_ 563 UI_autopilotRequest "Touchscreen user interface computer: autopilot request";
CM_ SG_ 563 UI_gearStripShowing "UI communicating to GTW that the gear strip is visible on the screen as part of a handshake";
CM_ SG_ 563 UI_gearStripLocation "Touchscreen user interface computer: gear strip location";
CM_ SG_ 563 UI_parkButtonShowing "Touchscreen user interface computer: park button showing";
CM_ SG_ 563 UI_neutralButtonShowing "Touchscreen user interface computer: neutral button showing";
CM_ SG_ 563 UI_gearStripForceShow "UI request to GTW to show the gear strip";
CM_ SG_ 563 UI_neutralButtonDrawerForceShow "Touchscreen user interface computer: neutral button drawer force show";
CM_ SG_ 563 UI_autoParkAvailable "UI communicating to GTW that the autpark functionality is available";
CM_ SG_ 563 UI_autoParkShowing "Touchscreen user interface computer: auto park showing";
CM_ SG_ 563 UI_gearStripSuppressActive "UI communicating to GTW that the gear strip should not be shown";
CM_ SG_ 563 UI_gearNeutralPressed "Neutral button is being pressed";
CM_ BO_ 851 "Touchscreen user interface computer message: status";
CM_ SG_ 851 UI_touchActive "No touchscreen errors";
CM_ SG_ 851 UI_audioActive "Audio system is ready.";
CM_ SG_ 851 UI_bluetoothActive "Touchscreen user interface computer: bluetooth active";
CM_ SG_ 851 UI_cellActive "Cell is powered";
CM_ SG_ 851 UI_displayReady "UI is ready (GUI_allReady) and display is ok (GUI_displayHardwareOK)";
CM_ SG_ 851 UI_displayOn "UI display on/off status";
CM_ SG_ 851 UI_wifiActive "WiFi active.";
CM_ SG_ 851 UI_wifiConnected "WiFi Connected.";
CM_ SG_ 851 UI_systemActive "Touchscreen user interface computer: system active";
CM_ SG_ 851 UI_readyForDrive "Ready for drive (UI ready or self park request)";
CM_ SG_ 851 UI_cellConnected "Detects if the cell is connected to a network.";
CM_ SG_ 851 UI_vpnActive "VPN connected.";
CM_ SG_ 851 UI_autopilotTrial "Touchscreen user interface computer: autopilot trial";
CM_ SG_ 851 UI_factoryReset "UI request for factory reset";
CM_ SG_ 851 UI_gpsActive "GPS has valid fix";
CM_ SG_ 851 UI_screenshotActive "Touchscreen user interface computer: screenshot active";
CM_ SG_ 851 UI_radioActive "Touchscreen user interface computer: radio active";
CM_ SG_ 851 UI_cellNetworkTechnology "Describes the type of cellular network to which the car computer is connected: GPRS_2G(114Kbps) < EGDE_2G(368Kbps) < 3G(3Mbps) < HSDPA_3G(14Mbps) < HSPAplus_4Gg(168Mbps) < 4G_LTE(299Mbps)";
CM_ SG_ 851 UI_cellReceiverPower "Touchscreen user interface computer: cell receiver power";
CM_ SG_ 851 UI_falseTouchCounter "Count false touches after display is off.";
CM_ SG_ 851 UI_developmentCar "Touchscreen user interface computer: development car";
CM_ SG_ 851 UI_cameraActive "Touchscreen user interface computer: camera active";
CM_ SG_ 851 UI_cellSignalBars "Number of cellular signal bars displayed on the UI, derived from cellSignalStrength";
CM_ SG_ 851 UI_trailerModeTelltale "Color of the trailer mode telltale";
CM_ SG_ 851 UI_pcbTemperature "PCB digital temp sensor reading in DegC";
CM_ SG_ 851 UI_cpuTemperature "Apollo Lake SOC temperature in DegC";
CM_ BO_ 991 "Touchscreen user interface computer message: status2";
CM_ SG_ 991 UI_mobileAppStepCount "Touchscreen user interface computer: mobile app step count";
CM_ SG_ 991 UI_userRequestSnapshot "Touchscreen user interface computer: user request snapshot";
CM_ SG_ 991 UI_touchDetected "Touchscreen user interface computer: touch detected";
CM_ SG_ 991 UI_validDeviceForEUSummon "Touchscreen user interface computer: valid device for EU summon";
CM_ SG_ 991 UI_locatedAtHome "Touchscreen user interface computer: located at home";
CM_ SG_ 991 UI_locatedAtWork "Touchscreen user interface computer: located at work";
CM_ SG_ 991 UI_locatedAtFavorite "Touchscreen user interface computer: located at favorite";
CM_ SG_ 991 UI_displayInDarkMode "Touchscreen user interface computer: display in dark mode";
CM_ SG_ 991 UI_userActivity "Indicates user interaction with the center display";
CM_ SG_ 991 UI_activeTouchPoints "Quantity of active touch points on the Center Display";
CM_ SG_ 991 UI_linkState "Connectivity link state";
CM_ SG_ 991 UI_sentryModeState "Touchscreen user interface computer: sentry mode state";
CM_ SG_ 991 UI_autopilotSentryRequest "whether AP sentry mode should be enabled";
CM_ SG_ 991 UI_mobileAppConnected "Reports if Web Real-Time Communication (WebRTC) connection is connected while summon screen is open on the mobile app.";
CM_ SG_ 991 UI_phoneLeftInCabin "Used for monitoring phone left behind feature";
CM_ SG_ 991 UI_autoshiftDRState "Reports the User Interface (UI) autoshift Drive/Reverse state.";
CM_ SG_ 991 UI_wifiBtModuleType "Reports the type of Wi-Fi and Bluetooth (BT) module.";
CM_ SG_ 991 UI_sohHealthStatus "Touchscreen user interface computer: soh health status";
CM_ SG_ 991 UI_selfParkState "Reports the auto park state changes.";
CM_ SG_ 991 UI_summonDeviceIndex "Reports which device is being used to control summon.";
CM_ SG_ 991 UI_fullScreenMode "Aggregates all situations with which the UI is using the entire screen so stalkless gear controls are not present";
CM_ SG_ 991 UI_sentryModeCameraDetection "Touchscreen user interface computer: sentry mode camera detection";
CM_ SG_ 991 UI_wakeOnIPActive "Touchscreen user interface computer: wake on IP active";
CM_ SG_ 991 UI_sapActive "Touchscreen user interface computer: sap active";
CM_ SG_ 991 UI_sapClients "Touchscreen user interface computer: sap clients";
CM_ SG_ 991 UI_connectivityStandbyActive "Touchscreen user interface computer: connectivity standby active";
CM_ BO_ 986 "Touchscreen user interface computer message: status3";
CM_ SG_ 986 UI_wifiRegDomain "Indicates the Wi-Fi regulatory domain.";
CM_ SG_ 986 UI_wifiTethered "Monitors whether Wi-Fi is connected while driving.";
CM_ BO_ 988 "Touchscreen user interface computer message: summon goal";
CM_ SG_ 988 UI_goalLatitude "Touchscreen user interface computer: goal latitude";
CM_ SG_ 988 UI_goalLongitude "Touchscreen user interface computer: goal longitude";
CM_ SG_ 988 UI_goalOrientation "Touchscreen user interface computer: goal orientation";
CM_ BO_ 663 "Touchscreen user interface computer message: suspension control";
CM_ SG_ 663 UI_adaptiveRideRequest "UI customer adaptive ride request for air suspension.";
CM_ SG_ 663 UI_suspensionLoweringRequest "Touchscreen user interface computer: suspension lowering request";
CM_ SG_ 663 UI_geofenceLevelingRequest "Geofence level request from customer";
CM_ SG_ 663 UI_jackModeToggleRequest "Touchscreen user interface computer: jack mode toggle request";
CM_ SG_ 663 UI_adaptiveTuningRequest0 "Touchscreen user interface computer: adaptive tuning request0";
CM_ SG_ 663 UI_adaptiveTuningRequest1 "Touchscreen user interface computer: adaptive tuning request1";
CM_ SG_ 663 UI_roadRoughnessLookahead "Touchscreen user interface computer: road roughness lookahead";
CM_ SG_ 663 UI_roadRoughnessStart "Touchscreen user interface computer: road roughness start";
CM_ SG_ 663 UI_mapVersionUsed "Touchscreen user interface computer: map version used";
CM_ SG_ 663 UI_suspensionControlCounter "Touchscreen user interface computer: suspension control counter";
CM_ SG_ 663 UI_suspensionLevelRequest "Touchscreen user interface computer: suspension level request";
CM_ SG_ 663 UI_suspensionControlChecksum "Touchscreen user interface computer: suspension control checksum";
CM_ BO_ 661 "Touchscreen user interface computer message: system monitor";
CM_ SG_ 661 UI_systemMonitorIndex "Touchscreen user interface computer: system monitor index";
CM_ SG_ 661 UI_SystemMemUsage "Monitors system memory usage";
CM_ SG_ 661 UI_QtCarMemUsage "Monitors memory usage of the primary User Interface application";
CM_ SG_ 661 UI_QtCarCPUUsage "Monitors CPU usage of the primary User Interface application";
CM_ SG_ 661 UI_emmcStatus "Touchscreen user interface computer: emmc status";
CM_ SG_ 661 UI_SystemCPUUsage "Monitors system CPU usage";
CM_ SG_ 661 UI_HomeHealth "Touchscreen user interface computer: home health";
CM_ SG_ 661 UI_VarHealth "Touchscreen user interface computer: var health";
CM_ SG_ 661 UI_LogHealth "Touchscreen user interface computer: log health";
CM_ SG_ 661 UI_TmpfsHealth "Touchscreen user interface computer: tmpfs health";
CM_ SG_ 661 UI_emmcDataWritten "Touchscreen user interface computer: emmc data written";
CM_ SG_ 661 UI_emmcTotalErases "Touchscreen user interface computer: emmc total erases";
CM_ BO_ 1064 "Touchscreen user interface computer message: telemetry control";
CM_ SG_ 1064 UI_TCR_enable "Touchscreen user interface computer: TCR enable";
CM_ SG_ 1064 UI_TCR_moveStateStanding "Touchscreen user interface computer: TCR move state standing";
CM_ SG_ 1064 UI_TCR_moveStateStopped "Touchscreen user interface computer: TCR move state stopped";
CM_ SG_ 1064 UI_TCR_moveStateMoving "Touchscreen user interface computer: TCR move state moving";
CM_ SG_ 1064 UI_TCR_moveStateIndeterm "Touchscreen user interface computer: TCR move state indeterm";
CM_ SG_ 1064 UI_TCR_classConstElem "Touchscreen user interface computer: TCR class const elem";
CM_ SG_ 1064 UI_TCR_classMovingPed "Touchscreen user interface computer: TCR class moving ped";
CM_ SG_ 1064 UI_TCR_classMovingTwoWheel "Touchscreen user interface computer: TCR class moving two wheel";
CM_ SG_ 1064 UI_TCR_classMovingFourWheel "Touchscreen user interface computer: TCR class moving four wheel";
CM_ SG_ 1064 UI_TCR_classUnknown "Touchscreen user interface computer: TCR class unknown";
CM_ SG_ 1064 UI_TCR_downSampleFactor "Touchscreen user interface computer: TCR down sample factor";
CM_ SG_ 1064 UI_TCR_wExist "Touchscreen user interface computer: TCR w exist";
CM_ SG_ 1064 UI_TCR_vehSpeed "Touchscreen user interface computer: TCR veh speed";
CM_ SG_ 1064 UI_TCR_minRCS "Touchscreen user interface computer: TCR min RCS";
CM_ SG_ 1064 UI_TCR_maxDy "Touchscreen user interface computer: TCR max dy";
CM_ SG_ 1064 UI_TCR_maxObjects "Touchscreen user interface computer: TCR max objects";
CM_ SG_ 1064 UI_TCR_maxRoadClass "Touchscreen user interface computer: TCR max road class";
CM_ BO_ 856 "Touchscreen user interface computer message: tpms mode";
CM_ SG_ 856 UI_TPMSMode "Touchscreen user interface computer: TPMS mode";
CM_ SG_ 856 UI_TPMSLearnIDMode "Touchscreen user interface computer: TPMS learn ID mode";
CM_ SG_ 856 UI_sizeOfWheelSelect "Touchscreen user interface computer: size of wheel select";
CM_ SG_ 856 UI_sizeOfReqCANAutoLearn "Touchscreen user interface computer: size of req CAN auto learn";
CM_ BO_ 952 "Touchscreen user interface computer message: tpms RC psetting";
CM_ SG_ 952 UI_sendCalibrateTireRequest "Reports UI requests for PMDI to start the tire pressure calibration routine.";
CM_ SG_ 952 UI_setRCPFront "Touchscreen user interface computer: set RCP front";
CM_ SG_ 952 UI_setRCPRear "Touchscreen user interface computer: set RCP rear";
CM_ BO_ 787 "Touchscreen user interface computer message: track mode settings";
CM_ SG_ 787 UI_trackModeRequest "User selected track mode";
CM_ SG_ 787 UI_trackRotationTendency "Touchscreen user interface computer: track rotation tendency";
CM_ SG_ 787 UI_trackStabilityAssist "Touchscreen user interface computer: track stability assist";
CM_ SG_ 787 UI_trackPostCooling "Touchscreen user interface computer: track post cooling";
CM_ SG_ 787 UI_trackCmpOverclock "Touchscreen user interface computer: track cmp overclock";
CM_ SG_ 787 UI_trackModeBrakeTemps "Touchscreen user interface computer: track mode brake temps";
CM_ SG_ 787 UI_trackDrivePowerAvailability "Reports power deployment strategy for Track Mode. Ranges from endurance limit to maximum power.";
CM_ SG_ 787 UI_stabilityModeRequest "Touchscreen user interface computer: stability mode request";
CM_ SG_ 787 UI_trackModeSettingsCounter "Touchscreen user interface computer: track mode settings counter";
CM_ SG_ 787 UI_trackModeSettingsChecksum "Touchscreen user interface computer: track mode settings checksum";
CM_ BO_ 1263 "Touchscreen user interface computer message: trip planner info";
CM_ SG_ 1263 UI_fwHeatOnNavArrivalSOE "Energy percentages shown in the UI";
CM_ SG_ 1263 UI_voyagerHeatOnNavArrivalSOE "Energy percentages shown in the UI";
CM_ SG_ 1263 UI_usingVoyagerPreconditioning "Touchscreen user interface computer: using voyager preconditioning";
CM_ BO_ 130 "Touchscreen user interface computer message: trip planning";
CM_ SG_ 130 UI_tripPlanningActive "Indicates that there is active route in navigation with a valid energy at destination prediction.";
CM_ SG_ 130 UI_navToSupercharger "Navigation destination is a supercharger";
CM_ SG_ 130 UI_navFastchargerType "when navigation is turned on, this enum identifies the type of fastcharger the car is navigating to based on the rated power from sc_locations";
CM_ SG_ 130 UI_battPreconditionOnNavState "Indicates to battery and thermal systems whether the battery should be actively heated, passively heated, actively cooled, or passively cooled";
CM_ SG_ 130 UI_requestActiveBatteryHeating "Flag to request BMS enable active battery heating";
CM_ SG_ 130 UI_battPreconditionOnNavPowerReq "The preconditioning power that Trip Planner is requesting from the thermal system to use for battery preconditioning (cooling or heating).";
CM_ SG_ 130 UI_battPreconditionOnNavTargetT "The pack temperature that Trip Planner is targeting upon arriving to a fast charger.";
CM_ SG_ 130 UI_ambientTempAtDestination "Touchscreen user interface computer: ambient temp at destination";
CM_ SG_ 130 UI_tripPlanChargingTargetPercent "Touchscreen user interface computer: trip plan charging target percent";
CM_ SG_ 130 UI_energyAtDestination "expected energy at destination in kWh for current navigation route";
CM_ BO_ 139 "Touchscreen user interface computer message: trip planning2";
CM_ SG_ 139 UI_maxSpeedToReachDestination "maximum speed to reach destination without significant risk of running out of energy";
CM_ SG_ 139 UI_remainingWeightedRMSSpeed "Touchscreen user interface computer: remaining weighted RMS speed";
CM_ SG_ 139 UI_timeToDestination "remaining time to reach destination";
CM_ BO_ 1173 "Touchscreen user interface computer message: trip planning3";
CM_ SG_ 1173 UI_predictedEnergy "initially predicted energy in kWh for current location along navigation route";
CM_ SG_ 1173 UI_predictedEnergyLearned "Touchscreen user interface computer: predicted energy learned";
CM_ SG_ 1173 UI_hindsightEnergy "hindsight energy, the model predicted energy based on measured speed and acceleration for the current location along navigation route";
CM_ SG_ 1173 UI_hindsightEnergyLearned "Touchscreen user interface computer: hindsight energy learned";
CM_ BO_ 1174 "Touchscreen user interface computer message: trip planning4";
CM_ SG_ 1174 UI_longTermEnergyModelError "Touchscreen user interface computer: long term energy model error";
CM_ SG_ 1174 UI_longTermRmsSpeedRatio "Touchscreen user interface computer: long term rms speed ratio";
CM_ SG_ 1174 UI_gradeCorrectedEnergy "Touchscreen user interface computer: grade corrected energy";
CM_ SG_ 1174 UI_gradeCorrectedEnergyLearned "Touchscreen user interface computer: grade corrected energy learned";
CM_ BO_ 1175 "Touchscreen user interface computer message: trip planning5";
CM_ SG_ 1175 UI_battPreconditionOnNavTime "Touchscreen user interface computer: batt precondition on nav time";
CM_ SG_ 1175 UI_maxBattPreconditionOnNavTime "Touchscreen user interface computer: max batt precondition on nav time";
CM_ BO_ 850 "Touchscreen user interface computer message: ui health status";
CM_ SG_ 850 UI_centerDisplayRunning "is center display running";
CM_ SG_ 850 UI_centerDisplaySM "Touchscreen user interface computer: center display SM";
CM_ SG_ 850 UI_centerDisplayPowerOn "center display power on";
CM_ SG_ 850 UI_centerDisplayCrtcOk "Touchscreen user interface computer: center display crtc ok";
CM_ SG_ 850 UI_centerDisplayHardwareOk "Touchscreen user interface computer: center display hardware ok";
CM_ SG_ 850 UI_centerDisplayWindowManagerOk "Touchscreen user interface computer: center display window manager ok";
CM_ SG_ 850 UI_centerDisplayCompositorOk "Touchscreen user interface computer: center display compositor ok";
CM_ SG_ 850 UI_apVisualizationOk "Touchscreen user interface computer: ap visualization ok";
CM_ SG_ 850 UI_autonomyCenterDispStatus "Touchscreen user interface computer: autonomy center disp status";
CM_ SG_ 850 UI_autonomyRearDispStatus "Touchscreen user interface computer: autonomy rear disp status";
CM_ SG_ 850 UI_autonomyConnectivityStatus "Touchscreen user interface computer: autonomy connectivity status";
CM_ SG_ 850 UI_autonomyConnectivtyHWOk "Touchscreen user interface computer: autonomy connectivty HW ok";
CM_ SG_ 850 UI_autonomyQtCarStatus "Signal reported by Touchscreen user interface computer";
CM_ SG_ 850 UI_autonomyQtCarRearStatus "Signal reported by Touchscreen user interface computer";
CM_ SG_ 850 UI_autonomyDASServerStatus "Touchscreen user interface computer: autonomy DAS server status";
CM_ SG_ 850 UI_rearDisplayRunning "is rear display running";
CM_ SG_ 850 UI_rearDisplayPowerOn "rear display power on";
CM_ SG_ 850 UI_rearDisplaySM "Touchscreen user interface computer: rear display SM";
CM_ SG_ 850 UI_rearDisplayCrtcOk "Touchscreen user interface computer: rear display crtc ok";
CM_ SG_ 850 UI_rearDisplayHardwareOk "Touchscreen user interface computer: rear display hardware ok";
CM_ SG_ 850 UI_rearDisplayWindowManagerOk "Touchscreen user interface computer: rear display window manager ok";
CM_ SG_ 850 UI_rearDisplayCompositorOk "Touchscreen user interface computer: rear display compositor ok";
CM_ BO_ 1827 "Touchscreen user interface computer message: uss thresholds x";
CM_ SG_ 1827 UI_ussSensorIdX "Touchscreen user interface computer: uss sensor id x";
CM_ SG_ 1827 UI_ussThresholdX0 "Touchscreen user interface computer: uss threshold X0";
CM_ SG_ 1827 UI_ussThresholdX1 "Touchscreen user interface computer: uss threshold X1";
CM_ SG_ 1827 UI_ussThresholdX2 "Touchscreen user interface computer: uss threshold X2";
CM_ SG_ 1827 UI_ussThresholdX3 "Touchscreen user interface computer: uss threshold X3";
CM_ SG_ 1827 UI_ussThresholdX4 "Touchscreen user interface computer: uss threshold X4";
CM_ SG_ 1827 UI_ussThresholdX5 "Touchscreen user interface computer: uss threshold X5";
CM_ SG_ 1827 UI_ussThresholdX6 "Touchscreen user interface computer: uss threshold X6";
CM_ SG_ 1827 UI_ussThresholdX7 "Touchscreen user interface computer: uss threshold X7";
CM_ SG_ 1827 UI_ussThresholdX8 "Touchscreen user interface computer: uss threshold X8";
CM_ SG_ 1827 UI_ussThresholdX9 "Touchscreen user interface computer: uss threshold X9";
CM_ SG_ 1827 UI_ussThresholdX10 "Touchscreen user interface computer: uss threshold X10";
CM_ SG_ 1827 UI_ussThresholdX11 "Touchscreen user interface computer: uss threshold X11";
CM_ SG_ 1827 UI_ussThresholdXControl "Touchscreen user interface computer: uss threshold x control";
CM_ BO_ 1829 "Touchscreen user interface computer message: uss thresholds y";
CM_ SG_ 1829 UI_ussSensorIdY "Touchscreen user interface computer: uss sensor id y";
CM_ SG_ 1829 UI_ussThresholdY0 "Touchscreen user interface computer: uss threshold Y0";
CM_ SG_ 1829 UI_ussThresholdY1 "Touchscreen user interface computer: uss threshold Y1";
CM_ SG_ 1829 UI_ussThresholdY2 "Touchscreen user interface computer: uss threshold Y2";
CM_ SG_ 1829 UI_ussThresholdY3 "Touchscreen user interface computer: uss threshold Y3";
CM_ SG_ 1829 UI_ussThresholdY4 "Touchscreen user interface computer: uss threshold Y4";
CM_ SG_ 1829 UI_ussThresholdY5 "Touchscreen user interface computer: uss threshold Y5";
CM_ SG_ 1829 UI_ussThresholdY6 "Touchscreen user interface computer: uss threshold Y6";
CM_ SG_ 1829 UI_ussThresholdY7 "Touchscreen user interface computer: uss threshold Y7";
CM_ SG_ 1829 UI_ussThresholdY8 "Touchscreen user interface computer: uss threshold Y8";
CM_ SG_ 1829 UI_ussThresholdY9 "Touchscreen user interface computer: uss threshold Y9";
CM_ SG_ 1829 UI_ussThresholdY10 "Touchscreen user interface computer: uss threshold Y10";
CM_ SG_ 1829 UI_ussThresholdY11 "Touchscreen user interface computer: uss threshold Y11";
CM_ SG_ 1829 UI_ussThresholdYControl "Touchscreen user interface computer: uss threshold y control";
CM_ BO_ 627 "Touchscreen user interface computer message: vehicle control";
CM_ SG_ 627 UI_powerStateRequest "Request accessory power";
CM_ SG_ 627 UI_childDoorLockOnRight "UI child door lock request status.";
CM_ SG_ 627 UI_frontFogSwitch "Request for front fog lights to be on";
CM_ SG_ 627 UI_summonActive "Summon is active";
CM_ SG_ 627 UI_frunkRequest "Request open frunk";
CM_ SG_ 627 UI_wiperMode "Wiper mode state";
CM_ SG_ 627 UI_steeringBacklightEnabled "Touchscreen user interface computer: steering backlight enabled";
CM_ SG_ 627 UI_steeringButtonMode "Steering wheel control mode";
CM_ SG_ 627 UI_walkUpUnlock "Walk up unlock request (datavalue defaults to false)";
CM_ SG_ 627 UI_walkAwayLock "Walk away door lock setting.";
CM_ SG_ 627 UI_unlockOnPark "Unlock on park setting";
CM_ SG_ 627 UI_globalUnlockOn "Global Unlock Setting";
CM_ SG_ 627 UI_childDoorLockOnLeft "UI child door lock request status.";
CM_ SG_ 627 UI_lockRequest "Lock or unlock request";
CM_ SG_ 627 UI_alarmEnabled "UI customer level request to enable alarm.";
CM_ SG_ 627 UI_intrusionSensorOn "Touchscreen user interface computer: intrusion sensor on";
CM_ SG_ 627 UI_stop12vSupport "UI request to stop rails as 12v support";
CM_ SG_ 627 UI_rearFogSwitch "Request for rear fog lights to be on";
CM_ SG_ 627 UI_mirrorFoldRequest "Fold the mirrors";
CM_ SG_ 627 UI_mirrorHeatRequest "Customer usage of mirror heater and rear defrost";
CM_ SG_ 627 UI_remoteStartRequest "remote start or self park request";
CM_ SG_ 627 UI_seeYouHomeLightingOn "Headlights after exit";
CM_ SG_ 627 UI_powerOff "power off rails request.";
CM_ SG_ 627 UI_displayBrightnessLevel "UI brightness";
CM_ SG_ 627 UI_ambientLightingEnabled "Touchscreen user interface computer: ambient lighting enabled";
CM_ SG_ 627 UI_autoHighBeamEnabled "Enable Automatic High/Low Beams";
CM_ SG_ 627 UI_frontLeftSeatHeatReq "Request for front left seat heat";
CM_ SG_ 627 UI_frontRightSeatHeatReq "Request for front left seat heat";
CM_ SG_ 627 UI_rearLeftSeatHeatReq "UI request for second row left seat heater";
CM_ SG_ 627 UI_rearCenterSeatHeatReq "UI request for second row middle seat heater";
CM_ SG_ 627 UI_rearRightSeatHeatReq "UI request for second row right seat heater";
CM_ SG_ 627 UI_autoFoldMirrorsOn "Enable Automatic Mirror Fold/Unfold";
CM_ SG_ 627 UI_mirrorDipOnReverse "Enable Mirror Dip On Reverse";
CM_ SG_ 627 UI_remoteClosureRequest "remote actuate trunk";
CM_ SG_ 627 UI_wiperRequest "Wiper speed";
CM_ SG_ 627 UI_domeLightSwitch "Dome light switch";
CM_ SG_ 627 UI_honkHorn "Touchscreen user interface computer: honk horn";
CM_ SG_ 627 UI_driveStateRequest "Touchscreen user interface computer: drive state request";
CM_ SG_ 627 UI_rearWindowLockout "Touchscreen user interface computer: rear window lockout";
CM_ BO_ 947 "Touchscreen user interface computer message: vehicle control2";
CM_ SG_ 947 UI_gloveboxRequest "UI request to open the glovebox";
CM_ SG_ 947 UI_trunkRequest "Rear trunk request";
CM_ SG_ 947 UI_UMCUpdateInhibit "Touchscreen user interface computer: UMC update inhibit";
CM_ SG_ 947 UI_WCUpdateInhibit "Touchscreen user interface computer: WC update inhibit";
CM_ SG_ 947 UI_soundHornOnLock "Touchscreen user interface computer: sound horn on lock";
CM_ SG_ 947 UI_locksPanelActive "Touchscreen user interface computer: locks panel active";
CM_ SG_ 947 UI_PINToDriveEnabled "UI customer level request to pin to drive enabled.";
CM_ SG_ 947 UI_PINToDrivePassed "UI customer level request to enable drive with pin passed.";
CM_ SG_ 947 UI_disableMirrorAutoDim "Request to disable side and rear-view mirror auto dim";
CM_ SG_ 947 UI_lightSwitch "Headlight mode";
CM_ SG_ 947 UI_readyToAddKey "Ready to add key";
CM_ SG_ 947 UI_alarmTriggerRequest "Alarm activation request from UI";
CM_ SG_ 947 UI_VCSECFeature1 "Touchscreen user interface computer: VCSEC feature1";
CM_ SG_ 947 UI_VCLEFTFeature1 "Touchscreen user interface computer: VCLEFT feature1";
CM_ SG_ 947 UI_summonState "Touchscreen user interface computer: summon state";
CM_ SG_ 947 UI_displayOnForUser "User is present";
CM_ SG_ 947 UI_freeRollModeRequest "Touchscreen user interface computer: free roll mode request";
CM_ SG_ 947 UI_BLEPushNotificationRequest "Reports that the User Interface (UI) wants to talk to a phone and Vehicle Controller Security (VCSEC) should let all connected phones know.";
CM_ SG_ 947 UI_pairKeyQRCodeDisplaying "Touchscreen user interface computer: pair key QR code displaying";
CM_ SG_ 947 UI_keepAutopilotAwake "Reports the request for Vehicle Controller (VC) to keep autopilot awake.";
CM_ SG_ 947 UI_batteryPreconditioningRequest "Requests battery preconditioning.";
CM_ SG_ 947 UI_coastDownMode "Touchscreen user interface computer: coast down mode";
CM_ SG_ 947 UI_autopilotPowerStateRequest "Requests different power states from autopilot ECU depending on feature usage.";
CM_ SG_ 947 UI_shorted12VCellTestMode "Touchscreen user interface computer: shorted12 v cell test mode";
CM_ SG_ 947 UI_autoRollWindowsOnLockEnable "UI customer level request to enable auto-roll windows on lock";
CM_ SG_ 947 UI_virtualPitchSensorOverrideOKF "Touchscreen user interface computer: virtual pitch sensor override OK for aim";
CM_ SG_ 947 UI_conditionalLoggingEnabledVCSE "Touchscreen user interface computer: conditional logging enabled VCSEC";
CM_ SG_ 947 UI_WC3UpdateInhibit "Touchscreen user interface computer: WC3 update inhibit";
CM_ SG_ 947 UI_steeringWheelHeatReq "Request to enable steering wheel heater";
CM_ SG_ 947 UI_disableHorn "Request to disable horn";
CM_ SG_ 947 UI_frontLeftSeatFanReq "Request for front left seat ventilation";
CM_ SG_ 947 UI_frontRightSeatAutoClimateReq "UI setting to enable auto seat heating and cooling for front right seat";
CM_ SG_ 947 UI_frontRightSeatFanReq "Request for front left seat ventilation";
CM_ SG_ 947 UI_3RLeftSeatHeatReq "UI request for third row left seat heater";
CM_ SG_ 947 UI_3RRightSeatHeatReq "UI request for third row right seat heater";
CM_ SG_ 947 UI_sleepFeature1 "Touchscreen user interface computer: sleep feature1";
CM_ SG_ 947 UI_dcr12VThreshold "Touchscreen user interface computer: dcr12 v threshold";
CM_ SG_ 947 UI_frontLeftSeatAutoClimateReq "UI setting to enable auto seat heating and cooling for front left seat";
CM_ SG_ 947 UI_wiperHeaterReq "UI request to enable the wiper heater";
CM_ SG_ 947 UI_tireSeason "Touchscreen user interface computer: tire season";
CM_ SG_ 947 UI_saveTireConfigReq "Touchscreen user interface computer: save tire config req";
CM_ SG_ 947 UI_silentAlarm "Signal indicating alarms should be silenced";
CM_ SG_ 947 UI_sleepFeature2 "Touchscreen user interface computer: sleep feature2";
CM_ BO_ 628 "Touchscreen user interface computer message: vehicle control3";
CM_ SG_ 628 UI_lightFlashRequest "UI flash lights request";
CM_ SG_ 628 UI_keylessDrivingEnabled "Touchscreen user interface computer: keyless driving enabled";
CM_ SG_ 628 UI_phoneCallActive "On phone call via Bluetooth if active";
CM_ SG_ 628 UI_drivingSideVEH "Touchscreen user interface computer: driving side VEH";
CM_ SG_ 628 UI_keyPairResponse "Touchscreen user interface computer: key pair response";
CM_ SG_ 628 UI_lightShowClosuresEnabled "Closure movements enabled during light show";
CM_ SG_ 628 UI_steeringWheelHeatAutoReq "UI setting to request auto steering wheel heat";
CM_ SG_ 628 UI_steeringWheelHeatLevelReq "Request for steering wheel heat";
CM_ SG_ 628 UI_headlightPulseRequest "Request headlights to pulse";
CM_ SG_ 628 UI_VCSECFeature2 "Touchscreen user interface computer: VCSEC feature2";
CM_ SG_ 628 UI_VCSECFeature3 "Touchscreen user interface computer: VCSEC feature3";
CM_ SG_ 628 UI_VCSECFeature4 "Touchscreen user interface computer: VCSEC feature4";
CM_ SG_ 628 UI_VCSECFeature5 "Touchscreen user interface computer: VCSEC feature5";
CM_ SG_ 628 UI_shortHornRequest "Touchscreen user interface computer: short horn request";
CM_ SG_ 628 UI_packTempLoggingRequest "Touchscreen user interface computer: pack temp logging request";
CM_ SG_ 628 UI_UMC3UpdateInhibit "Touchscreen user interface computer: UMC3 update inhibit";
CM_ SG_ 628 UI_handsFreeTrunk "Touchscreen user interface computer: hands free trunk";
CM_ SG_ 628 UI_displayRedShiftActive "UI's reduce blue light setting is active";
CM_ SG_ 628 UI_handsFreeFrunk "Touchscreen user interface computer: hands free frunk";
CM_ SG_ 628 UI_fasciaCameraWashRequest "User request to activate fascia camera wash";
CM_ SG_ 628 UI_autoClosuresExcludeHome "Touchscreen user interface computer: auto closures exclude home";
CM_ SG_ 628 UI_leftRearSeatAdjustmentRequest "Reports request from UI to actuate the left rear seat";
CM_ SG_ 628 UI_rightRearSeatAdjustmentReques "Reports request from UI to actuate the right rear seat";
CM_ SG_ 628 UI_blindSpotIndicatorLightReques "Request for blind spot indicator light";
CM_ SG_ 628 UI_etcBluetoothControl "Touchscreen user interface computer: etc bluetooth control";
CM_ SG_ 628 UI_keepOnAccessoryPortsReq "User setting to keep 12V outlets, USB ports, and phone chargers powered in CONDITIONING";
CM_ SG_ 628 UI_fasciaCameraShown "Whether the UI is currently showing the fascia camera view";
CM_ SG_ 628 UI_rearSeatChildLock "Reports the state of second row seat fold flat child lock from the UI";
CM_ SG_ 628 UI_windowPercentageRequest "Reports the window percentage value when window request is WINDOW_REQUEST_GOTO_PERCENT.";
CM_ SG_ 628 UI_windowRequestedFL "Reports that the front left window is requested.";
CM_ SG_ 628 UI_windowRequestedFR "Reports that the front right window is requested.";
CM_ SG_ 628 UI_windowRequestedRL "Reports that the rear left window is requested.";
CM_ SG_ 628 UI_windowRequestedRR "Reports that the rear right window is requested.";
CM_ SG_ 628 UI_windowRequest "Window operation request from the mobile app.";
CM_ SG_ 628 UI_closeTrunkRequest "Explicity request for the rear trunk to close";
CM_ SG_ 628 UI_childPresenceDetectionDisable "User request to disable child presence detection behaviors until the next drive cycle";
CM_ SG_ 628 UI_V2LAUpdateInhibit "Touchscreen user interface computer: V2 LA update inhibit";
CM_ SG_ 628 UI_userPresenceDetectionEnabled "Touchscreen user interface computer: user presence detection enabled";
CM_ SG_ 628 UI_derivedLoadshedFeature "Reports whether vehicle controllers should enable derived loadshed feature.";
CM_ SG_ 628 UI_rearSeatFoldConfirmed "Touchscreen user interface computer: rear seat fold confirmed";
CM_ SG_ 628 UI_leftRearSeatRequestFromRearDi "Touchscreen user interface computer: left rear seat request from rear display";
CM_ SG_ 628 UI_selfParkStandingBy "Reports that summon is in standby.";
CM_ SG_ 628 UI_rightRearSeatRequestFromRearD "Touchscreen user interface computer: right rear seat request from rear display";
CM_ BO_ 1193 "Touchscreen user interface computer message: vehicle control4";
CM_ SG_ 1193 UI_firstRowLeftDomeLightRequest "Monitors the dome light switch for first row left side";
CM_ SG_ 1193 UI_firstRowRightDomeLightRequest "Monitors the dome light switch for first row right side";
CM_ SG_ 1193 UI_secondRowLeftDomeLightRequest "Monitors the dome light switch for second row left side";
CM_ SG_ 1193 UI_secondRowCenterDomeLightReque "Monitors the dome light switch for second row center side";
CM_ SG_ 1193 UI_secondRowRightDomeLightReques "Monitors the dome light switch for second row right side";
CM_ SG_ 1193 UI_thirdRowLeftDomeLightRequest "Monitors the dome light switch for third row left side";
CM_ SG_ 1193 UI_thirdRowRightDomeLightRequest "Monitors the dome light switch for third row right side";
CM_ BO_ 853 "Touchscreen user interface computer message: vehicle control thermal";
CM_ SG_ 853 UI_coolantFlowRequest "request for coolant flow to MCU in LPM";
CM_ SG_ 853 UI_inletActiveCoolTarget "request for coolant temperature at Car Computer inlet";
CM_ SG_ 853 UI_disableHVPTThermalLoads "Request thermal system to disable active battery heating";
CM_ SG_ 853 UI_enableCompLiquidPumpOut "Touchscreen user interface computer: enable comp liquid pump out";
CM_ SG_ 853 UI_enableCOP1HighSHOperation "Touchscreen user interface computer: enable COP1 high SH operation";
CM_ SG_ 853 UI_enableIncreasedEvapRampRate "Touchscreen user interface computer: enable increased evap ramp rate";
CM_ SG_ 853 UI_enableCOP1BatteryHeating "Touchscreen user interface computer: enable COP1 battery heating";
CM_ SG_ 853 UI_enableCOP1CabinHeatingBattery "Touchscreen user interface computer: enable COP1 cabin heating battery heating";
CM_ SG_ 853 UI_enableLouverAutoDetection "Touchscreen user interface computer: enable louver auto detection";
CM_ SG_ 853 UI_enableUserFacingLowFlowDelive "Touchscreen user interface computer: enable user facing low flow delivery alert";
CM_ SG_ 853 UI_disableHvacCameraOnlyDefog "Touchscreen user interface computer: disable hvac camera only defog";
CM_ SG_ 853 UI_enableEXVFastCalibration "Touchscreen user interface computer: enable EXV fast calibration";
CM_ SG_ 853 UI_enableThermalDriverlessSelfTe "Touchscreen user interface computer: enable thermal driverless self test";
CM_ SG_ 853 UI_enableCoolantDasTarget "Touchscreen user interface computer: enable coolant das target";
CM_ SG_ 853 UI_geofencedLiftgateHeight "Touchscreen user interface computer: geofenced liftgate height";
CM_ SG_ 853 UI_convenienceFeatureLimit "UI limit request in SOE (UI Gauge) for convenience features";
CM_ SG_ 853 UI_allowConvenienceFeatures "Whether UI allows convenenience features";
CM_ SG_ 853 UI_enableConservativeBatteryHeat "Touchscreen user interface computer: enable conservative battery heating";
CM_ SG_ 853 UI_enableDefaultApTempTarget "Touchscreen user interface computer: enable default ap temp target";
CM_ SG_ 853 UI_enableHVACCompressorWasteHeat "Touchscreen user interface computer: enable HVAC compressor waste heat";
CM_ SG_ 853 UI_disablePhoneChargingPads "Reports requests from the User Interface (UI) to disable wireless phone charging.";
CM_ SG_ 853 UI_isAtTeslaFacility "Touchscreen user interface computer: is at tesla facility";
CM_ SG_ 853 UI_enableThermalPowerBudget "Touchscreen user interface computer: enable thermal power budget";
CM_ SG_ 853 UI_enableHVACAPFanHeaterControl "Touchscreen user interface computer: enable HVACAP fan heater control";
CM_ SG_ 853 UI_enableAutopilotAirPurge "Touchscreen user interface computer: enable autopilot air purge";
CM_ SG_ 853 UI_enableForcedAirCameraHeater "Touchscreen user interface computer: enable forced air camera heater";
CM_ SG_ 853 UI_enableHvacCOPOnUndeliveredVeh "Touchscreen user interface computer: enable hvac COP on undelivered veh";
CM_ BO_ 644 "Touchscreen user interface computer message: vehicle modes";
CM_ SG_ 644 UI_factoryMode "Touchscreen user interface computer: factory mode";
CM_ SG_ 644 UI_transportMode "Reports UI Transport mode. Distinct from GTW transport mode.";
CM_ SG_ 644 UI_showroomMode "Reports UI showroom mode.";
CM_ SG_ 644 UI_serviceMode "Signal reported by Touchscreen user interface computer";
CM_ SG_ 644 UI_isDelivered "Touchscreen user interface computer: is delivered";
CM_ SG_ 644 UI_hasEverBeenDelivered "Touchscreen user interface computer: has ever been delivered";
CM_ SG_ 644 UI_homelinkV2Command0 "Touchscreen user interface computer: homelink V2 command0";
CM_ SG_ 644 UI_homelinkV2Command1 "Touchscreen user interface computer: homelink V2 command1";
CM_ SG_ 644 UI_homelinkV2Command2 "Touchscreen user interface computer: homelink V2 command2";
CM_ SG_ 644 UI_carWashMode "Car Wash Mode";
CM_ SG_ 644 UI_valetMode "Touchscreen user interface computer: valet mode";
CM_ SG_ 644 UI_gameMode "Game mode";
CM_ SG_ 644 UI_diagnosticsAllowed "Touchscreen user interface computer: diagnostics allowed";
CM_ SG_ 644 UI_serviceModePlus "Signal reported by Touchscreen user interface computer";
CM_ SG_ 644 UI_premiumAmpPowerOff "Premium amplifier power off request";
CM_ SG_ 644 UI_signedCmdHardLocked "Touchscreen user interface computer: signed cmd hard locked";
CM_ SG_ 644 UI_signedCmdServiceMode "Signal reported by Touchscreen user interface computer";
CM_ SG_ 644 UI_closureEasterEggStatus "Touchscreen user interface computer: closure easter egg status";
CM_ SG_ 644 UI_lightShowType "Type of the light show to be run";
CM_ SG_ 644 UI_sohTestRequest "Touchscreen user interface computer: soh test request";
CM_ SG_ 644 UI_upkeepMode "Reports UI Upkeep Mode state.";
CM_ SG_ 644 UI_vehicleModesCounter "Touchscreen user interface computer: vehicle modes counter";
CM_ SG_ 644 UI_vehicleModesChecksum "Touchscreen user interface computer: vehicle modes checksum";
CM_ BO_ 595 "Touchscreen user interface computer message: vent panel control request";
CM_ SG_ 595 UI_ventPanelControlRequestIndex "Touchscreen user interface computer: vent panel control request index";
CM_ SG_ 595 UI_ventPanelLeftPositionX "Airwave left X position.";
CM_ SG_ 595 UI_ventPanelLeftPositionY "Airwave left Y position.";
CM_ SG_ 595 UI_ventPanelLeftLateralSplit "Airwave left split amount.";
CM_ SG_ 595 UI_ventPanelRightPositionX "Airwave right X position.";
CM_ SG_ 595 UI_ventPanelRightPositionY "Airwave right Y position.";
CM_ SG_ 595 UI_ventPanelRightLateralSplit "Airwave right split amount.";
CM_ SG_ 595 UI_ventPanelLeftLateralMode "Airwave left focus or split.";
CM_ SG_ 595 UI_ventPanelRightLateralMode "Airwave right focus or split.";
CM_ SG_ 595 UI_hvacReqActiveVents "Active airwave sides - left/right/both";
CM_ SG_ 595 UI_vent2RLeftPositionX "Airwave left X position.";
CM_ SG_ 595 UI_vent2RLeftPositionY "Airwave left Y position.";
CM_ SG_ 595 UI_vent2RRightPositionX "Airwave left X position.";
CM_ SG_ 595 UI_vent2RRightPositionY "Airwave left Y position.";
CM_ SG_ 595 UI_hvacReqThirdRowState "Detects HVAC third row fan speed request.";
CM_ BO_ 1569 "Touchscreen user interface computer message: weather data service";
CM_ SG_ 1569 UI_weatherSvcTimeSinceLast "Touchscreen user interface computer: weather svc time since last";
CM_ SG_ 1569 UI_weatherSvcWindDir "Touchscreen user interface computer: weather svc wind dir";
CM_ SG_ 1569 UI_weatherSvcTemperature "Touchscreen user interface computer: weather svc temperature";
CM_ SG_ 1569 UI_weatherSvcHumidity "Touchscreen user interface computer: weather svc humidity";
CM_ SG_ 1569 UI_weatherSvcDewPoint "Touchscreen user interface computer: weather svc dew point";
CM_ SG_ 1569 UI_weatherSvcCloudCover "Touchscreen user interface computer: weather svc cloud cover";
CM_ SG_ 1569 UI_weatherSvcPrecipProb "Touchscreen user interface computer: weather svc precip prob";
CM_ SG_ 1569 UI_weatherSvcRaining "Touchscreen user interface computer: weather svc raining";
CM_ SG_ 1569 UI_weatherSvcSnowing "Touchscreen user interface computer: weather svc snowing";
CM_ SG_ 1569 UI_weatherSvcWindSpeed "Touchscreen user interface computer: weather svc wind speed";
BA_DEF_ BO_ "GenMsgCycleTime" INT 0 3600000;
BA_DEF_ BO_ "GenMsgSendType" ENUM "Cyclic","NotUsed","NotUsed","NotUsed","NotUsed","NotUsed","NotUsed","IfActive","NoMsgSendType","NotUsed";
BA_DEF_ BO_ "VFrameFormat" ENUM "StandardCAN","ExtendedCAN","reserved","J1939PG","reserved","reserved","reserved","reserved","reserved","reserved","reserved","reserved","reserved","reserved","StandardCAN_FD","ExtendedCAN_FD";
BA_DEF_ BO_ "CANFD_BRS" ENUM "0","1";
BA_DEF_ SG_ "SystemSignalLongSymbol" STRING;
BA_DEF_ SG_ "Confidence" ENUM "layout-only","plausible","validated";
BA_DEF_DEF_ "GenMsgCycleTime" 0;
BA_DEF_DEF_ "GenMsgSendType" "NoMsgSendType";
BA_DEF_DEF_ "VFrameFormat" "StandardCAN";
BA_DEF_DEF_ "CANFD_BRS" "1";
BA_DEF_DEF_ "SystemSignalLongSymbol" "";
BA_DEF_DEF_ "Confidence" "layout-only";
BA_ "Confidence" SG_ 659 UI_steeringTuneRequest 1;
BA_ "Confidence" SG_ 659 UI_tractionControlMode 1;
BA_ "Confidence" SG_ 659 UI_parkBrakeRequest 1;
BA_ "Confidence" SG_ 659 UI_winchModeRequest 1;
BA_ "Confidence" SG_ 659 UI_trailerMode 1;
BA_ "Confidence" SG_ 659 UI_accOvertakeEnable 1;
BA_ "Confidence" SG_ 659 UI_aebEnable 1;
BA_ "Confidence" SG_ 659 UI_aesEnable 1;
BA_ "Confidence" SG_ 659 UI_ahlbEnable 1;
BA_ "Confidence" SG_ 659 UI_autoLaneChangeEnable 1;
BA_ "Confidence" SG_ 659 UI_winchProxUserOverride 1;
BA_ "Confidence" SG_ 659 UI_autoParkRequest 1;
BA_ "Confidence" SG_ 659 UI_bsdEnable 1;
BA_ "Confidence" SG_ 659 UI_fcwEnable 1;
BA_ "Confidence" SG_ 659 UI_fcwSensitivity 1;
BA_ "Confidence" SG_ 659 UI_latControlEnable 1;
BA_ "Confidence" SG_ 659 UI_ldwEnable 1;
BA_ "Confidence" SG_ 531 UI_cruiseSpeedCommand 1;
BA_ "Confidence" SG_ 531 UI_autonomySummonRequest 1;
BA_ "Confidence" SG_ 1016 UI_ulcStalkConfirm 1;
BA_ "Confidence" SG_ 1016 UI_lssLkaEnabled 1;
BA_ "Confidence" SG_ 1016 UI_lssLdwEnabled 1;
BA_ "Confidence" SG_ 1016 UI_driveOnMapsEnable 1;
BA_ "Confidence" SG_ 1016 UI_lssElkEnabled 1;
BA_ "Confidence" SG_ 1016 UI_selfParkRequest 1;
BA_ "Confidence" SG_ 1016 UI_followNavRouteEnable 1;
BA_ "Confidence" SG_ 1016 UI_ulcSpeedConfig 1;
BA_ "Confidence" SG_ 1016 UI_suppressExitPassingLane 1;
BA_ "Confidence" SG_ 1016 UI_smartSummonType 1;
BA_ "Confidence" SG_ 1016 UI_isaSpeedingChimeMuted 1;
BA_ "Confidence" SG_ 568 UI_roadClass 1;
BA_ "Confidence" SG_ 568 UI_navRouteActive 1;
BA_ "Confidence" SG_ 568 UI_parallelAutoparkEnabled 1;
BA_ "Confidence" SG_ 568 UI_perpendicularAutoparkEnabled 1;
BA_ "Confidence" SG_ 568 UI_controlledAccess 1;
BA_ "Confidence" SG_ 568 UI_autosteerRestricted 1;
BA_ "Confidence" SG_ 645 UI_driverProfileRecallStop 1;
BA_ "Confidence" SG_ 645 UI_frontSeatRecallActive 1;
BA_ "Confidence" SG_ 645 UI_leftMirrorTiltXPosition 1;
BA_ "Confidence" SG_ 645 UI_leftMirrorTiltYPosition 1;
BA_ "Confidence" SG_ 645 UI_customMirrorDipPositionsSet 1;
BA_ "Confidence" SG_ 645 UI_leftMirrorDipXPosition 1;
BA_ "Confidence" SG_ 645 UI_leftMirrorDipYPosition 1;
BA_ "Confidence" SG_ 645 UI_modifyMirrorDipRequest 1;
BA_ "Confidence" SG_ 647 UI_driverProfileIndex 1;
BA_ "Confidence" SG_ 647 UI_driverProfileSelectionType 1;
BA_ "Confidence" SG_ 647 UI_driverProfilePositionAdjusted 1;
BA_ "Confidence" SG_ 647 UI_activeKeyRequested 1;
BA_ "Confidence" SG_ 1279 UI_energyLossTotal_epa 1;
BA_ "Confidence" SG_ 1279 UI_energyLossDriving_epa 1;
BA_ "Confidence" SG_ 1279 UI_energyLossClimate_epa 1;
BA_ "Confidence" SG_ 1279 UI_energyLossBattCond_epa 1;
BA_ "Confidence" SG_ 1279 UI_energyLossElevation_epa 1;
BA_ "Confidence" SG_ 1279 UI_energyLossAcc_epa 1;
BA_ "Confidence" SG_ 1279 UI_energyLossTotalSinceCharge_ep 1;
BA_ "SystemSignalLongSymbol" SG_ 1279 UI_energyLossTotalSinceCharge_ep "UI_energyLossTotalSinceCharge_epa";
BA_ "Confidence" SG_ 1279 UI_energyLossDrivingSinceCharge_ 1;
BA_ "SystemSignalLongSymbol" SG_ 1279 UI_energyLossDrivingSinceCharge_ "UI_energyLossDrivingSinceCharge_epa";
BA_ "Confidence" SG_ 1279 UI_energyLossClimateSinceCharge_ 1;
BA_ "SystemSignalLongSymbol" SG_ 1279 UI_energyLossClimateSinceCharge_ "UI_energyLossClimateSinceCharge_epa";
BA_ "Confidence" SG_ 1279 UI_energyLossBattCondSinceCharge 1;
BA_ "SystemSignalLongSymbol" SG_ 1279 UI_energyLossBattCondSinceCharge "UI_energyLossBattCondSinceCharge_epa";
BA_ "Confidence" SG_ 1279 UI_energyLossElevationSinceCharg 1;
BA_ "SystemSignalLongSymbol" SG_ 1279 UI_energyLossElevationSinceCharg "UI_energyLossElevationSinceCharge_epa";
BA_ "Confidence" SG_ 1279 UI_energyLossAccSinceCharge_epa 1;
BA_ "Confidence" SG_ 1279 UI_energyLossTotalSinceTripStart 1;
BA_ "Confidence" SG_ 1279 UI_energyLossDrivingSinceTripSta 1;
BA_ "SystemSignalLongSymbol" SG_ 1279 UI_energyLossDrivingSinceTripSta "UI_energyLossDrivingSinceTripStart";
BA_ "Confidence" SG_ 1279 UI_energyLossClimateSinceTripSta 1;
BA_ "SystemSignalLongSymbol" SG_ 1279 UI_energyLossClimateSinceTripSta "UI_energyLossClimateSinceTripStart";
BA_ "Confidence" SG_ 1279 UI_energyLossBattCondSinceTripSt 1;
BA_ "SystemSignalLongSymbol" SG_ 1279 UI_energyLossBattCondSinceTripSt "UI_energyLossBattCondSinceTripStart";
BA_ "Confidence" SG_ 1279 UI_energyLossElevationSinceTripS 1;
BA_ "SystemSignalLongSymbol" SG_ 1279 UI_energyLossElevationSinceTripS "UI_energyLossElevationSinceTripStart";
BA_ "Confidence" SG_ 1279 UI_energyLossAccSinceTripStart 1;
BA_ "Confidence" SG_ 1279 UI_energyDeltaTotal_epa 1;
BA_ "Confidence" SG_ 1279 UI_energyDeltaDriving_epa 1;
BA_ "Confidence" SG_ 1279 UI_energyDeltaClimate_epa 1;
BA_ "Confidence" SG_ 1279 UI_energyDeltaBattCond_epa 1;
BA_ "Confidence" SG_ 1279 UI_energyDeltaElevation_epa 1;
BA_ "Confidence" SG_ 1279 UI_energyDeltaAcc_epa 1;
BA_ "Confidence" SG_ 1279 UI_uiDeltaOffsetTotal_epa 1;
BA_ "Confidence" SG_ 1279 UI_uiDeltaOffsetDriving_epa 1;
BA_ "Confidence" SG_ 1279 UI_uiDeltaOffsetClimate_epa 1;
BA_ "Confidence" SG_ 1279 UI_uiDeltaOffsetBattCond_epa 1;
BA_ "Confidence" SG_ 1279 UI_uiDeltaOffsetElevation_epa 1;
BA_ "Confidence" SG_ 1279 UI_uiDeltaOffsetAcc_epa 1;
BA_ "Confidence" SG_ 1279 UI_rawToUiEnergyRatio_epa 1;
BA_ "Confidence" SG_ 1279 UI_driveDistance_epa 1;
BA_ "Confidence" SG_ 1279 UI_energyDeltaTotalSinceCharge_e 1;
BA_ "SystemSignalLongSymbol" SG_ 1279 UI_energyDeltaTotalSinceCharge_e "UI_energyDeltaTotalSinceCharge_epa";
BA_ "Confidence" SG_ 1279 UI_energyDeltaDrivingSinceCharge 1;
BA_ "SystemSignalLongSymbol" SG_ 1279 UI_energyDeltaDrivingSinceCharge "UI_energyDeltaDrivingSinceCharge_epa";
BA_ "Confidence" SG_ 1279 UI_energyDeltaClimateSinceCharge 1;
BA_ "SystemSignalLongSymbol" SG_ 1279 UI_energyDeltaClimateSinceCharge "UI_energyDeltaClimateSinceCharge_epa";
BA_ "Confidence" SG_ 1279 UI_energyDeltaBattCondSinceCharg 1;
BA_ "SystemSignalLongSymbol" SG_ 1279 UI_energyDeltaBattCondSinceCharg "UI_energyDeltaBattCondSinceCharge_epa";
BA_ "Confidence" SG_ 1279 UI_energyDeltaElevationSinceChar 1;
BA_ "SystemSignalLongSymbol" SG_ 1279 UI_energyDeltaElevationSinceChar "UI_energyDeltaElevationSinceCharge_epa";
BA_ "Confidence" SG_ 1279 UI_energyDeltaAccSinceCharge_epa 1;
BA_ "Confidence" SG_ 1279 UI_uiDeltaOffsetTotalSinceCharge 1;
BA_ "SystemSignalLongSymbol" SG_ 1279 UI_uiDeltaOffsetTotalSinceCharge "UI_uiDeltaOffsetTotalSinceCharge_epa";
BA_ "Confidence" SG_ 1279 UI_uiDeltaOffsetDrivingSinceChar 1;
BA_ "SystemSignalLongSymbol" SG_ 1279 UI_uiDeltaOffsetDrivingSinceChar "UI_uiDeltaOffsetDrivingSinceCharge_epa";
BA_ "Confidence" SG_ 1279 UI_uiDeltaOffsetClimateSinceChar 1;
BA_ "SystemSignalLongSymbol" SG_ 1279 UI_uiDeltaOffsetClimateSinceChar "UI_uiDeltaOffsetClimateSinceCharge_epa";
BA_ "Confidence" SG_ 1279 UI_uiDeltaOffsetBattCondSinceCha 1;
BA_ "SystemSignalLongSymbol" SG_ 1279 UI_uiDeltaOffsetBattCondSinceCha "UI_uiDeltaOffsetBattCondSinceCharge_epa";
BA_ "Confidence" SG_ 1279 UI_uiDeltaOffsetElevationSinceCh 1;
BA_ "SystemSignalLongSymbol" SG_ 1279 UI_uiDeltaOffsetElevationSinceCh "UI_uiDeltaOffsetElevationSinceCharge_epa";
BA_ "Confidence" SG_ 1279 UI_uiDeltaOffsetAccSinceCharge_e 1;
BA_ "SystemSignalLongSymbol" SG_ 1279 UI_uiDeltaOffsetAccSinceCharge_e "UI_uiDeltaOffsetAccSinceCharge_epa";
BA_ "Confidence" SG_ 1279 UI_rawToUiEnergyRatioSinceCharge 1;
BA_ "SystemSignalLongSymbol" SG_ 1279 UI_rawToUiEnergyRatioSinceCharge "UI_rawToUiEnergyRatioSinceCharge_epa";
BA_ "Confidence" SG_ 1279 UI_driveDistanceSinceCharge_epa 1;
BA_ "Confidence" SG_ 1279 UI_energyDeltaTotalSinceTripStar 1;
BA_ "SystemSignalLongSymbol" SG_ 1279 UI_energyDeltaTotalSinceTripStar "UI_energyDeltaTotalSinceTripStart";
BA_ "Confidence" SG_ 1279 UI_energyDeltaDrivingSinceTripSt 1;
BA_ "SystemSignalLongSymbol" SG_ 1279 UI_energyDeltaDrivingSinceTripSt "UI_energyDeltaDrivingSinceTripStart";
BA_ "Confidence" SG_ 1279 UI_energyDeltaClimateSinceTripSt 1;
BA_ "SystemSignalLongSymbol" SG_ 1279 UI_energyDeltaClimateSinceTripSt "UI_energyDeltaClimateSinceTripStart";
BA_ "Confidence" SG_ 1279 UI_energyDeltaBattCondSinceTripS 1;
BA_ "SystemSignalLongSymbol" SG_ 1279 UI_energyDeltaBattCondSinceTripS "UI_energyDeltaBattCondSinceTripStart";
BA_ "Confidence" SG_ 1279 UI_energyDeltaElevationSinceTrip 1;
BA_ "SystemSignalLongSymbol" SG_ 1279 UI_energyDeltaElevationSinceTrip "UI_energyDeltaElevationSinceTripStart";
BA_ "Confidence" SG_ 1279 UI_energyDeltaAccSinceTripStart 1;
BA_ "Confidence" SG_ 1279 UI_uiDeltaOffsetTotalSinceTripSt 1;
BA_ "SystemSignalLongSymbol" SG_ 1279 UI_uiDeltaOffsetTotalSinceTripSt "UI_uiDeltaOffsetTotalSinceTripStart";
BA_ "Confidence" SG_ 1279 UI_uiDeltaOffsetDrivingSinceTrip 1;
BA_ "SystemSignalLongSymbol" SG_ 1279 UI_uiDeltaOffsetDrivingSinceTrip "UI_uiDeltaOffsetDrivingSinceTripStart";
BA_ "Confidence" SG_ 1279 UI_uiDeltaOffsetClimateSinceTrip 1;
BA_ "SystemSignalLongSymbol" SG_ 1279 UI_uiDeltaOffsetClimateSinceTrip "UI_uiDeltaOffsetClimateSinceTripStart";
BA_ "Confidence" SG_ 1279 UI_uiDeltaOffsetBattCondSinceTri 1;
BA_ "SystemSignalLongSymbol" SG_ 1279 UI_uiDeltaOffsetBattCondSinceTri "UI_uiDeltaOffsetBattCondSinceTripStart";
BA_ "Confidence" SG_ 1279 UI_uiDeltaOffsetElevationSinceTr 1;
BA_ "SystemSignalLongSymbol" SG_ 1279 UI_uiDeltaOffsetElevationSinceTr "UI_uiDeltaOffsetElevationSinceTripStart";
BA_ "Confidence" SG_ 1279 UI_uiDeltaOffsetAccSinceTripStar 1;
BA_ "SystemSignalLongSymbol" SG_ 1279 UI_uiDeltaOffsetAccSinceTripStar "UI_uiDeltaOffsetAccSinceTripStart";
BA_ "Confidence" SG_ 1279 UI_rawToUiEnergyRatioSinceTripSt 1;
BA_ "SystemSignalLongSymbol" SG_ 1279 UI_rawToUiEnergyRatioSinceTripSt "UI_rawToUiEnergyRatioSinceTripStart";
BA_ "Confidence" SG_ 1279 UI_driveDistanceSinceTripStart 1;
BA_ "Confidence" SG_ 1279 UI_trailerMass 1;
BA_ "Confidence" SG_ 1139 UI_nmKeepAwakeReason 1;
BA_ "Confidence" SG_ 1139 UI_wakeupTime 1;
BA_ "Confidence" SG_ 985 UI_mapSpeedLimitUnits 1;
BA_ "Confidence" SG_ 985 UI_mppSpeedLimit 1;
BA_ "Confidence" SG_ 985 UI_gpsNmeaMIA 1;
BA_ "Confidence" SG_ 985 UI_gpsAntennaDisconnected 1;
BA_ "Confidence" SG_ 985 UI_conditionalLimitActive 1;
BA_ "Confidence" SG_ 985 UI_conditionalSpeedLimit 1;
BA_ "Confidence" SG_ 912 UI_dischargeTerminationPct 1;
BA_ "Confidence" SG_ 912 UI_powershareRequest 1;
BA_ "Confidence" SG_ 755 UI_hvacReqTempSetpointLeft 1;
BA_ "Confidence" SG_ 755 UI_hvacReqAutoBlowerLevel 1;
BA_ "Confidence" SG_ 755 UI_hvacReqTempSetpointRight 1;
BA_ "Confidence" SG_ 755 UI_hvacReqAirDistributionMode 1;
BA_ "Confidence" SG_ 755 UI_hvacReqBlowerSegment 1;
BA_ "Confidence" SG_ 755 UI_hvacReqRecirc 1;
BA_ "Confidence" SG_ 755 UI_hvacReqACDisable 1;
BA_ "Confidence" SG_ 755 UI_hvacDefogState 1;
BA_ "Confidence" SG_ 755 UI_hvacReqUserPowerState 1;
BA_ "Confidence" SG_ 755 UI_hvacReqSecondRowState 1;
BA_ "Confidence" SG_ 755 UI_hvacReqKeepClimateOn 1;
BA_ "Confidence" SG_ 755 UI_hvacReqBioWeaponDefMode 1;
BA_ "SystemSignalLongSymbol" SG_ 755 UI_hvacPhoneCallAirFlowAdjustEna "UI_hvacPhoneCallAirFlowAdjustEnabled";
BA_ "SystemSignalLongSymbol" SG_ 755 UI_enableHvacWeatherDataBasedHum "UI_enableHvacWeatherDataBasedHumidityControls";
BA_ "Confidence" SG_ 755 UI_hvacReqTempSetpointCOP 1;
BA_ "Confidence" SG_ 1011 UI_odometer 1;
BA_ "Confidence" SG_ 948 UI_usbFrontHubPowerStateRequest 1;
BA_ "Confidence" SG_ 955 UI_dSocAlertEnable 1;
BA_ "Confidence" SG_ 827 UI_idlePowerConsumption 1;
BA_ "Confidence" SG_ 827 UI_chargeTimeUntilTerminationPct 1;
BA_ "Confidence" SG_ 827 UI_chargeTimeUntilReadyToDepart 1;
BA_ "SystemSignalLongSymbol" SG_ 629 UI_vcleftCfgRationalityThreshold "UI_vcleftCfgRationalityThreshold0";
BA_ "SystemSignalLongSymbol" SG_ 629 UI_vcleftCfgRationalityThre_0001 "UI_vcleftCfgRationalityThreshold1";
BA_ "SystemSignalLongSymbol" SG_ 629 UI_vcrightCfgRationalityThreshol "UI_vcrightCfgRationalityThreshold0";
BA_ "SystemSignalLongSymbol" SG_ 629 UI_vcrightCfgRationalityThr_0001 "UI_vcrightCfgRationalityThreshold1";
BA_ "Confidence" SG_ 820 UI_pedalMap 1;
BA_ "Confidence" SG_ 820 UI_enableRegenBackfill 1;
BA_ "Confidence" SG_ 820 UI_regenTorqueMax 1;
BA_ "Confidence" SG_ 820 UI_limitMode 1;
BA_ "SystemSignalLongSymbol" SG_ 820 UI_factoryCustomerDrivingModeReq "UI_factoryCustomerDrivingModeRequest";
BA_ "Confidence" SG_ 820 UI_motorOnMode 1;
BA_ "Confidence" SG_ 820 UI_stoppingMode 1;
BA_ "Confidence" SG_ 820 UI_speedLimit 1;
BA_ "Confidence" SG_ 820 UI_enableSmartShift 1;
BA_ "Confidence" SG_ 820 UI_navVehParallelToRdCanContinue 1;
BA_ "Confidence" SG_ 826 UI_ratedRange 1;
BA_ "Confidence" SG_ 826 UI_soe 1;
BA_ "Confidence" SG_ 826 UI_uSoe 1;
BA_ "Confidence" SG_ 666 UI_3RSeatChildLock 1;
BA_ "Confidence" SG_ 666 UI_left3RowSeatAdjustmentRequest 1;
BA_ "Confidence" SG_ 666 UI_right3RowSeatAdjustmentReques 1;
BA_ "SystemSignalLongSymbol" SG_ 666 UI_right3RowSeatAdjustmentReques "UI_right3RowSeatAdjustmentRequest";
BA_ "Confidence" SG_ 666 UI_2RLeftSeatFanReq 1;
BA_ "Confidence" SG_ 666 UI_2RRightSeatFanReq 1;
BA_ "SystemSignalLongSymbol" SG_ 666 UI_leftThirdRowSeatRequestFromRe "UI_leftThirdRowSeatRequestFromRearDisplay";
BA_ "SystemSignalLongSymbol" SG_ 666 UI_rightThirdRowSeatRequestFromR "UI_rightThirdRowSeatRequestFromRearDisplay";
BA_ "Confidence" SG_ 666 UI_seatChoreographyStopRequest 1;
BA_ "Confidence" SG_ 723 UI_isSunUp 1;
BA_ "Confidence" SG_ 723 UI_solarElevationAngle 1;
BA_ "Confidence" SG_ 723 UI_screenPCBTemperature 1;
BA_ "Confidence" SG_ 723 UI_minsToSunset 1;
BA_ "Confidence" SG_ 723 UI_minsToSunrise 1;
BA_ "Confidence" SG_ 563 UI_gearRequest 1;
BA_ "Confidence" SG_ 563 UI_gearStripShowing 1;
BA_ "Confidence" SG_ 563 UI_gearStripForceShow 1;
BA_ "Confidence" SG_ 563 UI_autoParkAvailable 1;
BA_ "Confidence" SG_ 563 UI_gearStripSuppressActive 1;
BA_ "Confidence" SG_ 563 UI_gearNeutralPressed 1;
BA_ "Confidence" SG_ 851 UI_touchActive 1;
BA_ "Confidence" SG_ 851 UI_audioActive 1;
BA_ "Confidence" SG_ 851 UI_cellActive 1;
BA_ "Confidence" SG_ 851 UI_displayReady 1;
BA_ "Confidence" SG_ 851 UI_displayOn 1;
BA_ "Confidence" SG_ 851 UI_wifiActive 1;
BA_ "Confidence" SG_ 851 UI_wifiConnected 1;
BA_ "Confidence" SG_ 851 UI_readyForDrive 1;
BA_ "Confidence" SG_ 851 UI_cellConnected 1;
BA_ "Confidence" SG_ 851 UI_vpnActive 1;
BA_ "Confidence" SG_ 851 UI_factoryReset 1;
BA_ "Confidence" SG_ 851 UI_gpsActive 1;
BA_ "Confidence" SG_ 851 UI_cellNetworkTechnology 1;
BA_ "Confidence" SG_ 851 UI_falseTouchCounter 1;
BA_ "Confidence" SG_ 851 UI_cellSignalBars 1;
BA_ "Confidence" SG_ 851 UI_trailerModeTelltale 1;
BA_ "Confidence" SG_ 851 UI_pcbTemperature 1;
BA_ "Confidence" SG_ 851 UI_cpuTemperature 1;
BA_ "Confidence" SG_ 991 UI_userActivity 1;
BA_ "Confidence" SG_ 991 UI_activeTouchPoints 1;
BA_ "Confidence" SG_ 991 UI_linkState 1;
BA_ "Confidence" SG_ 991 UI_autopilotSentryRequest 1;
BA_ "Confidence" SG_ 991 UI_mobileAppConnected 1;
BA_ "Confidence" SG_ 991 UI_phoneLeftInCabin 1;
BA_ "Confidence" SG_ 991 UI_autoshiftDRState 1;
BA_ "Confidence" SG_ 991 UI_wifiBtModuleType 1;
BA_ "Confidence" SG_ 991 UI_selfParkState 1;
BA_ "Confidence" SG_ 991 UI_summonDeviceIndex 1;
BA_ "Confidence" SG_ 991 UI_fullScreenMode 1;
BA_ "Confidence" SG_ 986 UI_wifiRegDomain 1;
BA_ "Confidence" SG_ 986 UI_wifiTethered 1;
BA_ "Confidence" SG_ 663 UI_adaptiveRideRequest 1;
BA_ "Confidence" SG_ 663 UI_geofenceLevelingRequest 1;
BA_ "Confidence" SG_ 661 UI_SystemMemUsage 1;
BA_ "Confidence" SG_ 661 UI_QtCarMemUsage 1;
BA_ "Confidence" SG_ 661 UI_QtCarCPUUsage 1;
BA_ "Confidence" SG_ 661 UI_SystemCPUUsage 1;
BA_ "Confidence" SG_ 952 UI_sendCalibrateTireRequest 1;
BA_ "Confidence" SG_ 787 UI_trackModeRequest 1;
BA_ "Confidence" SG_ 787 UI_trackDrivePowerAvailability 1;
BA_ "Confidence" SG_ 1263 UI_fwHeatOnNavArrivalSOE 1;
BA_ "Confidence" SG_ 1263 UI_voyagerHeatOnNavArrivalSOE 1;
BA_ "Confidence" SG_ 130 UI_tripPlanningActive 1;
BA_ "Confidence" SG_ 130 UI_navToSupercharger 1;
BA_ "Confidence" SG_ 130 UI_navFastchargerType 1;
BA_ "Confidence" SG_ 130 UI_battPreconditionOnNavState 1;
BA_ "Confidence" SG_ 130 UI_requestActiveBatteryHeating 1;
BA_ "Confidence" SG_ 130 UI_battPreconditionOnNavPowerReq 1;
BA_ "Confidence" SG_ 130 UI_battPreconditionOnNavTargetT 1;
BA_ "Confidence" SG_ 130 UI_energyAtDestination 1;
BA_ "Confidence" SG_ 139 UI_maxSpeedToReachDestination 1;
BA_ "Confidence" SG_ 139 UI_timeToDestination 1;
BA_ "Confidence" SG_ 1173 UI_predictedEnergy 1;
BA_ "Confidence" SG_ 1173 UI_hindsightEnergy 1;
BA_ "Confidence" SG_ 850 UI_centerDisplayRunning 1;
BA_ "Confidence" SG_ 850 UI_centerDisplayPowerOn 1;
BA_ "Confidence" SG_ 850 UI_rearDisplayRunning 1;
BA_ "Confidence" SG_ 850 UI_rearDisplayPowerOn 1;
BA_ "Confidence" SG_ 627 UI_powerStateRequest 1;
BA_ "Confidence" SG_ 627 UI_childDoorLockOnRight 1;
BA_ "Confidence" SG_ 627 UI_frontFogSwitch 1;
BA_ "Confidence" SG_ 627 UI_summonActive 1;
BA_ "Confidence" SG_ 627 UI_frunkRequest 1;
BA_ "Confidence" SG_ 627 UI_wiperMode 1;
BA_ "Confidence" SG_ 627 UI_steeringButtonMode 1;
BA_ "Confidence" SG_ 627 UI_walkUpUnlock 1;
BA_ "Confidence" SG_ 627 UI_walkAwayLock 1;
BA_ "Confidence" SG_ 627 UI_unlockOnPark 1;
BA_ "Confidence" SG_ 627 UI_globalUnlockOn 1;
BA_ "Confidence" SG_ 627 UI_childDoorLockOnLeft 1;
BA_ "Confidence" SG_ 627 UI_lockRequest 1;
BA_ "Confidence" SG_ 627 UI_alarmEnabled 1;
BA_ "Confidence" SG_ 627 UI_stop12vSupport 1;
BA_ "Confidence" SG_ 627 UI_rearFogSwitch 1;
BA_ "Confidence" SG_ 627 UI_mirrorFoldRequest 1;
BA_ "Confidence" SG_ 627 UI_mirrorHeatRequest 1;
BA_ "Confidence" SG_ 627 UI_remoteStartRequest 1;
BA_ "Confidence" SG_ 627 UI_seeYouHomeLightingOn 1;
BA_ "Confidence" SG_ 627 UI_powerOff 1;
BA_ "Confidence" SG_ 627 UI_displayBrightnessLevel 1;
BA_ "Confidence" SG_ 627 UI_autoHighBeamEnabled 1;
BA_ "Confidence" SG_ 627 UI_frontLeftSeatHeatReq 1;
BA_ "Confidence" SG_ 627 UI_frontRightSeatHeatReq 1;
BA_ "Confidence" SG_ 627 UI_rearLeftSeatHeatReq 1;
BA_ "Confidence" SG_ 627 UI_rearCenterSeatHeatReq 1;
BA_ "Confidence" SG_ 627 UI_rearRightSeatHeatReq 1;
BA_ "Confidence" SG_ 627 UI_autoFoldMirrorsOn 1;
BA_ "Confidence" SG_ 627 UI_mirrorDipOnReverse 1;
BA_ "Confidence" SG_ 627 UI_remoteClosureRequest 1;
BA_ "Confidence" SG_ 627 UI_wiperRequest 1;
BA_ "Confidence" SG_ 627 UI_domeLightSwitch 1;
BA_ "Confidence" SG_ 947 UI_gloveboxRequest 1;
BA_ "Confidence" SG_ 947 UI_trunkRequest 1;
BA_ "Confidence" SG_ 947 UI_PINToDriveEnabled 1;
BA_ "Confidence" SG_ 947 UI_PINToDrivePassed 1;
BA_ "Confidence" SG_ 947 UI_disableMirrorAutoDim 1;
BA_ "Confidence" SG_ 947 UI_lightSwitch 1;
BA_ "Confidence" SG_ 947 UI_readyToAddKey 1;
BA_ "Confidence" SG_ 947 UI_alarmTriggerRequest 1;
BA_ "Confidence" SG_ 947 UI_displayOnForUser 1;
BA_ "Confidence" SG_ 947 UI_BLEPushNotificationRequest 1;
BA_ "Confidence" SG_ 947 UI_keepAutopilotAwake 1;
BA_ "Confidence" SG_ 947 UI_batteryPreconditioningRequest 1;
BA_ "Confidence" SG_ 947 UI_autopilotPowerStateRequest 1;
BA_ "Confidence" SG_ 947 UI_autoRollWindowsOnLockEnable 1;
BA_ "SystemSignalLongSymbol" SG_ 947 UI_virtualPitchSensorOverrideOKF "UI_virtualPitchSensorOverrideOKForAim";
BA_ "SystemSignalLongSymbol" SG_ 947 UI_conditionalLoggingEnabledVCSE "UI_conditionalLoggingEnabledVCSEC";
BA_ "Confidence" SG_ 947 UI_steeringWheelHeatReq 1;
BA_ "Confidence" SG_ 947 UI_disableHorn 1;
BA_ "Confidence" SG_ 947 UI_frontLeftSeatFanReq 1;
BA_ "Confidence" SG_ 947 UI_frontRightSeatAutoClimateReq 1;
BA_ "Confidence" SG_ 947 UI_frontRightSeatFanReq 1;
BA_ "Confidence" SG_ 947 UI_3RLeftSeatHeatReq 1;
BA_ "Confidence" SG_ 947 UI_3RRightSeatHeatReq 1;
BA_ "Confidence" SG_ 947 UI_frontLeftSeatAutoClimateReq 1;
BA_ "Confidence" SG_ 947 UI_wiperHeaterReq 1;
BA_ "Confidence" SG_ 947 UI_silentAlarm 1;
BA_ "Confidence" SG_ 628 UI_lightFlashRequest 1;
BA_ "Confidence" SG_ 628 UI_phoneCallActive 1;
BA_ "Confidence" SG_ 628 UI_lightShowClosuresEnabled 1;
BA_ "Confidence" SG_ 628 UI_steeringWheelHeatAutoReq 1;
BA_ "Confidence" SG_ 628 UI_steeringWheelHeatLevelReq 1;
BA_ "Confidence" SG_ 628 UI_headlightPulseRequest 1;
BA_ "Confidence" SG_ 628 UI_displayRedShiftActive 1;
BA_ "Confidence" SG_ 628 UI_fasciaCameraWashRequest 1;
BA_ "Confidence" SG_ 628 UI_leftRearSeatAdjustmentRequest 1;
BA_ "Confidence" SG_ 628 UI_rightRearSeatAdjustmentReques 1;
BA_ "SystemSignalLongSymbol" SG_ 628 UI_rightRearSeatAdjustmentReques "UI_rightRearSeatAdjustmentRequest";
BA_ "Confidence" SG_ 628 UI_blindSpotIndicatorLightReques 1;
BA_ "SystemSignalLongSymbol" SG_ 628 UI_blindSpotIndicatorLightReques "UI_blindSpotIndicatorLightRequest";
BA_ "Confidence" SG_ 628 UI_keepOnAccessoryPortsReq 1;
BA_ "Confidence" SG_ 628 UI_fasciaCameraShown 1;
BA_ "Confidence" SG_ 628 UI_rearSeatChildLock 1;
BA_ "Confidence" SG_ 628 UI_windowPercentageRequest 1;
BA_ "Confidence" SG_ 628 UI_windowRequestedFL 1;
BA_ "Confidence" SG_ 628 UI_windowRequestedFR 1;
BA_ "Confidence" SG_ 628 UI_windowRequestedRL 1;
BA_ "Confidence" SG_ 628 UI_windowRequestedRR 1;
BA_ "Confidence" SG_ 628 UI_windowRequest 1;
BA_ "Confidence" SG_ 628 UI_closeTrunkRequest 1;
BA_ "Confidence" SG_ 628 UI_childPresenceDetectionDisable 1;
BA_ "SystemSignalLongSymbol" SG_ 628 UI_childPresenceDetectionDisable "UI_childPresenceDetectionDisableRequest";
BA_ "Confidence" SG_ 628 UI_derivedLoadshedFeature 1;
BA_ "SystemSignalLongSymbol" SG_ 628 UI_leftRearSeatRequestFromRearDi "UI_leftRearSeatRequestFromRearDisplay";
BA_ "Confidence" SG_ 628 UI_selfParkStandingBy 1;
BA_ "SystemSignalLongSymbol" SG_ 628 UI_rightRearSeatRequestFromRearD "UI_rightRearSeatRequestFromRearDisplay";
BA_ "Confidence" SG_ 1193 UI_firstRowLeftDomeLightRequest 1;
BA_ "Confidence" SG_ 1193 UI_firstRowRightDomeLightRequest 1;
BA_ "Confidence" SG_ 1193 UI_secondRowLeftDomeLightRequest 1;
BA_ "Confidence" SG_ 1193 UI_secondRowCenterDomeLightReque 1;
BA_ "SystemSignalLongSymbol" SG_ 1193 UI_secondRowCenterDomeLightReque "UI_secondRowCenterDomeLightRequest";
BA_ "Confidence" SG_ 1193 UI_secondRowRightDomeLightReques 1;
BA_ "SystemSignalLongSymbol" SG_ 1193 UI_secondRowRightDomeLightReques "UI_secondRowRightDomeLightRequest";
BA_ "Confidence" SG_ 1193 UI_thirdRowLeftDomeLightRequest 1;
BA_ "Confidence" SG_ 1193 UI_thirdRowRightDomeLightRequest 1;
BA_ "Confidence" SG_ 853 UI_coolantFlowRequest 1;
BA_ "Confidence" SG_ 853 UI_inletActiveCoolTarget 1;
BA_ "Confidence" SG_ 853 UI_disableHVPTThermalLoads 1;
BA_ "SystemSignalLongSymbol" SG_ 853 UI_enableCOP1CabinHeatingBattery "UI_enableCOP1CabinHeatingBatteryHeating";
BA_ "SystemSignalLongSymbol" SG_ 853 UI_enableUserFacingLowFlowDelive "UI_enableUserFacingLowFlowDeliveryAlert";
BA_ "SystemSignalLongSymbol" SG_ 853 UI_enableThermalDriverlessSelfTe "UI_enableThermalDriverlessSelfTest";
BA_ "Confidence" SG_ 853 UI_convenienceFeatureLimit 1;
BA_ "Confidence" SG_ 853 UI_allowConvenienceFeatures 1;
BA_ "SystemSignalLongSymbol" SG_ 853 UI_enableConservativeBatteryHeat "UI_enableConservativeBatteryHeating";
BA_ "Confidence" SG_ 853 UI_disablePhoneChargingPads 1;
BA_ "Confidence" SG_ 644 UI_transportMode 1;
BA_ "Confidence" SG_ 644 UI_showroomMode 1;
BA_ "Confidence" SG_ 644 UI_serviceMode 1;
BA_ "Confidence" SG_ 644 UI_carWashMode 1;
BA_ "Confidence" SG_ 644 UI_gameMode 1;
BA_ "Confidence" SG_ 644 UI_serviceModePlus 1;
BA_ "Confidence" SG_ 644 UI_premiumAmpPowerOff 1;
BA_ "Confidence" SG_ 644 UI_lightShowType 1;
BA_ "Confidence" SG_ 644 UI_upkeepMode 1;
BA_ "Confidence" SG_ 595 UI_ventPanelLeftPositionX 1;
BA_ "Confidence" SG_ 595 UI_ventPanelLeftPositionY 1;
BA_ "Confidence" SG_ 595 UI_ventPanelLeftLateralSplit 1;
BA_ "Confidence" SG_ 595 UI_ventPanelRightPositionX 1;
BA_ "Confidence" SG_ 595 UI_ventPanelRightPositionY 1;
BA_ "Confidence" SG_ 595 UI_ventPanelRightLateralSplit 1;
BA_ "Confidence" SG_ 595 UI_ventPanelLeftLateralMode 1;
BA_ "Confidence" SG_ 595 UI_ventPanelRightLateralMode 1;
BA_ "Confidence" SG_ 595 UI_hvacReqActiveVents 1;
BA_ "Confidence" SG_ 595 UI_vent2RLeftPositionX 1;
BA_ "Confidence" SG_ 595 UI_vent2RLeftPositionY 1;
BA_ "Confidence" SG_ 595 UI_vent2RRightPositionX 1;
BA_ "Confidence" SG_ 595 UI_vent2RRightPositionY 1;
BA_ "Confidence" SG_ 595 UI_hvacReqThirdRowState 1;
VAL_ 659 UI_steeringTuneRequest 2 "STEERING_TUNE_SPORT" 1 "STEERING_TUNE_STANDARD" 0 "STEERING_TUNE_COMFORT" ;
VAL_ 659 UI_tractionControlMode 7 "TC_SLIPPERY_SURFACE_SELECTED" 6 "TC_OFFROAD_ASSIST_SELECTED" 5 "TC_DYNO_MODE_SELECTED" 4 "TC_ROLLS_MODE_SELECTED" 3 "TC_DEV_MODE_2_SELECTED" 2 "TC_DEV_MODE_1_SELECTED" 1 "TC_SLIP_START_SELECTED" 0 "TC_NORMAL_SELECTED" ;
VAL_ 659 UI_parkBrakeRequest 3 "PARK_BRAKE_REQUEST_SNA" 1 "PARK_BRAKE_REQUEST_PRESSED" 0 "PARK_BRAKE_REQUEST_IDLE" ;
VAL_ 659 UI_winchModeRequest 3 "WINCH_MODE_DIALOGUE_OPEN" 2 "WINCH_MODE_EXIT" 1 "WINCH_MODE_ENTER" 0 "WINCH_MODE_IDLE" ;
VAL_ 659 UI_trailerMode 1 "TRAILER_MODE_ON" 0 "TRAILER_MODE_OFF" ;
VAL_ 659 UI_accOvertakeEnable 1 "ACC_OVERTAKE_ON" 0 "ACC_OVERTAKE_OFF" ;
VAL_ 659 UI_aebEnable 1 "AEB_ON" 0 "AEB_OFF" ;
VAL_ 659 UI_aesEnable 1 "AES_ON" 0 "AES_OFF" ;
VAL_ 659 UI_ahlbEnable 1 "AHLB_ON" 0 "AHLB_OFF" ;
VAL_ 659 UI_autoLaneChangeEnable 1 "ON" 0 "OFF" ;
VAL_ 659 UI_autoParkRequest 12 "BEGIN_PARKING" 11 "RESUME" 10 "PAUSE" 9 "SEARCH" 8 "COMPLETE" 7 "ABORT" 6 "PARALLEL_PULL_OUT_TO_RIGHT" 5 "PARALLEL_PULL_OUT_TO_LEFT" 4 "PARK_RIGHT_CROSS" 3 "PARK_RIGHT_PARALLEL" 2 "PARK_LEFT_CROSS" 1 "PARK_LEFT_PARALLEL" 0 "NONE" ;
VAL_ 659 UI_bsdEnable 1 "BSD_ON" 0 "BSD_OFF" ;
VAL_ 659 UI_fcwEnable 1 "FCW_ON" 0 "FCW_OFF" ;
VAL_ 659 UI_fcwSensitivity 2 "AEB_SENSITIVITY_LATE" 1 "AEB_SENSITIVITY_AVERAGE" 0 "AEB_SENSITIVITY_EARLY" ;
VAL_ 659 UI_latControlEnable 3 "LATERAL_CONTROL_SNA" 2 "LATERAL_CONTROL_UNAVAILABLE" 1 "LATERAL_CONTROL_ON" 0 "LATERAL_CONTROL_OFF" ;
VAL_ 659 UI_ldwEnable 1 "LDW_TRIGGERS_HAPTIC" 0 "NO_HAPTIC" ;
VAL_ 531 UI_cruiseSpeedCommand 6 "CRUISE_SPEED_SNAP_SPEEDO" 5 "CRUISE_SPEED_SNAP" 4 "CRUISE_SPEED_DEC_LONG" 3 "CRUISE_SPEED_DEC_SHORT" 2 "CRUISE_SPEED_INC_LONG" 1 "CRUISE_SPEED_INC_SHORT" 0 "CRUISE_SPEED_IDLE" ;
VAL_ 531 UI_autonomySummonRequest 4 "ABORT" 3 "SUMMON" 2 "REVERSE" 1 "FORWARD" 0 "NONE" ;
VAL_ 1016 UI_lssLkaEnabled 1 "LKA_ON" 0 "LKA_OFF" ;
VAL_ 1016 UI_lssLdwEnabled 1 "LDW_ON" 0 "LDW_OFF" ;
VAL_ 1016 UI_driveOnMapsEnable 1 "DOM_ON" 0 "DOM_OFF" ;
VAL_ 1016 UI_lssElkEnabled 1 "ELK_ON" 0 "ELK_OFF" ;
VAL_ 1016 UI_selfParkRequest 12 "SMART_SUMMON_NO_OP" 11 "SMART_SUMMON" 10 "AUTO_SUMMON_PRIMED" 9 "AUTO_SUMMON_CANCEL" 8 "AUTO_SUMMON_REVERSE" 7 "AUTO_SUMMON_FORWARD" 6 "RESUME" 5 "PAUSE" 4 "PRIME" 3 "ABORT" 2 "SELF_PARK_REVERSE" 1 "SELF_PARK_FORWARD" 0 "NONE" ;
VAL_ 1016 UI_followNavRouteEnable 1 "NAV_ROUTE_ON" 0 "NAV_ROUTE_OFF" ;
VAL_ 1016 UI_ulcSpeedConfig 3 "SPEED_BASED_ULC_MAD_MAX" 2 "SPEED_BASED_ULC_AVERAGE" 1 "SPEED_BASED_ULC_MILD" 0 "SPEED_BASED_ULC_DISABLED" ;
VAL_ 1016 UI_smartSummonType 2 "SMART_AUTOPARK" 1 "FIND_ME" 0 "PIN_DROP" ;
VAL_ 568 UI_roadClass 6 "CLASS_6_MINOR" 5 "CLASS_5" 4 "CLASS_4" 3 "CLASS_3" 2 "CLASS_2" 1 "CLASS_1_MAJOR" 0 "UNKNOWN_INVALID_SNA" ;
VAL_ 645 UI_modifyMirrorDipRequest 2 "MODIFY_MIRROR_DIP_REQUEST_DIPPED" 1 "MODIFY_MIRROR_DIP_REQUEST_UNDIPPED" 0 "MODIFY_MIRROR_DIP_REQUEST_NONE" ;
VAL_ 647 UI_driverProfileSelectionType 3 "DRIVER_PROFILE_SELECTION_TYPE_NONE" 2 "DRIVER_PROFILE_SELECTION_TYPE_AUTOMATIC_NO_OP" 1 "DRIVER_PROFILE_SELECTION_TYPE_AUTOMATIC_RESTORE" 0 "DRIVER_PROFILE_SELECTION_TYPE_MANUAL" ;
VAL_ 1139 UI_nmKeepAwakeReason 52 "UI_KEEPAWAKE_REASON_UNSPECIFIED" 51 "UI_KEEPAWAKE_REASON_MANUAL_REQUEST" 50 "UI_KEEPAWAKE_REASON_PLB" 49 "UI_KEEPAWAKE_REASON_PM_WAKE_DEBOUNCE" 48 "UI_KEEPAWAKE_REASON_FLASH_ROM" 47 "UI_KEEPAWAKE_REASON_SET_CLIMATE_KEEPER_MODE" 46 "UI_KEEPAWAKE_REASON_CHARGE_STOP" 45 "UI_KEEPAWAKE_REASON_CHARGE_START" 44 "UI_KEEPAWAKE_REASON_CHARGE_PORT_DOOR_OPEN" 43 "UI_KEEPAWAKE_REASON_SET_VALET_MODE" 42 "UI_KEEPAWAKE_REASON_SET_SENTRY_MODE" 41 "UI_KEEPAWAKE_REASON_ACTUATE_TRUNK" 40 "UI_KEEPAWAKE_REASON_REMOTE_START_DRIVE" 39 "UI_KEEPAWAKE_REASON_SET_CHARGE_LIMIT" 38 "UI_KEEPAWAKE_REASON_FLASH_LIGHTS" 37 "UI_KEEPAWAKE_REASON_SET_TEMPS" 36 "UI_KEEPAWAKE_REASON_ACC_POWER_ON" 35 "UI_KEEPAWAKE_REASON_DOOR_LOCK" 34 "UI_KEEPAWAKE_REASON_DOOR_UNLOCK" 33 "UI_KEEPAWAKE_REASON_MOTHERSHIP_SMS_FLEET_WAKE_UP" 32 "UI_KEEPAWAKE_REASON_SET_VEHICLE_CONFIGURATION" 31 "UI_KEEPAWAKE_REASON_AUTO_CONDITIONING_START" 30 "UI_KEEPAWAKE_REASON_WINDOW_CONTROL" 29 "UI_KEEPAWAKE_REASON_GET_VEHICLE_CONFIGURATION" 28 "UI_KEEPAWAKE_REASON_MOTHERSHIP_SMS_OWNER_WAKE_UP" 27 "UI_KEEPAWAKE_REASON_MOTHERSHIP_SMS_GARAGE_WAKE_UP" 26 "UI_KEEPAWAKE_REASON_MOTHERSHIP_SMS_VEHICLE_TASK" 25 "UI_KEEPAWAKE_REASON_MOTHERSHIP_SMS_YOUVE_GOT_MAIL" 24 "UI_KEEPAWAKE_REASON_WAKE_UP" 23 "UI_KEEPAWAKE_REASON_FIRMWARE_HANDSHAKE" 22 "UI_KEEPAWAKE_REASON_VEHICLE_DATA" 21 "UI_KEEPAWAKE_REASON_DIAG_VITALS" 20 "UI_KEEPAWAKE_REASON_URGENT_UPLOAD" 19 "UI_KEEPAWAKE_REASON_UI_REQUEST_AP_KEEPALIVE" 18 "UI_KEEPAWAKE_REASON_STEAM" 17 "UI_KEEPAWAKE_REASON_CHARGING" 16 "UI_KEEPAWAKE_REASON_UI_HVAC_REQUEST" 15 "UI_KEEPAWAKE_REASON_USER_NOTIFICATION_TIMER" 14 "UI_KEEPAWAKE_REASON_ODIN" 13 "UI_KEEPAWAKE_REASON_MEDIA_DOWNLOAD" 12 "UI_KEEPAWAKE_REASON_SENTRY_MODE" 11 "UI_KEEPAWAKE_REASON_SELFTEST" 10 "UI_KEEPAWAKE_REASON_ECALL_ACTIVE" 9 "UI_KEEPAWAKE_REASON_UPDATE_COUNTDOWN" 8 "UI_KEEPAWAKE_REASON_AUTOFUSER" 7 "UI_KEEPAWAKE_REASON_HERMES" 6 "UI_KEEPAWAKE_REASON_UPDATER" 5 "UI_KEEPAWAKE_REASON_MODEM_RESET" 4 "UI_KEEPAWAKE_REASON_UNKNOWN_REMOTE_REQUEST" 3 "UI_KEEPAWAKE_REASON_PM_CHECKING" 2 "UI_KEEPAWAKE_REASON_GUI_NEVER_SLEEP_SET" 1 "UI_KEEPAWAKE_REASON_KEEPALIVEACTIVE" 0 "UI_KEEPAWAKE_REASON_NONE_SNA" ;
VAL_ 985 UI_mapSpeedLimitUnits 1 "KPH" 0 "MPH" ;
VAL_ 912 UI_powershareRequest 2 "POWERSHARE_REQUEST_AUTHENTICATED" 1 "POWERSHARE_REQUEST_STANDARD_VEHICLE" 0 "POWERSHARE_REQUEST_DISABLE" ;
VAL_ 755 UI_hvacReqAutoBlowerLevel 4 "VERY_HIGH" 3 "HIGH" 2 "MEDIUM" 1 "LOW" 0 "VERY_LOW" ;
VAL_ 755 UI_hvacReqAirDistributionMode 7 "MANUAL_DEFROST_PANEL_FLOOR" 6 "MANUAL_DEFROST_PANEL" 5 "MANUAL_DEFROST_FLOOR" 4 "MANUAL_DEFROST" 3 "MANUAL_PANEL_FLOOR" 2 "MANUAL_PANEL" 1 "MANUAL_FLOOR" 0 "AUTO" ;
VAL_ 755 UI_hvacReqBlowerSegment 11 "AUTO" 10 "10" 9 "9" 8 "8" 7 "7" 6 "6" 5 "5" 4 "4" 3 "3" 2 "2" 1 "1" 0 "OFF" ;
VAL_ 755 UI_hvacReqRecirc 2 "FRESH" 1 "RECIRC" 0 "AUTO" ;
VAL_ 755 UI_hvacReqACDisable 2 "ON" 1 "OFF" 0 "AUTO" ;
VAL_ 755 UI_hvacDefogState 3 "AUTO_DEFOG" 2 "DEFROST" 1 "DEFOG" 0 "NONE" ;
VAL_ 755 UI_hvacReqUserPowerState 4 "OVERHEAT_PROTECT" 3 "OVERHEAT_PROTECT_FANONLY" 2 "PRECONDITION" 1 "ON" 0 "OFF" ;
VAL_ 755 UI_hvacReqSecondRowState 4 "HIGH" 3 "MED" 2 "LOW" 1 "OFF" 0 "AUTO" ;
VAL_ 755 UI_hvacReqKeepClimateOn 3 "KEEP_CLIMATE_ON_REQ_PARTY" 2 "KEEP_CLIMATE_ON_REQ_DOG" 1 "KEEP_CLIMATE_ON_REQ_ON" 0 "KEEP_CLIMATE_ON_REQ_OFF" ;
VAL_ 755 UI_hvacReqTempSetpointCOP 2 "HIGH" 1 "MEDIUM" 0 "LOW" ;
VAL_ 948 UI_usbFrontHubPowerStateRequest 2 "POWER_ON" 1 "POWER_NO_PREFERENCE" 0 "POWER_REQUEST_SNA" ;
VAL_ 820 UI_pedalMap 2 "PERFORMANCE" 1 "SPORT" 0 "CHILL" ;
VAL_ 820 UI_limitMode 3 "LIMIT_SERVICE" 2 "LIMIT_FACTORY" 1 "LIMIT_VALET" 0 "LIMIT_NORMAL" ;
VAL_ 820 UI_motorOnMode 2 "MOTORONMODE_REAR_ONLY" 1 "MOTORONMODE_FRONT_ONLY" 0 "MOTORONMODE_NORMAL" ;
VAL_ 820 UI_stoppingMode 2 "HOLD" 1 "CREEP" 0 "STANDARD" ;
VAL_ 820 UI_enableSmartShift 2 "ENABLED_P_R_D" 1 "ENABLED_P" 0 "OFF" ;
VAL_ 820 UI_navVehParallelToRdCanContinue 2 "TRUE" 1 "FALSE" ;
VAL_ 666 UI_3RSeatChildLock 3 "UI_ADJUSTABLE_FOLD_FLAT_CHILD_LOCK_BOTH" 2 "UI_ADJUSTABLE_FOLD_FLAT_CHILD_LOCK_RIGHT" 1 "UI_ADJUSTABLE_FOLD_FLAT_CHILD_LOCK_LEFT" 0 "UI_ADJUSTABLE_FOLD_FLAT_CHILD_LOCK_NONE" ;
VAL_ 666 UI_left3RowSeatAdjustmentRequest 6 "UI_ADJUSTABLE_FOLD_FLAT_REQUEST_STOP" 5 "UI_ADJUSTABLE_FOLD_FLAT_REQUEST_TOGGLE_FOLD" 4 "UI_ADJUSTABLE_FOLD_FLAT_REQUEST_REARWARD_FAST" 3 "UI_ADJUSTABLE_FOLD_FLAT_REQUEST_REARWARD_COMFORT" 2 "UI_ADJUSTABLE_FOLD_FLAT_REQUEST_FORWARD_FAST" 1 "UI_ADJUSTABLE_FOLD_FLAT_REQUEST_FORWARD_COMFORT" 0 "UI_ADJUSTABLE_FOLD_FLAT_REQUEST_NONE" ;
VAL_ 666 UI_right3RowSeatAdjustmentReques 6 "UI_ADJUSTABLE_FOLD_FLAT_REQUEST_STOP" 5 "UI_ADJUSTABLE_FOLD_FLAT_REQUEST_TOGGLE_FOLD" 4 "UI_ADJUSTABLE_FOLD_FLAT_REQUEST_REARWARD_FAST" 3 "UI_ADJUSTABLE_FOLD_FLAT_REQUEST_REARWARD_COMFORT" 2 "UI_ADJUSTABLE_FOLD_FLAT_REQUEST_FORWARD_FAST" 1 "UI_ADJUSTABLE_FOLD_FLAT_REQUEST_FORWARD_COMFORT" 0 "UI_ADJUSTABLE_FOLD_FLAT_REQUEST_NONE" ;
VAL_ 666 UI_2RLeftSeatFanReq 3 "FAN_REQUEST_LEVEL3" 2 "FAN_REQUEST_LEVEL2" 1 "FAN_REQUEST_LEVEL1" 0 "FAN_REQUEST_OFF" ;
VAL_ 666 UI_2RRightSeatFanReq 3 "FAN_REQUEST_LEVEL3" 2 "FAN_REQUEST_LEVEL2" 1 "FAN_REQUEST_LEVEL1" 0 "FAN_REQUEST_OFF" ;
VAL_ 723 UI_isSunUp 3 "SUN_SNA" 1 "SUN_UP" 0 "SUN_DOWN" ;
VAL_ 563 UI_gearRequest 4 "GEAR_REQUEST_DRIVE" 3 "GEAR_REQUEST_NEUTRAL" 2 "GEAR_REQUEST_REVERSE" 1 "GEAR_REQUEST_PARK" 0 "GEAR_REQUEST_IDLE_SNA" ;
VAL_ 851 UI_factoryReset 3 "CUSTOMER" 2 "DIAGNOSTIC" 1 "DEVELOPER" 0 "NONE_SNA" ;
VAL_ 851 UI_cellNetworkTechnology 15 "CELL_NETWORK_SNA" 14 "CELL_NETWORK_NGRAN" 13 "CELL_NETWORK_5GSA" 12 "CELL_NETWORK_5GNSA" 11 "CELL_NETWORK_LTE5GCN" 10 "CELL_NETWORK_WCDMA" 9 "CELL_NETWORK_CDMA" 8 "CELL_NETWORK_GSM" 7 "CELL_NETWORK_LTE" 6 "CELL_NETWORK_HSPA" 5 "CELL_NETWORK_HSUPA" 4 "CELL_NETWORK_HSDPA" 3 "CELL_NETWORK_UMTS" 2 "CELL_NETWORK_EDGE" 1 "CELL_NETWORK_GPRS" 0 "CELL_NETWORK_NONE" ;
VAL_ 851 UI_cellSignalBars 5 "FIVE" 4 "FOUR" 3 "THREE" 2 "TWO" 1 "ONE" 0 "ZERO" ;
VAL_ 851 UI_trailerModeTelltale 3 "TRAILER_MODE_TELLTALE_RED" 2 "TRAILER_MODE_TELLTALE_YELLOW" 1 "TRAILER_MODE_TELLTALE_BLUE" 0 "TRAILER_MODE_TELLTALE_OFF" ;
VAL_ 991 UI_userActivity 1 "USER_ACTIVE" 0 "USER_IDLE" ;
VAL_ 991 UI_linkState 2 "LINK_STATE_WIFI" 1 "LINK_STATE_CELL" 0 "LINK_STATE_NONE" ;
VAL_ 991 UI_mobileAppConnected 1 "CONNECTED" 0 "NOT_CONNECTED" ;
VAL_ 991 UI_autoshiftDRState 6 "AUTOSHIFT_DR_STATE_BRAKE_GEAR_SHIFT_CONFIRMED_D" 5 "AUTOSHIFT_DR_STATE_BRAKE_GEAR_SHIFT_CONFIRMED_R" 4 "AUTOSHIFT_DR_STATE_BRAKE_STEERING_AND_BRAKE_CONFIRMED" 3 "AUTOSHIFT_DR_STATE_ONLY_STEERING_CONFIRMED" 2 "AUTOSHIFT_DR_STATE_ONLY_BRAKE_CONFIRMED" 1 "AUTOSHIFT_DR_STATE_PROMPT_SHOWING_UNCONFIRMED" 0 "AUTOSHIFT_DR_STATE_INACTIVE" ;
VAL_ 991 UI_wifiBtModuleType 4 "ELEKTRA" 3 "TCU4G" 2 "BCM4359" 1 "QCA6595" 0 "UNKNOWN" ;
VAL_ 991 UI_selfParkState 52 "SELF_PARK_USER_PAUSED" 51 "SELF_PARK_REMOTE_PRE_ABORT" 50 "SELF_PARK_RESUME" 49 "SELF_PARK_PAUSE" 48 "SELF_PARK_DV_MISMATCH" 47 "SELF_PARK_DI_PANIC" 46 "SELF_PARK_POST_ACTIVE_FAILURE" 45 "SELF_PARK_POST_ACTIVE_SUCCESS" 44 "SELF_PARK_CANCEL_AUTO_SUMMON" 43 "SELF_PARK_REMOTE_ABORT" 42 "SELF_PARK_OBSTACLE_NOT_CLEARED" 41 "SELF_PARK_OBSTACLE_CLEARED" 40 "SELF_PARK_OPEN_GATE" 39 "SELF_PARK_ACTIVE" 38 "SELF_PARK_STARTED_REVERSE" 37 "SELF_PARK_STARTED_FORWARD" 36 "SELF_PARK_NOT_STARTED_TIMEOUT" 35 "SELF_PARK_PRIMED" 34 "SELF_PARK_PREPRIMED" 33 "SELF_PARK_TURN_ON_DRIVE_RAIL" 32 "SELF_PARK_DETECT_KEY_FOB" 31 "SELF_PARK_WAKE_UP_BUSES" 30 "SELF_PARK_CONNECTING_BLUETOOTH" 29 "SELF_PARK_UNAVAILABLE_CAR_WASH_MODE" 28 "SELF_PARK_UNAVAILABLE_CAR_ALARM" 27 "SELF_PARK_UNAVAILABLE_CRASH_STATE" 26 "SELF_PARK_UNAVAILABLE_DRAG_STRIP_MODE" 25 "SELF_PARK_UNAVAILABLE_TRACK_MODE" 24 "SELF_PARK_UNAVAILABLE_SERVICE_MODE" 23 "SELF_PARK_UNAVAILABLE_DOG_MODE" 22 "SELF_PARK_UNAVAILABLE_GAME_MODE" 21 "SELF_PARK_UNAVAILABLE_BLUETOOTH_CONNECT_TIMEOUT" 20 "SELF_PARK_UNAVAILABLE_WAKEUP_TIMEOUT" 19 "SELF_PARK_UNAVAILABLE_NO_BLUETOOTH_DEVICES_PAIRED" 18 "SELF_PARK_UNAVAILABLE_BRAKE_PRESSED" 17 "SELF_PARK_UNAVAILABLE_ROAD_GRADE" 16 "SELF_PARK_UNAVAILABLE_TRAILER_MODE" 15 "SELF_PARK_UNAVAILABLE_KEY_FOB_BATTERY_LOW" 14 "SELF_PARK_UNAVAILABLE_KEY_FOB_NOT_DETECTED" 13 "SELF_PARK_UNAVAILABLE_PARK_SENSOR_ISSUE" 12 "SELF_PARK_UNAVAILABLE_AUTOSTEER_NOT_ENABLED" 11 "SELF_PARK_UNAVAILABLE_LV_BUS_SUPPORT_ISSUE" 10 "SELF_PARK_UNAVAILABLE_ON_PUBLIC_ROAD" 9 "SELF_PARK_UNAVAILABLE_PARKED_TOO_LONG" 8 "SELF_PARK_UNAVAILABLE_DOOR_OPEN" 7 "SELF_PARK_UNAVAILABLE_TRUNK_OPEN" 6 "SELF_PARK_UNAVAILABLE_FRUNK_OPEN" 5 "SELF_PARK_UNAVAILABLE_PLUGGED_IN" 4 "SELF_PARK_UNAVAILABLE_NOT_PARKED" 3 "SELF_PARK_UNAVAILABLE" 2 "SELF_PARK_IDLE" 1 "SELF_PARK_DRIVING" 0 "SELF_PARK_DISABLED" ;
VAL_ 991 UI_summonDeviceIndex 3 "UNKNOWN" 2 "DEVICE_2" 1 "DEVICE_1" 0 "DEVICE_0" ;
VAL_ 986 UI_wifiRegDomain 67 "AZ" 66 "SR" 65 "SM" 64 "MS" 63 "MT" 62 "LV" 61 "LT" 60 "LI" 59 "GI" 58 "CY" 57 "AD" 56 "PT" 55 "MU" 54 "LU" 53 "EE" 52 "BG" 51 "BR" 50 "IN" 49 "IE" 48 "IS" 47 "AE" 46 "TR" 45 "ES" 44 "SI" 43 "SK" 42 "RO" 41 "PR" 40 "PL" 39 "HU" 38 "GR" 37 "FI" 36 "HR" 35 "CZ" 34 "NZ" 33 "MO" 32 "SA" 31 "PH" 30 "CO" 29 "QA" 28 "CL" 27 "MY" 26 "TH" 25 "SG" 24 "JO" 23 "MX" 22 "TW" 21 "KR" 20 "RU" 19 "GB" 18 "IL" 17 "AU" 16 "JP" 15 "HK" 14 "CN" 13 "UK" 12 "SE" 11 "CH" 10 "NO" 9 "DK" 8 "BE" 7 "AT" 6 "NL" 5 "IT" 4 "FR" 3 "DE" 2 "CA" 1 "US" 0 "UNKNOWN" ;
VAL_ 663 UI_adaptiveRideRequest 3 "ADAPTIVE_RIDE_REQUEST_ADVANCED" 2 "ADAPTIVE_RIDE_REQUEST_SPORT" 1 "ADAPTIVE_RIDE_REQUEST_AUTO" 0 "ADAPTIVE_RIDE_REQUEST_COMFORT" ;
VAL_ 663 UI_geofenceLevelingRequest 5 "GEOFENCE_LEVELING_REQUEST_SNA" 4 "GEOFENCE_LEVELING_REQUEST_VERY_HIGH_PERSIST" 3 "GEOFENCE_LEVELING_REQUEST_HIGH_PERSIST" 2 "GEOFENCE_LEVELING_REQUEST_VERY_HIGH_TEMPORARY" 1 "GEOFENCE_LEVELING_REQUEST_HIGH_TEMPORARY" 0 "GEOFENCE_LEVELING_REQUEST_NONE" ;
VAL_ 787 UI_trackModeRequest 2 "TRACK_MODE_REQUEST_OFF" 1 "TRACK_MODE_REQUEST_ON" 0 "TRACK_MODE_REQUEST_IDLE" ;
VAL_ 787 UI_trackDrivePowerAvailability 2 "TRACK_MODE_POWER_MAX" 1 "TRACK_MODE_POWER_MIDDLE" 0 "TRACK_MODE_POWER_ENDURANCE" ;
VAL_ 130 UI_navFastchargerType 4 "V4" 3 "V3" 2 "V2" 1 "LOW_POWER" 0 "NONE" ;
VAL_ 130 UI_battPreconditionOnNavState 3 "ACTIVE_COOL" 2 "PASSIVE_COOL" 1 "ACTIVE_HEAT" 0 "PASSIVE_HEAT" ;
VAL_ 627 UI_powerStateRequest 3 "DRIVE_SUMMON" 2 "ACCESSORY_PLUS" 1 "ACCESSORY" 0 "IDLE" ;
VAL_ 627 UI_wiperMode 3 "WIPER_MODE_PARK" 2 "WIPER_MODE_NORMAL" 1 "WIPER_MODE_SERVICE" 0 "WIPER_MODE_SNA" ;
VAL_ 627 UI_steeringButtonMode 7 "STEERING_BUTTON_MODE_SEATS" 6 "STEERING_BUTTON_MODE_WIPERS" 5 "STEERING_BUTTON_MODE_HEADLIGHT_RIGHT" 4 "STEERING_BUTTON_MODE_HEADLIGHT_LEFT" 3 "STEERING_BUTTON_MODE_MIRROR_RIGHT" 2 "STEERING_BUTTON_MODE_MIRROR_LEFT" 1 "STEERING_BUTTON_MODE_STEERING_COLUMN_ADJ" 0 "STEERING_BUTTON_MODE_OFF" ;
VAL_ 627 UI_lockRequest 7 "UI_LOCK_REQUEST_SNA" 4 "UI_LOCK_REQUEST_REMOTE_LOCK" 3 "UI_LOCK_REQUEST_REMOTE_UNLOCK" 2 "UI_LOCK_REQUEST_UNLOCK" 1 "UI_LOCK_REQUEST_LOCK" 0 "UI_LOCK_REQUEST_IDLE" ;
VAL_ 627 UI_mirrorFoldRequest 3 "MIRROR_FOLD_REQUEST_SNA" 2 "MIRROR_FOLD_REQUEST_PRESENT" 1 "MIRROR_FOLD_REQUEST_RETRACT" 0 "MIRROR_FOLD_REQUEST_IDLE" ;
VAL_ 627 UI_remoteStartRequest 4 "UI_REMOTE_START_REQUEST_SNA" 1 "UI_REMOTE_START_REQUEST_START" 0 "UI_REMOTE_START_REQUEST_IDLE" ;
VAL_ 627 UI_frontLeftSeatHeatReq 3 "HEATER_REQUEST_LEVEL3" 2 "HEATER_REQUEST_LEVEL2" 1 "HEATER_REQUEST_LEVEL1" 0 "HEATER_REQUEST_OFF" ;
VAL_ 627 UI_frontRightSeatHeatReq 3 "HEATER_REQUEST_LEVEL3" 2 "HEATER_REQUEST_LEVEL2" 1 "HEATER_REQUEST_LEVEL1" 0 "HEATER_REQUEST_OFF" ;
VAL_ 627 UI_rearLeftSeatHeatReq 3 "HEATER_REQUEST_LEVEL3" 2 "HEATER_REQUEST_LEVEL2" 1 "HEATER_REQUEST_LEVEL1" 0 "HEATER_REQUEST_OFF" ;
VAL_ 627 UI_rearCenterSeatHeatReq 3 "HEATER_REQUEST_LEVEL3" 2 "HEATER_REQUEST_LEVEL2" 1 "HEATER_REQUEST_LEVEL1" 0 "HEATER_REQUEST_OFF" ;
VAL_ 627 UI_rearRightSeatHeatReq 3 "HEATER_REQUEST_LEVEL3" 2 "HEATER_REQUEST_LEVEL2" 1 "HEATER_REQUEST_LEVEL1" 0 "HEATER_REQUEST_OFF" ;
VAL_ 627 UI_remoteClosureRequest 3 "UI_REMOTE_CLOSURE_REQUEST_SNA" 2 "UI_REMOTE_CLOSURE_REQUEST_FRONT_TRUNK_MOVE" 1 "UI_REMOTE_CLOSURE_REQUEST_REAR_TRUNK_MOVE" 0 "UI_REMOTE_CLOSURE_REQUEST_IDLE" ;
VAL_ 627 UI_wiperRequest 6 "WIPER_REQUEST_FAST_CONTINUOUS" 5 "WIPER_REQUEST_SLOW_CONTINUOUS" 4 "WIPER_REQUEST_FAST_INTERMITTENT" 3 "WIPER_REQUEST_SLOW_INTERMITTENT" 2 "WIPER_REQUEST_AUTO" 1 "WIPER_REQUEST_OFF" 0 "WIPER_REQUEST_SNA" ;
VAL_ 627 UI_domeLightSwitch 2 "DOME_LIGHT_SWITCH_AUTO" 1 "DOME_LIGHT_SWITCH_ON" 0 "DOME_LIGHT_SWITCH_OFF" ;
VAL_ 947 UI_lightSwitch 4 "LIGHT_SWITCH_SNA" 3 "LIGHT_SWITCH_OFF" 2 "LIGHT_SWITCH_PARKING" 1 "LIGHT_SWITCH_ON" 0 "LIGHT_SWITCH_AUTO" ;
VAL_ 947 UI_autopilotPowerStateRequest 2 "AUTOPILOT_SUSPEND" 1 "AUTOPILOT_SENTRY" 0 "AUTOPILOT_NOMINAL" ;
VAL_ 947 UI_frontLeftSeatFanReq 3 "FAN_REQUEST_LEVEL3" 2 "FAN_REQUEST_LEVEL2" 1 "FAN_REQUEST_LEVEL1" 0 "FAN_REQUEST_OFF" ;
VAL_ 947 UI_frontRightSeatFanReq 3 "FAN_REQUEST_LEVEL3" 2 "FAN_REQUEST_LEVEL2" 1 "FAN_REQUEST_LEVEL1" 0 "FAN_REQUEST_OFF" ;
VAL_ 947 UI_3RLeftSeatHeatReq 3 "HEATER_REQUEST_LEVEL3" 2 "HEATER_REQUEST_LEVEL2" 1 "HEATER_REQUEST_LEVEL1" 0 "HEATER_REQUEST_OFF" ;
VAL_ 947 UI_3RRightSeatHeatReq 3 "HEATER_REQUEST_LEVEL3" 2 "HEATER_REQUEST_LEVEL2" 1 "HEATER_REQUEST_LEVEL1" 0 "HEATER_REQUEST_OFF" ;
VAL_ 628 UI_lightFlashRequest 3 "LIGHT_FLASH_SENTRY" 2 "LIGHT_FLASH_MOBILE_APP" 1 "LIGHT_FLASH_HOMELINK" 0 "LIGHT_FLASH_INACTIVE" ;
VAL_ 628 UI_steeringWheelHeatLevelReq 3 "STEERING_WHEEL_HEAT_LEVEL3" 2 "STEERING_WHEEL_HEAT_LEVEL2" 1 "STEERING_WHEEL_HEAT_LEVEL1" 0 "STEERING_WHEEL_HEAT_OFF" ;
VAL_ 628 UI_leftRearSeatAdjustmentRequest 6 "UI_ADJUSTABLE_FOLD_FLAT_REQUEST_STOP" 5 "UI_ADJUSTABLE_FOLD_FLAT_REQUEST_TOGGLE_FOLD" 4 "UI_ADJUSTABLE_FOLD_FLAT_REQUEST_REARWARD_FAST" 3 "UI_ADJUSTABLE_FOLD_FLAT_REQUEST_REARWARD_COMFORT" 2 "UI_ADJUSTABLE_FOLD_FLAT_REQUEST_FORWARD_FAST" 1 "UI_ADJUSTABLE_FOLD_FLAT_REQUEST_FORWARD_COMFORT" 0 "UI_ADJUSTABLE_FOLD_FLAT_REQUEST_NONE" ;
VAL_ 628 UI_rightRearSeatAdjustmentReques 6 "UI_ADJUSTABLE_FOLD_FLAT_REQUEST_STOP" 5 "UI_ADJUSTABLE_FOLD_FLAT_REQUEST_TOGGLE_FOLD" 4 "UI_ADJUSTABLE_FOLD_FLAT_REQUEST_REARWARD_FAST" 3 "UI_ADJUSTABLE_FOLD_FLAT_REQUEST_REARWARD_COMFORT" 2 "UI_ADJUSTABLE_FOLD_FLAT_REQUEST_FORWARD_FAST" 1 "UI_ADJUSTABLE_FOLD_FLAT_REQUEST_FORWARD_COMFORT" 0 "UI_ADJUSTABLE_FOLD_FLAT_REQUEST_NONE" ;
VAL_ 628 UI_rearSeatChildLock 3 "UI_ADJUSTABLE_FOLD_FLAT_CHILD_LOCK_BOTH" 2 "UI_ADJUSTABLE_FOLD_FLAT_CHILD_LOCK_RIGHT" 1 "UI_ADJUSTABLE_FOLD_FLAT_CHILD_LOCK_LEFT" 0 "UI_ADJUSTABLE_FOLD_FLAT_CHILD_LOCK_NONE" ;
VAL_ 628 UI_windowRequest 6 "WINDOW_REQUEST_GOTO_RELATIVE_PERCENT" 5 "WINDOW_REQUEST_GOTO_CLOSED_CARWASH" 4 "WINDOW_REQUEST_GOTO_OPEN" 3 "WINDOW_REQUEST_GOTO_CLOSED" 2 "WINDOW_REQUEST_GOTO_VENT" 1 "WINDOW_REQUEST_GOTO_PERCENT" 0 "WINDOW_REQUEST_IDLE" ;
VAL_ 1193 UI_firstRowLeftDomeLightRequest 1 "DOME_LIGHT_REQUEST_ACTIVE" 0 "DOME_LIGHT_REQUEST_NONE" ;
VAL_ 1193 UI_firstRowRightDomeLightRequest 1 "DOME_LIGHT_REQUEST_ACTIVE" 0 "DOME_LIGHT_REQUEST_NONE" ;
VAL_ 1193 UI_secondRowLeftDomeLightRequest 1 "DOME_LIGHT_REQUEST_ACTIVE" 0 "DOME_LIGHT_REQUEST_NONE" ;
VAL_ 1193 UI_secondRowCenterDomeLightReque 1 "DOME_LIGHT_REQUEST_ACTIVE" 0 "DOME_LIGHT_REQUEST_NONE" ;
VAL_ 1193 UI_secondRowRightDomeLightReques 1 "DOME_LIGHT_REQUEST_ACTIVE" 0 "DOME_LIGHT_REQUEST_NONE" ;
VAL_ 1193 UI_thirdRowLeftDomeLightRequest 1 "DOME_LIGHT_REQUEST_ACTIVE" 0 "DOME_LIGHT_REQUEST_NONE" ;
VAL_ 1193 UI_thirdRowRightDomeLightRequest 1 "DOME_LIGHT_REQUEST_ACTIVE" 0 "DOME_LIGHT_REQUEST_NONE" ;
VAL_ 644 UI_transportMode 1 "TRANSPORT_MODE_ENABLED" 0 "TRANSPORT_MODE_DISABLED" ;
VAL_ 644 UI_showroomMode 1 "SHOWROOM_MODE_ENABLED" 0 "SHOWROOM_MODE_DISABLED" ;
VAL_ 644 UI_serviceMode 1 "SERVICE_MODE_ENABLED" 0 "SERVICE_MODE_DISABLED" ;
VAL_ 644 UI_serviceModePlus 1 "SERVICE_MODE_PLUS_ENABLED" 0 "SERVICE_MODE_PLUS_DISABLED" ;
VAL_ 644 UI_lightShowType 5 "LIGHT_SHOW_TYPE_STANDARD_CNY24" 4 "LIGHT_SHOW_TYPE_STANDARD_THE_ARRIVAL" 3 "LIGHT_SHOW_TYPE_STANDARD_CNY23" 2 "LIGHT_SHOW_TYPE_STANDARD_AULD_LANG_SYNE" 1 "LIGHT_SHOW_TYPE_STANDARD_CAROL_OF_THE_BELLS" 0 "LIGHT_SHOW_TYPE_CUSTOM_USB" ;
VAL_ 644 UI_upkeepMode 1 "UI_UPKEEPMODE_ENABLED" 0 "UI_UPKEEPMODE_DISABLED" ;
VAL_ 595 UI_ventPanelLeftLateralMode 2 "SWING" 1 "SPLIT" 0 "SINGLE" ;
VAL_ 595 UI_ventPanelRightLateralMode 2 "SWING" 1 "SPLIT" 0 "SINGLE" ;
VAL_ 595 UI_hvacReqActiveVents 3 "OFF" 2 "RIGHT" 1 "LEFT" 0 "BOTH" ;
VAL_ 595 UI_hvacReqThirdRowState 2 "ON" 1 "OFF" 0 "AUTO" ;
